VERSION ""

NS_ :

BS_:
BU_: ME SC01 BMS01 BMS PT
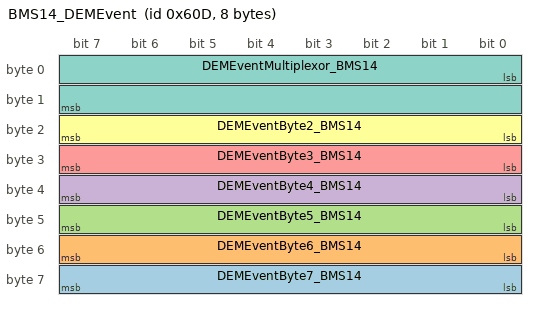
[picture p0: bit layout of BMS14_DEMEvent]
BO_ 1549 BMS14_DEMEvent: 8 BMS14
 SG_ DEMEventByte7_BMS14 : 63|8@0+ (1,0) [0|0] ""  PT
 SG_ DEMEventByte6_BMS14 : 55|8@0+ (1,0) [0|0] ""  PT
 SG_ DEMEventByte5_BMS14 : 47|8@0+ (1,0) [0|0] ""  PT
 SG_ DEMEventByte4_BMS14 : 39|8@0+ (1,0) [0|0] ""  PT
 SG_ DEMEventByte3_BMS14 : 31|8@0+ (1,0) [0|0] ""  PT
 SG_ DEMEventByte2_BMS14 : 23|8@0+ (1,0) [0|0] ""  PT
 SG_ DEMEventMultiplexor_BMS14 M : 0|16@1+ (1,0) [0|0] ""  PT

BO_ 1037 BMS14_DebugEventMap1: 8 BMS14
 SG_ DEM001_POWERUP_BMS14 : 11|2@0+ (1,0) [0|0] ""  PT
 SG_ DEM002_VOLTAGE_BRICK_OV_BMS14 : 13|2@0+ (1,0) [0|0] ""  PT
 SG_ DEM003_VOLTAGE_BRICK_UV_BMS14 : 15|2@0+ (1,0) [0|0] ""  PT
 SG_ DEM004_VOLTAGE_BRICK_SNA_BMS14 : 1|2@0+ (1,0) [0|0] ""  PT
 SG_ DEM005_VOLTAGE_BRICK_IMBAL_BMS14 : 3|2@0+ (1,0) [0|0] ""  PT
 SG_ DEM006_VOLTAGE_CAPCY_IMBAL_BMS14 : 5|2@0+ (1,0) [0|0] ""  PT
 SG_ DEM007_MODULET_HIGH_DELTA_BMS14 : 7|2@0+ (1,0) [0|0] ""  PT
 SG_ DEM008_VOLTAGE_PACK_UV_BMS14 : 25|2@0+ (1,0) [0|0] ""  PT
 SG_ DEM009_VOLTAGE_PACK_OV_BMS14 : 27|2@0+ (1,0) [0|0] ""  PT
 SG_ DEM010_VOLTAGE_PACK_PLAUSI_BMS14 : 29|2@0+ (1,0) [0|0] ""  PT
 SG_ DEM011_VOLTAGE_PCKLINK_MIS_BMS14 : 31|2@0+ (1,0) [0|0] ""  PT
 SG_ DEM012_VOLTAGE_BMS_SUPPLY_BMS14 : 17|2@0+ (1,0) [0|0] ""  PT
 SG_ DEM013_ADC_ERROR_BMS14 : 19|2@0+ (1,0) [0|0] ""  PT
 SG_ DEM014_MODULET_OT_BMS14 : 21|2@0+ (1,0) [0|0] ""  PT
 SG_ DEM015_MODULET_SNA_BMS14 : 23|2@0+ (1,0) [0|0] ""  PT
 SG_ DEM016_MODULET_LIMPHOME_BMS14 : 41|2@0+ (1,0) [0|0] ""  PT
 SG_ DEM017_COOLING_SYS_LHOME_BMS14 : 43|2@0+ (1,0) [0|0] ""  PT
 SG_ DEM018_HVIL_LIMPHOME_BMS14 : 45|2@0+ (1,0) [0|0] ""  PT
 SG_ DEM019_HVIL_ESS_INHIBIT_BMS14 : 47|2@0+ (1,0) [0|0] ""  PT
 SG_ DEM020_MODULET_CHANGE_BMS14 : 33|2@0+ (1,0) [0|0] ""  PT
 SG_ DEM021_LG_MAVD_FAULT_BMS14 : 35|2@0+ (1,0) [0|0] ""  PT
 SG_ DEM022_LG_RDV_FAULT_BMS14 : 37|2@0+ (1,0) [0|0] ""  PT
 SG_ DEM023_BMS_ONBOARDT_SNA_BMS14 : 39|2@0+ (1,0) [0|0] ""  PT
 SG_ DEM024_BMS_ONBOARDRH_OH_BMS14 : 57|2@0+ (1,0) [0|0] ""  PT
 SG_ DEM025_BMS_ONBOARDRH_SNA_BMS14 : 59|2@0+ (1,0) [0|0] ""  PT
 SG_ DEM026_CURRENT_OVERCHARGE_BMS14 : 61|2@0+ (1,0) [0|0] ""  PT
 SG_ DEM027_CURRENT_OVERDISCHGE_BMS14 : 63|2@0+ (1,0) [0|0] ""  PT
 SG_ DEM028_CURRENT_INVALID_BMS14 : 49|2@0+ (1,0) [0|0] ""  PT
 SG_ DEM029_CURRENT_SHORTCIRCT_BMS14 : 51|2@0+ (1,0) [0|0] ""  PT
 SG_ DEM030_CRASH_CAN_LATCH_BMS14 : 53|2@0+ (1,0) [0|0] ""  PT
 SG_ DEM031_EEPROM_FAIL_BMS14 : 55|2@0+ (1,0) [0|0] ""  PT

BO_ 1101 BMS14_DebugEventMap2: 8 BMS14
 SG_ DEM032_PCHG_PACKS_CONNECT_BMS14 : 9|2@0+ (1,0) [0|0] ""  PT
 SG_ DEM033_PCHG_ILLEGAL_PRCHG_BMS14 : 11|2@0+ (1,0) [0|0] ""  PT
 SG_ DEM034_PCHG_RELAY_FAIL_BMS14 : 13|2@0+ (1,0) [0|0] ""  PT
 SG_ DEM035_PCHG_NEG_WELD_BMS14 : 15|2@0+ (1,0) [0|0] ""  PT
 SG_ DEM036_PCHG_NEG_PULLIN_BMS14 : 1|2@0+ (1,0) [0|0] ""  PT
 SG_ DEM037_PCHG_SHORTCIRCUIT_BMS14 : 3|2@0+ (1,0) [0|0] ""  PT
 SG_ DEM038_PCHG_OPENCIRCUIT_BMS14 : 5|2@0+ (1,0) [0|0] ""  PT
 SG_ DEM039_PCHG_TIMEOUT_BMS14 : 7|2@0+ (1,0) [0|0] ""  PT
 SG_ DEM040_PCHG_FAILED_BMS14 : 25|2@0+ (1,0) [0|0] ""  PT
 SG_ DEM041_HVIL_SHUTDOWN_BMS14 : 27|2@0+ (1,0) [0|0] ""  PT
 SG_ DEM042_PCHG_POS_WELD_BMS14 : 29|2@0+ (1,0) [0|0] ""  PT
 SG_ DEM043_HV_LOCK_TRANSPORT_BMS14 : 31|2@0+ (1,0) [0|0] ""  PT
 SG_ DEM044_CTRS_END_OF_LIFE_BMS14 : 17|2@0+ (1,0) [0|0] ""  PT
 SG_ DEM045_CTRS_CTRPWRV_HI_BMS14 : 19|2@0+ (1,0) [0|0] ""  PT
 SG_ DEM046_CTRS_COILCURR_LOW_BMS14 : 21|2@0+ (1,0) [0|0] ""  PT
 SG_ DEM047_CTRS_COILCURR_HIGH_BMS14 : 23|2@0+ (1,0) [0|0] ""  PT
 SG_ DEM048_CTRS_CTRPWRV_LOW_BMS14 : 41|2@0+ (1,0) [0|0] ""  PT
 SG_ DEM049_CHGE_ILLEGAL_DISCHG_BMS14 : 43|2@0+ (1,0) [0|0] ""  PT
 SG_ DEM050_STARTUP_CONDITIONS_BMS14 : 45|2@0+ (1,0) [0|0] ""  PT
 SG_ DEM051_VOLTAGE_BMS_SUPPLYH_BMS14 : 47|2@0+ (1,0) [0|0] ""  PT
 SG_ DEM052_SAFETYSPI_FAIL_BMS14 : 33|2@0+ (1,0) [0|0] ""  PT
 SG_ DEM053_WATCHDOG_ERRORPIN_BMS14 : 35|2@0+ (1,0) [0|0] ""  PT
 SG_ DEM054_SAFESTATE_TRIGGERED_BMS14 : 37|2@0+ (1,0) [0|0] ""  PT
 SG_ DEM055_DEBUG_CMND_ACTIVE_BMS14 : 39|2@0+ (1,0) [0|0] ""  PT
 SG_ DEM056_CRASH_CAN_BMS14 : 57|2@0+ (1,0) [0|0] ""  PT
 SG_ DEM057_ISO_EXT_STRAT_4_BMS14 : 59|2@0+ (1,0) [0|0] ""  PT
 SG_ DEM058_ISO_EXT_RES_ERR_BMS14 : 61|2@0+ (1,0) [0|0] ""  PT
 SG_ DEM059_ISO_EXT_RES_WARN_BMS14 : 63|2@0+ (1,0) [0|0] ""  PT
 SG_ DEM060_ISO_INT_RES_ERR_BMS14 : 49|2@0+ (1,0) [0|0] ""  PT
 SG_ DEM061_ISO_INT_RES_WARN_BMS14 : 51|2@0+ (1,0) [0|0] ""  PT
 SG_ DEM062_EMERGENCY_OPERATION_BMS14 : 53|2@0+ (1,0) [0|0] ""  PT
 SG_ DEM063_ENDOFDRIVE_BMS14 : 55|2@0+ (1,0) [0|0] ""  PT

BO_ 1165 BMS14_DebugEventMap3: 8 BMS14
 SG_ DEM064_STRINGV_IMBALANCE_BMS14 : 9|2@0+ (1,0) [0|0] ""  PT
 SG_ DEM065_STRING_FAULT_BMS14 : 11|2@0+ (1,0) [0|0] ""  PT
 SG_ DEM066_ESS_FAULT_BMS14 : 13|2@0+ (1,0) [0|0] ""  PT
 SG_ DEM067_ISO_EXT_STRAT_3_BMS14 : 15|2@0+ (1,0) [0|0] ""  PT
 SG_ DEM068_MODULE_COUNT_INVALI_BMS14 : 1|2@0+ (1,0) [0|0] ""  PT
 SG_ DEM069_PT_MIA_BMS14 : 3|2@0+ (1,0) [0|0] ""  PT
 SG_ DEM070_BMSMIA_STRNGMSTR_01_BMS14 : 5|2@0+ (1,0) [0|0] ""  PT
 SG_ DEM071_BMSMIA_STRNGMSTR_05_BMS14 : 7|2@0+ (1,0) [0|0] ""  PT
 SG_ DEM072_BMSMIA_STRNGMSTR_09_BMS14 : 25|2@0+ (1,0) [0|0] ""  PT
 SG_ DEM073_BMSMIA_STRNGMSTR_13_BMS14 : 27|2@0+ (1,0) [0|0] ""  PT
 SG_ DEM074_BMSMIA_STRNGMSTR_17_BMS14 : 29|2@0+ (1,0) [0|0] ""  PT
 SG_ DEM075_BMSMIA_STRNGMSTR_21_BMS14 : 31|2@0+ (1,0) [0|0] ""  PT
 SG_ DEM076_BMSMIA_STRNGMSTR_25_BMS14 : 17|2@0+ (1,0) [0|0] ""  PT
 SG_ DEM077_BMSMIA_STRNGMSTR_29_BMS14 : 19|2@0+ (1,0) [0|0] ""  PT
 SG_ DEM078_BMSMIA_STRNGMSTR_33_BMS14 : 21|2@0+ (1,0) [0|0] ""  PT
 SG_ DEM079_BMSMIA_STRNGMSTR_37_BMS14 : 23|2@0+ (1,0) [0|0] ""  PT
 SG_ DEM080_BMSMIA_STRNGMSTR_41_BMS14 : 41|2@0+ (1,0) [0|0] ""  PT
 SG_ DEM081_BMSMIA_STRNGMSTR_45_BMS14 : 43|2@0+ (1,0) [0|0] ""  PT
 SG_ DEM082_BMSMIA_STRNGMSTR_49_BMS14 : 45|2@0+ (1,0) [0|0] ""  PT
 SG_ DEM083_BMSMIA_STRNGMSTR_53_BMS14 : 47|2@0+ (1,0) [0|0] ""  PT
 SG_ DEM084_BMSMIA_STRNGMSTR_57_BMS14 : 33|2@0+ (1,0) [0|0] ""  PT
 SG_ DEM085_BMSMIA_STRNGMSTR_61_BMS14 : 35|2@0+ (1,0) [0|0] ""  PT
 SG_ DEM086_ESSCURRENT_SHORT_BMS14 : 37|2@0+ (1,0) [0|0] ""  PT
 SG_ DEM087_PT_MIA_SHUTDOWN_BMS14 : 39|2@0+ (1,0) [0|0] ""  PT
 SG_ DEM088_OUTLET_NTC_HI_BMS14 : 57|2@0+ (1,0) [0|0] ""  PT
 SG_ DEM089_OUTLET_NTC_LO_BMS14 : 59|2@0+ (1,0) [0|0] ""  PT
 SG_ DEM090_BMSMIA_ESSMASTER_BMS14 : 61|2@0+ (1,0) [0|0] ""  PT
 SG_ DEM091_PCHG_RES_OVERHEAT_BMS14 : 63|2@0+ (1,0) [0|0] ""  PT
 SG_ DEM092_BMSMIA_STRNGSLAVE_0_BMS14 : 49|2@0+ (1,0) [0|0] ""  PT
 SG_ DEM093_BMSMIA_STRNGSLAVE_1_BMS14 : 51|2@0+ (1,0) [0|0] ""  PT
 SG_ DEM094_BMSMIA_STRNGSLAVE_2_BMS14 : 53|2@0+ (1,0) [0|0] ""  PT
 SG_ DEM095_BMSMIA_STRNGSLAVE_3_BMS14 : 55|2@0+ (1,0) [0|0] ""  PT

BO_ 1229 BMS14_DebugEventMap4: 8 BMS14
 SG_ DEM096_SC_STATE_SELFTEST_BMS14 : 9|2@0+ (1,0) [0|0] ""  PT
 SG_ DEM097_SC_STATE_TEMP_BMS14 : 11|2@0+ (1,0) [0|0] ""  PT
 SG_ DEM098_SC_STATE_VOLTAGE_BMS14 : 13|2@0+ (1,0) [0|0] ""  PT
 SG_ DEM099_SC_STATE_HVIL_BMS14 : 15|2@0+ (1,0) [0|0] ""  PT
 SG_ DEM100_SC_STATE_CONTACTORS_BMS14 : 1|2@0+ (1,0) [0|0] ""  PT
 SG_ DEM101_SC_STATE_CURRENT_BMS14 : 3|2@0+ (1,0) [0|0] ""  PT
 SG_ DEM102_SC_STATE_CANRX_BMS14 : 5|2@0+ (1,0) [0|0] ""  PT
 SG_ DEM103_SC_STATE_CRASH_BMS14 : 7|2@0+ (1,0) [0|0] ""  PT
 SG_ DEM104_SC_STATE_CCTRL_BMS14 : 25|2@0+ (1,0) [0|0] ""  PT
 SG_ DEM105_SC_STATE_CANTX_BMS14 : 27|2@0+ (1,0) [0|0] ""  PT
 SG_ DEM106_SC_STATE_THERMALEVT_BMS14 : 29|2@0+ (1,0) [0|0] ""  PT
 SG_ DEM107_SC_STATE_COOLANT_BMS14 : 31|2@0+ (1,0) [0|0] ""  PT
 SG_ DEM108_SC_SELFTEST_SFTY_UC_BMS14 : 17|2@0+ (1,0) [0|0] ""  PT
 SG_ DEM109_SC_TEMP_HIGH_BMS14 : 19|2@0+ (1,0) [0|0] ""  PT
 SG_ DEM110_SC_TEMP_NTC_OPEN_BMS14 : 21|2@0+ (1,0) [0|0] ""  PT
 SG_ DEM111_SC_TEMP_NTC_SHORT_BMS14 : 23|2@0+ (1,0) [0|0] ""  PT
 SG_ DEM112_CMB_DISCONNECTED_BMS14 : 41|2@0+ (1,0) [0|0] ""  PT
 SG_ DEM113_CMB_DEFECT_BMS14 : 43|2@0+ (1,0) [0|0] ""  PT
 SG_ DEM114_CMB_COMMERROR_BMS14 : 45|2@0+ (1,0) [0|0] ""  PT
 SG_ DEM115_SC_CURR_HALL_PWR_LO_BMS14 : 47|2@0+ (1,0) [0|0] ""  PT
 SG_ DEM116_SC_CURR_HALL_VHIGH_BMS14 : 33|2@0+ (1,0) [0|0] ""  PT
 SG_ DEM117_SC_CURR_HALL_ADC_BMS14 : 35|2@0+ (1,0) [0|0] ""  PT
 SG_ DEM118_SC_CURR_HALL_VLOW_BMS14 : 37|2@0+ (1,0) [0|0] ""  PT
 SG_ DEM119_SC_CURR_ISENSE_PWR_BMS14 : 39|2@0+ (1,0) [0|0] ""  PT
 SG_ DEM120_SC_CURR_ISENSE1_MIA_BMS14 : 57|2@0+ (1,0) [0|0] ""  PT
 SG_ DEM121_SC_CURR_ISENSE2_MIA_BMS14 : 59|2@0+ (1,0) [0|0] ""  PT
 SG_ DEM122_SC_CURR_ISENSE3_MIA_BMS14 : 61|2@0+ (1,0) [0|0] ""  PT
 SG_ DEM123_SC_CURR_ISENSE4_MIA_BMS14 : 63|2@0+ (1,0) [0|0] ""  PT
 SG_ DEM124_SC_CURR_ISENSE5_MIA_BMS14 : 49|2@0+ (1,0) [0|0] ""  PT
 SG_ DEM125_SC_CURR_ISENSE1_FLT_BMS14 : 51|2@0+ (1,0) [0|0] ""  PT
 SG_ DEM126_SC_CURR_ISENSE2_FLT_BMS14 : 53|2@0+ (1,0) [0|0] ""  PT
 SG_ DEM127_SC_CURR_ISENSE3_FLT_BMS14 : 55|2@0+ (1,0) [0|0] ""  PT

BO_ 1293 BMS14_DebugEventMap5: 8 BMS14
 SG_ DEM128_SC_CURR_ISENSE4_FLT_BMS14 : 9|2@0+ (1,0) [0|0] ""  PT
 SG_ DEM129_SC_CURR_ISENSE5_FLT_BMS14 : 11|2@0+ (1,0) [0|0] ""  PT
 SG_ DEM130_SC_CURR_OFFSET_BMS14 : 13|2@0+ (1,0) [0|0] ""  PT
 SG_ DEM131_SC_CURR_PLAUSI_BMS14 : 15|2@0+ (1,0) [0|0] ""  PT
 SG_ DEM132_SC_CURR_CHARGE_HIGH_BMS14 : 1|2@0+ (1,0) [0|0] ""  PT
 SG_ DEM133_SC_CURR_DSCHAR_HIGH_BMS14 : 3|2@0+ (1,0) [0|0] ""  PT
 SG_ DEM134_SC_V_CMB_SUMOFCELL_BMS14 : 5|2@0+ (1,0) [0|0] ""  PT
 SG_ DEM135_SC_V_SENSE_OPENWIRE_BMS14 : 7|2@0+ (1,0) [0|0] ""  PT
 SG_ DEM136_SC_V_CMB_DRV_FROZEN_BMS14 : 25|2@0+ (1,0) [0|0] ""  PT
 SG_ DEM137_SC_V_PACK_PLAUSI_BMS14 : 27|2@0+ (1,0) [0|0] ""  PT
 SG_ DEM138_SC_HVIL_HW_FLT_BMS14 : 29|2@0+ (1,0) [0|0] ""  PT
 SG_ DEM139_SC_HVIL_OPEN_BMS14 : 31|2@0+ (1,0) [0|0] ""  PT
 SG_ DEM140_SC_HVIL_TO_SUP_BMS14 : 17|2@0+ (1,0) [0|0] ""  PT
 SG_ DEM141_SC_HVIL_TO_CHAS_BMS14 : 19|2@0+ (1,0) [0|0] ""  PT
 SG_ DEM142_SC_HVIL_R_HIGH_BMS14 : 21|2@0+ (1,0) [0|0] ""  PT
 SG_ DEM143_SC_HVIL_SHORT_BMS14 : 23|2@0+ (1,0) [0|0] ""  PT
 SG_ DEM144_SC_CN_ISO_FAIL_BMS14 : 41|2@0+ (1,0) [0|0] ""  PT
 SG_ DEM145_HVIL_SYS_BMS14 : 43|2@0+ (1,0) [0|0] ""  PT
 SG_ DEM146_SC_CN_POS1_WELDED_BMS14 : 45|2@0+ (1,0) [0|0] ""  PT
 SG_ DEM147_SC_CN_NEG1_WELDED_BMS14 : 47|2@0+ (1,0) [0|0] ""  PT
 SG_ DEM148_SC_CN_POS2_WELDED_BMS14 : 33|2@0+ (1,0) [0|0] ""  PT
 SG_ DEM149_SC_CN_NEG2_WELDED_BMS14 : 35|2@0+ (1,0) [0|0] ""  PT
 SG_ DEM150_SC_CN_POS3_WELDED_BMS14 : 37|2@0+ (1,0) [0|0] ""  PT
 SG_ DEM151_SC_CN_NEG3_WELDED_BMS14 : 39|2@0+ (1,0) [0|0] ""  PT
 SG_ DEM152_SC_CN_HIGH_CY_BMS14 : 57|2@0+ (1,0) [0|0] ""  PT
 SG_ DEM153_SC_CN_ISOANDPOTWELD_BMS14 : 59|2@0+ (1,0) [0|0] ""  PT
 SG_ DEM154_SC_TEMP_PLAUSI_BMS14 : 61|2@0+ (1,0) [0|0] ""  PT
 SG_ DEM155_SC_CURR_HALL_PWR_HI_BMS14 : 63|2@0+ (1,0) [0|0] ""  PT
 SG_ DEM156_SC_PYRO_TRIGGERED_BMS14 : 49|2@0+ (1,0) [0|0] ""  PT
 SG_ DEM157_SC_PYRO_OPEN_BMS14 : 51|2@0+ (1,0) [0|0] ""  PT
 SG_ DEM158_AUX_CTRS_END_OF_LIF_BMS14 : 53|2@0+ (1,0) [0|0] ""  PT
 SG_ DEM159_SC_CANRX_PT_MIA_BMS14 : 55|2@0+ (1,0) [0|0] ""  PT

BO_ 1357 BMS14_DebugEventMap6: 8 BMS14
 SG_ DEM160_SC_CANRX_PT_CRCALIV_BMS14 : 9|2@0+ (1,0) [0|0] ""  PT
 SG_ DEM161_SC_CANRX_LIN_SHUTDN_BMS14 : 11|2@0+ (1,0) [0|0] ""  PT
 SG_ DEM162_SC_CANRX_LIN_MIA_BMS14 : 13|2@0+ (1,0) [0|0] ""  PT
 SG_ DEM163_SC_CRASH1_BMS14 : 15|2@0+ (1,0) [0|0] ""  PT
 SG_ DEM164_SC_CRASH2_BMS14 : 1|2@0+ (1,0) [0|0] ""  PT
 SG_ DEM165_SC_CRASHCAN_BMS14 : 3|2@0+ (1,0) [0|0] ""  PT
 SG_ DEM166_SC_CCTRL_SELFTEST_BMS14 : 5|2@0+ (1,0) [0|0] ""  PT
 SG_ DEM167_SC_CCTRL_DRIVER_FAU_BMS14 : 7|2@0+ (1,0) [0|0] ""  PT
 SG_ DEM168_SC_CCTRL_HISIDESTCL_BMS14 : 25|2@0+ (1,0) [0|0] ""  PT
 SG_ DEM169_SC_CCTRL_HISIDESTOP_BMS14 : 27|2@0+ (1,0) [0|0] ""  PT
 SG_ DEM170_SC_CCTRL_LOSIDESTCL_BMS14 : 29|2@0+ (1,0) [0|0] ""  PT
 SG_ DEM171_SC_CCTRL_HVCNDITION_BMS14 : 31|2@0+ (1,0) [0|0] ""  PT
 SG_ DEM172_SC_CCTRL_POS1_OPN_BMS14 : 17|2@0+ (1,0) [0|0] ""  PT
 SG_ DEM173_SC_CCTRL_POS2_OPN_BMS14 : 19|2@0+ (1,0) [0|0] ""  PT
 SG_ DEM174_SC_CCTRL_POS3_OPN_BMS14 : 21|2@0+ (1,0) [0|0] ""  PT
 SG_ DEM175_SC_CCTRL_NEG1_OPN_BMS14 : 23|2@0+ (1,0) [0|0] ""  PT
 SG_ DEM176_SC_CCTRL_NEG2_OPN_BMS14 : 41|2@0+ (1,0) [0|0] ""  PT
 SG_ DEM177_SC_CCTRL_PRE2_OPN_BMS14 : 43|2@0+ (1,0) [0|0] ""  PT
 SG_ DEM178_SC_CCTRL_PRE1_OPN_BMS14 : 45|2@0+ (1,0) [0|0] ""  PT
 SG_ DEM179_SC_CCTRL_LOSIDESTOP_BMS14 : 47|2@0+ (1,0) [0|0] ""  PT
 SG_ DEM180_SC_CCTRL_UNEXPECTED_BMS14 : 33|2@0+ (1,0) [0|0] ""  PT
 SG_ DEM181_SC_V_OUT_OF_RANGE_BMS14 : 35|2@0+ (1,0) [0|0] ""  PT
 SG_ DEM182_SC_V_LATCHED_UVOV_BMS14 : 37|2@0+ (1,0) [0|0] ""  PT
 SG_ DEM183_ISO_EXT_STRAT_2_BMS14 : 39|2@0+ (1,0) [0|0] ""  PT
 SG_ DEM184_SC_CANTX_CTRS_BMS14 : 57|2@0+ (1,0) [0|0] ""  PT
 SG_ DEM185_SC_CANTX_HVIL_BMS14 : 59|2@0+ (1,0) [0|0] ""  PT
 SG_ DEM186_SC_CANTX_ISOL_BMS14 : 61|2@0+ (1,0) [0|0] ""  PT
 SG_ DEM187_SC_SBC_WATCHDOG_BMS14 : 63|2@0+ (1,0) [0|0] ""  PT
 SG_ DEM188_SC_SBC_FAULT_BMS14 : 49|2@0+ (1,0) [0|0] ""  PT
 SG_ DEM189_SC_WATCHDOG_BMS14 : 51|2@0+ (1,0) [0|0] ""  PT
 SG_ DEM190_SC_SELFTEST_RAM_BMS14 : 53|2@0+ (1,0) [0|0] ""  PT
 SG_ DEM191_SC_SELFTEST_FLASH_BMS14 : 55|2@0+ (1,0) [0|0] ""  PT

BO_ 1421 BMS14_DebugEventMap7: 8 BMS14
 SG_ DEM192_CMB_ONBOARDRH_OH_BMS14 : 9|2@0+ (1,0) [0|0] ""  PT
 SG_ DEM193_CMB_ONBOARDRH_SNA_BMS14 : 11|2@0+ (1,0) [0|0] ""  PT
 SG_ DEM194_CMB_ONBOARDT_OT_BMS14 : 13|2@0+ (1,0) [0|0] ""  PT
 SG_ DEM195_CMB_ONBOARDT_CHANGE_BMS14 : 15|2@0+ (1,0) [0|0] ""  PT
 SG_ DEM196_PRESSURE_CHANGE_BMS14 : 1|2@0+ (1,0) [0|0] ""  PT
 SG_ DEM197_PRESSURE_OVER_BMS14 : 3|2@0+ (1,0) [0|0] ""  PT
 SG_ DEM198_PRESSURE_UNDER_BMS14 : 5|2@0+ (1,0) [0|0] ""  PT
 SG_ DEM199_PRESSURE_INVALID_BMS14 : 7|2@0+ (1,0) [0|0] ""  PT
 SG_ DEM200_THERMAL_EVENT_BMS14 : 25|2@0+ (1,0) [0|0] ""  PT
 SG_ DEM201_CMB_ONBOARDT_SNA_BMS14 : 27|2@0+ (1,0) [0|0] ""  PT
 SG_ DEM202_REPLACE_DESICCANT_BMS14 : 29|2@0+ (1,0) [0|0] ""  PT
 SG_ DEM203_COOLANT_FLOOD_FAULT_BMS14 : 31|2@0+ (1,0) [0|0] ""  PT
 SG_ DEM204_LOW_BRICKCAPACITY_BMS14 : 17|2@0+ (1,0) [0|0] ""  PT
 SG_ DEM205_BMS_ONBOARDT_OT_BMS14 : 19|2@0+ (1,0) [0|0] ""  PT
 SG_ DEM206_HUMIDITY_CHANGE_BMS14 : 21|2@0+ (1,0) [0|0] ""  PT
 SG_ DEM207_ISENSE_SUPPLY_CURR_BMS14 : 23|2@0+ (1,0) [0|0] ""  PT
 SG_ DEM208_SOC_LOW_BMS14 : 41|2@0+ (1,0) [0|0] ""  PT
 SG_ DEM209_SOC_TOOLOW_BMS14 : 43|2@0+ (1,0) [0|0] ""  PT
 SG_ DEM210_SOC_TOOHIGH_BMS14 : 45|2@0+ (1,0) [0|0] ""  PT
 SG_ DEM211_BALANCING_REQUIRED_BMS14 : 47|2@0+ (1,0) [0|0] ""  PT
 SG_ DEM212_DEEP_DISCHARGE_BMS14 : 33|2@0+ (1,0) [0|0] ""  PT
 SG_ DEM213_CAN1_BUS_OFF_BMS14 : 35|2@0+ (1,0) [0|0] ""  PT
 SG_ DEM214_CAN2_BUS_OFF_BMS14 : 37|2@0+ (1,0) [0|0] ""  PT
 SG_ DEM215_CAN3_BUS_OFF_BMS14 : 39|2@0+ (1,0) [0|0] ""  PT
 SG_ DEM216_OUTLET_NTC_RATNAL_BMS14 : 57|2@0+ (1,0) [0|0] ""  PT
 SG_ DEM217_FUSE_PACK_BMS14 : 59|2@0+ (1,0) [0|0] ""  PT
 SG_ DEM218_FUSE_B_OPEN_BMS14 : 61|2@0+ (1,0) [0|0] ""  PT
 SG_ DEM219_FUSE_C_OPEN_BMS14 : 63|2@0+ (1,0) [0|0] ""  PT
 SG_ DEM220_FUSE_D_OPEN_BMS14 : 49|2@0+ (1,0) [0|0] ""  PT
 SG_ DEM221_FUSE_E_OPEN_BMS14 : 51|2@0+ (1,0) [0|0] ""  PT
 SG_ DEM222_PUMP_DRY_RUN_BMS14 : 53|2@0+ (1,0) [0|0] ""  PT
 SG_ DEM223_PUMP_PERFORMANCE_BMS14 : 55|2@0+ (1,0) [0|0] ""  PT

BO_ 1485 BMS14_DebugEventMap8: 8 BMS14
 SG_ DEM224_PUMP_LIN_FAILURE_BMS14 : 9|2@0+ (1,0) [0|0] ""  PT
 SG_ DEM225_PUMP_SUPPLY_VOLTAGE_BMS14 : 11|2@0+ (1,0) [0|0] ""  PT
 SG_ DEM226_PUMP_RECOVERY_FAIL_BMS14 : 13|2@0+ (1,0) [0|0] ""  PT
 SG_ DEM227_CTR_POS_OPENED_BMS14 : 15|2@0+ (1,0) [0|0] ""  PT
 SG_ DEM228_CTR_NEG_OPENED_BMS14 : 1|2@0+ (1,0) [0|0] ""  PT
 SG_ DEM229_STRSET_SLAVE1_FAULT_BMS14 : 3|2@0+ (1,0) [0|0] ""  PT
 SG_ DEM230_STRSET_SLAVE2_FAULT_BMS14 : 5|2@0+ (1,0) [0|0] ""  PT
 SG_ DEM231_CTRSAUX_CLFAIL_HVON_BMS14 : 7|2@0+ (1,0) [0|0] ""  PT
 SG_ DEM232_CTRSAUX_CLFAIL_VDIF_BMS14 : 25|2@0+ (1,0) [0|0] ""  PT
 SG_ DEM233_CTRSAUX_POS1_OPENED_BMS14 : 27|2@0+ (1,0) [0|0] ""  PT
 SG_ DEM234_CTRSAUX_NEG1_OPENED_BMS14 : 29|2@0+ (1,0) [0|0] ""  PT
 SG_ DEM235_CTRSAUX_POS1_WELDED_BMS14 : 31|2@0+ (1,0) [0|0] ""  PT
 SG_ DEM236_CTRSAUX_NEG1_WELDED_BMS14 : 17|2@0+ (1,0) [0|0] ""  PT
 SG_ DEM237_CTRSAUX_POS1_PULLIN_BMS14 : 19|2@0+ (1,0) [0|0] ""  PT
 SG_ DEM238_CTRSAUX_NEG1_PULLIN_BMS14 : 21|2@0+ (1,0) [0|0] ""  PT
 SG_ DEM239_INLET_NTC_RATNAL_BMS14 : 23|2@0+ (1,0) [0|0] ""  PT
 SG_ DEM240_INLET_NTC_HI_BMS14 : 41|2@0+ (1,0) [0|0] ""  PT
 SG_ DEM241_INLET_NTC_LO_BMS14 : 43|2@0+ (1,0) [0|0] ""  PT
 SG_ DEM242_VOLTAGE_LINK2_RATNA_BMS14 : 45|2@0+ (1,0) [0|0] ""  PT
 SG_ DEM243_VOLTAGE_LINK2_HI_BMS14 : 47|2@0+ (1,0) [0|0] ""  PT
 SG_ DEM244_VOLTAGE_LINK2_LO_BMS14 : 33|2@0+ (1,0) [0|0] ""  PT
 SG_ DEM245_CMB_ONBOARD_IMPOSSI_BMS14 : 35|2@0+ (1,0) [0|0] ""  PT
 SG_ DEM246_VOLTAGE_LINK1_HI_BMS14 : 37|2@0+ (1,0) [0|0] ""  PT
 SG_ DEM247_VOLTAGE_LINK1_LO_BMS14 : 39|2@0+ (1,0) [0|0] ""  PT
 SG_ DEM248_NTC_SUPPLY_LO_BMS14 : 57|2@0+ (1,0) [0|0] ""  PT
 SG_ DEM249_NTC_SUPPLY_HI_BMS14 : 59|2@0+ (1,0) [0|0] ""  PT
 SG_ DEM250_VOLTAGE_LINK3_RATNA_BMS14 : 61|2@0+ (1,0) [0|0] ""  PT
 SG_ DEM251_VOLTAGE_LINK3_HI_BMS14 : 63|2@0+ (1,0) [0|0] ""  PT
 SG_ DEM252_VOLTAGE_LINK3_LO_BMS14 : 49|2@0+ (1,0) [0|0] ""  PT
 SG_ DEM253_BALANCING_STUCK_BMS14 : 51|2@0+ (1,0) [0|0] ""  PT
 SG_ DEM254_ARM_EXCEPTION_BMS14 : 53|2@0+ (1,0) [0|0] ""  PT
 SG_ DEM255_ERROR_HOOKS_BMS14 : 55|2@0+ (1,0) [0|0] ""  PT

BO_ 845 BMS14_DebugEventMap9: 8 BMS14
 SG_ DEM256_XCP_CAL_CHANGE_BMS14 : 9|2@0+ (1,0) [0|0] ""  PT
 SG_ DEM257_XCP_CAL_PERM_CHANGE_BMS14 : 11|2@0+ (1,0) [0|0] ""  PT
 SG_ DEM258_TASK_TIME_OVERFLOW_BMS14 : 13|2@0+ (1,0) [0|0] ""  PT
 SG_ DEM259_ISO_CIRCUIT_BMS14 : 15|2@0+ (1,0) [0|0] ""  PT
 SG_ DEM260_COOLANT_MOIST_FAULT_BMS14 : 1|2@0+ (1,0) [0|0] ""  PT
 SG_ DEM261_COOLANT_FLOOD_WARN_BMS14 : 3|2@0+ (1,0) [0|0] ""  PT
 SG_ DEM262_COOLANT_MOIST_WARN_BMS14 : 5|2@0+ (1,0) [0|0] ""  PT
 SG_ DEM263_MODULET_IMPLAUSIBLE_BMS14 : 7|2@0+ (1,0) [0|0] ""  PT
 SG_ DEM264_REQUEST_ON_WITH_HV__BMS14 : 25|2@0+ (1,0) [0|0] ""  PT
 SG_ DEM265_CSERS_PCODE_BMS14 : 27|2@0+ (1,0) [0|0] ""  PT
 SG_ DEM266_PRELIM_CNTR_CL_FAIL_BMS14 : 29|2@0+ (1,0) [0|0] ""  PT
 SG_ DEM267_FLUIDLVL_LOW_BMS14 : 31|2@0+ (1,0) [0|0] ""  PT
 SG_ DEM268_FLUIDLVL_FAILURE_BMS14 : 17|2@0+ (1,0) [0|0] ""  PT
 SG_ DEM269_SC_COOLANT_CONTAM_BMS14 : 19|2@0+ (1,0) [0|0] ""  PT
 SG_ DEM270_SC_COOLANT_MIA_BMS14 : 21|2@0+ (1,0) [0|0] ""  PT
 SG_ DEM271_PRESSURE_VHI_BMS14 : 23|2@0+ (1,0) [0|0] ""  PT
 SG_ DEM272_PRESSURE_VLO_BMS14 : 41|2@0+ (1,0) [0|0] ""  PT
 SG_ DEM273_SC_COOLANT_FAIL_BMS14 : 43|2@0+ (1,0) [0|0] ""  PT
 SG_ DEM274_CTRSAUX_POS2_OPENED_BMS14 : 45|2@0+ (1,0) [0|0] ""  PT
 SG_ DEM275_CTRSAUX_POS3_OPENED_BMS14 : 47|2@0+ (1,0) [0|0] ""  PT
 SG_ DEM276_CTRSAUX_POS2_WELDED_BMS14 : 33|2@0+ (1,0) [0|0] ""  PT
 SG_ DEM277_CTRSAUX_POS3_WELDED_BMS14 : 35|2@0+ (1,0) [0|0] ""  PT
 SG_ DEM278_CTRSAUX_POS2_PULLIN_BMS14 : 37|2@0+ (1,0) [0|0] ""  PT
 SG_ DEM279_CTRSAUX_POS3_PULLIN_BMS14 : 39|2@0+ (1,0) [0|0] ""  PT
 SG_ DEM280_CMB_HUMIDITY_TEMP_C_BMS14 : 57|2@0+ (1,0) [0|0] ""  PT
 SG_ DEM281_THERMAL_EVENT_CMB_R_BMS14 : 59|2@0+ (1,0) [0|0] ""  PT
 SG_ DEM282_CUS_BRICKOV_BMS14 : 61|2@0+ (1,0) [0|0] ""  PT
 SG_ DEM283_CUS_BRICKUV_BMS14 : 63|2@0+ (1,0) [0|0] ""  PT
 SG_ DEM284_CUS_OVERCHRG_BMS14 : 49|2@0+ (1,0) [0|0] ""  PT
 SG_ DEM285_CUS_OVERDCHRG_BMS14 : 51|2@0+ (1,0) [0|0] ""  PT
 SG_ DEM286_CUS_CURRENT_CHG_BMS14 : 53|2@0+ (1,0) [0|0] ""  PT
 SG_ DEM287_CUS_CURRENT_DCHG_BMS14 : 55|2@0+ (1,0) [0|0] ""  PT

BO_ 1613 SC14_DebugSlowMpex: 8 SC14
 SG_ FeeInitStatus_SC14 m43 : 23|16@0+ (1,0) [0|65535] ""  PT
 SG_ pressureFiltered_SC14 m22 : 47|8@0+ (0.4,0) [0|102] "psi"  PT
 SG_ shunt2IntegralAs_SC14 m46 : 23|32@0- (1,0) [-2147483648|2147483647] "As"  PT
 SG_ shunt1IntegralAs_SC14 m45 : 31|32@0- (1,0) [-2147483648|2147483647] "As"  PT
 SG_ selfTestStartupFault_SC14 m22 : 39|8@0+ (1,0) [0|255] ""  PT
 SG_ sbcARTimerStatus_SC14 m45 : 11|4@0+ (1,0) [0|15] ""  PT
 SG_ sbcARTimerValue_SC14 m45 : 23|8@0+ (1,0) [0|255] "s"  PT
 SG_ ESM_EFUSE_SAFETY_CHECK_FAIL_SC14 m21 : 41|1@0+ (1,0) [0|0] ""  PT
 SG_ ESM_EFUSE_SINGLEBIT_ERROR_SC14 m21 : 42|1@0+ (1,0) [0|0] ""  PT
 SG_ cmbVAIndex_SC14 m44 : 31|8@0+ (1,0) [0|0] ""  PT
 SG_ minVACMB_SC14 m44 : 39|16@0+ (0.0001,0) [0|6.5] "V"  PT
 SG_ maxVACMB_SC14 m44 : 55|16@0+ (0.0001,0) [0|6.5] "V"  PT
 SG_ pumpInternalFaultError_SC14 m23 : 16|1@0+ (1,0) [0|0] ""  PT
 SG_ pumpShortCircuitError_SC14 m23 : 17|1@0+ (1,0) [0|0] ""  PT
 SG_ pumpElectricError_SC14 m23 : 19|2@0+ (1,0) [0|0] ""  PT
 SG_ pumpPostRunMode_SC14 m23 : 22|3@0+ (1,0) [0|0] ""  PT
 SG_ pumpRsError_SC14 m23 : 23|1@0+ (1,0) [0|0] ""  PT
 SG_ pumpWakeUpStatus_SC14 m23 : 25|2@0+ (1,0) [0|0] ""  PT
 SG_ pumpRpmMonStat_SC14 m23 : 27|2@0+ (1,0) [0|0] ""  PT
 SG_ pumpPwmInStat_SC14 m23 : 29|2@0+ (1,0) [0|0] ""  PT
 SG_ pumpDiagTriggered_SC14 m23 : 30|1@0+ (1,0) [0|0] ""  PT
 SG_ pumpHwFault_SC14 m23 : 31|1@0+ (1,0) [0|0] ""  PT
 SG_ pumpPumpState_SC14 m23 : 34|3@0+ (1,0) [0|0] ""  PT
 SG_ pumpBlockError_SC14 m23 : 36|2@0+ (1,0) [0|0] ""  PT
 SG_ pumpLinError_SC14 m23 : 37|1@0+ (1,0) [0|0] ""  PT
 SG_ pumpDryRun_SC14 m23 : 39|2@0+ (1,0) [0|0] ""  PT
 SG_ pumpOverCurrent_SC14 m23 : 41|2@0+ (1,0) [0|0] ""  PT
 SG_ pumpVoltageDeratingError_SC14 m23 : 42|1@0+ (1,0) [0|0] ""  PT
 SG_ pumpSupVoltageError_SC14 m23 : 44|2@0+ (1,0) [0|0] ""  PT
 SG_ pumpUnderVoltage_SC14 m23 : 45|1@0+ (1,0) [0|0] ""  PT
 SG_ pumpOverVoltage_SC14 m23 : 46|1@0+ (1,0) [0|0] ""  PT
 SG_ pumpTempProtect_SC14 m23 : 47|1@0+ (1,0) [0|0] ""  PT
 SG_ pumpOverTempDeratingErr_SC14 m23 : 48|1@0+ (1,0) [0|0] ""  PT
 SG_ pumpOverTemperature_SC14 m23 : 50|2@0+ (1,0) [0|0] ""  PT
 SG_ cmbSM30MinSettleTime_SC14 m44 : 15|16@0+ (1,0) [0|65535] "ms"  PT
 SG_ cmbSM30SettleTimeFault_SC14 m32 : 42|1@0+ (1,0) [0|1] ""  PT
 SG_ pressure2_SC14 m22 : 15|8@0+ (0.4,0) [0|102] "psi"  PT
 SG_ cmbSM29ScoutTempIndex_SC14 m42 : 15|8@0+ (1,0) [0|255] ""  PT
 SG_ cmbSM19ScoutPDO_SC14 m42 : 55|16@0+ (0.0001,0) [0|6.5] "V"  PT
 SG_ cmbMaxSM15ratio_SC14 m41 : 39|16@0+ (0.00390625,0) [0|255.99609375] ""  PT
 SG_ cmbMinSM15ratio_SC14 m41 : 55|16@0+ (0.00390625,0) [0|255.99609375] ""  PT
 SG_ cmbMinSM17Ratio m42 : 39|16@0+ (0.00390625,0) [0|255.99609375] ""  PT
 SG_ cmbMaxSM17Ratio m42 : 23|16@0+ (0.00390625,0) [0|255.99609375] ""  PT
 SG_ cmbMaxSM16DiffC2S_SC14 m41 : 23|16@0+ (0.2,0) [0|13107] "mV"  PT
 SG_ isolationResInternRelaxed_SC14 m32 : 23|16@0+ (2,0) [0|130000] "kOhm"  PT
 SG_ pressureSensH2Concentr_SC14 m40 : 55|16@0+ (0.0025,0) [0|163.8375] "% H2"  PT
 SG_ pressureSensIntakePres_SC14 m40 : 39|16@0+ (0.0078125,-250) [-250|251.99] "kPa"  PT
 SG_ pressureSensIntakeTemp_SC14 m40 : 23|16@0+ (0.03125,-273) [-273|1734.96875] "C"  PT
 SG_ pressureSensRelHumidity_SC14 m40 : 15|8@0+ (0.4,0) [0|100] "%"  PT
 SG_ isolationSelftestMaxDiff_SC14 m32 : 39|8@0+ (0.1,0) [0|25.5] "V"  PT
 SG_ FEESector2Flags_SC14 m22 : 23|16@0+ (1,0) [0|0] ""  PT
 SG_ appTask500HzMaxAvg_SC14 m41 : 15|8@0+ (0.02,0) [0|5.1] "ms"  PT
 SG_ safetyHangLastLinkReg_SC14 m39 : 23|32@0+ (1,0) [0|4294967295] ""  PT
 SG_ safetyHangPresentLinkReg_SC14 m38 : 23|32@0+ (1,0) [0|4294967295] ""  PT
 SG_ safetyHangDataFaultStatus_SC14 m37 : 23|32@0+ (1,0) [0|4294967295] ""  PT
 SG_ safetyHangDataFaultAddr_SC14 m36 : 23|32@0+ (1,0) [0|4294967295] ""  PT
 SG_ safetyHangLastARMMode_SC14 m35 : 63|8@0+ (1,0) [0|255] ""  PT
 SG_ safetyHangPresARMMode_SC14 m35 : 55|8@0+ (1,0) [0|255] ""  PT
 SG_ safetyHangESMGrp3Reg_SC14 m35 : 23|32@0+ (1,0) [0|4294967295] ""  PT
 SG_ safetyHangInstrFaultStatus_SC14 m34 : 23|32@0+ (1,0) [0|4294967295] ""  PT
 SG_ safetyHangInstrFaultAddr_SC14 m33 : 23|32@0+ (1,0) [0|4294967295] ""  PT
 SG_ pressure_SC14 m4 : 63|8@0+ (0.4,0) [0|102] "psi"  PT
 SG_ cmbMaxSM33Diff_SC14 m31 : 15|8@0+ (0.001,0) [0|0.255] "V"  PT
 SG_ cmbMinSM29Diff_SC14 m17 : 15|8@0+ (0.001,0) [0|0.255] "V"  PT
 SG_ cmbSM4MinIndex_SC14 m24 : 15|8@0+ (1,0) [0|0] ""  PT
 SG_ cmbSM4DiffC2_SC14 m31 : 23|16@0+ (0.0001,0) [0|6.5] "V"  PT
 SG_ cmbMinSM4Diff_SC14 m31 : 39|16@0+ (0.0001,0) [0|6.5] "V"  PT
 SG_ cmbMaxSM4Diff_SC14 m21 : 55|16@0+ (0.0001,0) [0|6.5] "V"  PT
 SG_ cmbSM27MinIndex_SC14 m15 : 63|8@0+ (1,0) [0|0] ""  PT
 SG_ cmbSM27DiffC2_SC14 m24 : 55|16@0+ (0.0001,0) [0|6.5] "V"  PT
 SG_ cmbMinSM27Diff_SC14 m31 : 55|16@0+ (0.0001,0) [0|6.5] "V"  PT
 SG_ cmbMaxSM27Diff_SC14 m25 : 55|16@0+ (0.0001,0) [0|6.5] "V"  PT
 SG_ adcDriverFail_SC14 m4 : 51|4@0+ (1,0) [0|0] ""  PT
 SG_ mainUcHvilState_SC14 m32 : 41|2@0+ (1,0) [0|0] ""  PT
 SG_ mainUcIntIsoErr_SC14 m32 : 13|2@0+ (1,0) [0|0] ""  PT
 SG_ mainUcExtIsoErr_SC14 m32 : 15|2@0+ (1,0) [0|0] ""  PT
 SG_ safetyUcThermalStatus_SC14 m32 : 9|2@0+ (1,0) [0|0] ""  PT
 SG_ mainUcThermalStatus_SC14 m32 : 11|2@0+ (1,0) [0|0] ""  PT
 SG_ selfTestErrorAddress_SC14 m30 : 23|32@0+ (1,0) [0|4294967295] ""  PT
 SG_ selfTestDataFaultStatus_SC14 m29 : 23|32@0+ (1,0) [0|4294967295] ""  PT
 SG_ selfTestInstrFaultAddr_SC14 m28 : 23|32@0+ (1,0) [0|4294967295] ""  PT
 SG_ selfTestDataFaultAddr_SC14 m27 : 23|32@0+ (1,0) [0|4294967295] ""  PT
 SG_ selfTestInstrFaultStatus_SC14 m26 : 23|32@0+ (1,0) [0|4294967295] ""  PT
 SG_ internalIsolationError_SC14 m25 : 11|2@0+ (1,0) [0|0] ""  PT
 SG_ externalIsolationError_SC14 m25 : 13|2@0+ (1,0) [0|0] ""  PT
 SG_ isolationTestState_SC14 m25 : 9|2@0+ (1,0) [0|0] ""  PT
 SG_ isolationResistanceIntern_SC14 m25 : 23|16@0+ (2,0) [0|130000] "kOhm"  PT
 SG_ isolationResistanceExtern_SC14 m25 : 39|16@0+ (2,0) [0|130000] "kOhm"  PT
 SG_ maxAdolV13Diff_SC14 m24 : 23|16@0+ (0.0001,0) [0|6.5] "V"  PT
 SG_ maxAdolV7Diff_SC14 m24 : 39|16@0+ (0.0001,0) [0|6.5] "V"  PT
 SG_ pumpType_SC14 m23 : 15|8@0+ (1,0) [0|0] ""  PT
 SG_ pumpPhaseCurrent_SC14 m18 : 47|8@0+ (0.1,0) [0|0] "A"  PT
 SG_ hvWithstandTestQual_SC14 m21 : 15|8@0+ (1,0) [0|255] ""  PT
 SG_ ESM_RAM_ODD_ADDR_UNCORR_SC14 m21 : 18|1@0+ (1,0) [0|0] ""  PT
 SG_ ESM_RAM_EVEN_ADDR_UNCORR_SC14 m21 : 17|1@0+ (1,0) [0|0] ""  PT
 SG_ ESM_FMC_UNCORR_ERR_SC14 m21 : 40|1@0+ (1,0) [0|0] ""  PT
 SG_ ESM_RAM_ODDECC_UNCORR_SC14 m21 : 23|1@0+ (1,0) [0|0] ""  PT
 SG_ ESM_RAM_EVENECC_UNCORR_SC14 m21 : 22|1@0+ (1,0) [0|0] ""  PT
 SG_ ESM_EFUSE_FARM_ERR_SC14 m21 : 21|1@0+ (1,0) [0|0] ""  PT
 SG_ ESM_RTI_WWD_NMI_SC14 m21 : 20|1@0+ (1,0) [0|0] ""  PT
 SG_ ESM_TCM_ECC_LIVE_LOCK_SC14 m21 : 19|1@0+ (1,0) [0|0] ""  PT
 SG_ ESM_RAM_ODD_UNCORR_ERR_SC14 m21 : 16|1@0+ (1,0) [0|0] ""  PT
 SG_ ESM_RAM_EVEN_UNCORR_ERR_SC14 m21 : 31|1@0+ (1,0) [0|0] ""  PT
 SG_ ESM_FMC_ADDR_UNCORR_ERR_SC14 m21 : 30|1@0+ (1,0) [0|0] ""  PT
 SG_ ESM_CCM4_COMPARE_FAULT_SC14 m21 : 29|1@0+ (1,0) [0|0] ""  PT
 SG_ ESM_RAM_ODD_CORR_ERR_SC14 m21 : 28|1@0+ (1,0) [0|0] ""  PT
 SG_ ESM_RAM_EVEN_CORR_ERR_SC14 m21 : 27|1@0+ (1,0) [0|0] ""  PT
 SG_ ESM_CLK_MONITOR_SC14 m21 : 26|1@0+ (1,0) [0|0] ""  PT
 SG_ ESM_PLL_SLIP_SC14 m21 : 25|1@0+ (1,0) [0|0] ""  PT
 SG_ ESM_FMC_CORR_ERR_SC14 m21 : 24|1@0+ (1,0) [0|0] ""  PT
 SG_ analogMMCUSleepTrigger_SC14 m20 : 55|8@0+ (0.015,0) [0|0] "V"  PT
 SG_ analogPyroLSDStatus_SC14 m20 : 63|8@0+ (0.015,0) [0|0] "V"  PT
 SG_ analogGPIO2Volt_SC14 m19 : 47|8@0+ (0.1,0) [0|25] "V"  PT
 SG_ analogGPIO2Current_SC14 m19 : 55|8@0+ (0.015,0) [0|3.825] "A"  PT
 SG_ analogGPIO1Volt_SC14 m19 : 63|8@0+ (0.1,0) [0|25] "V"  PT
 SG_ analogGPIO1Current_SC14 m20 : 15|8@0+ (0.015,0) [0|3.825] "A"  PT
 SG_ currentModuleMax_SC14 m1 : 55|16@0+ (0.1,-3200) [-3200|3200] "A"  PT
 SG_ currentModuleMin_SC14 m1 : 39|16@0+ (0.1,-3200) [-3200|3200] "A"  PT
 SG_ cmbSumOfCellSTATRef_SC14 m20 : 39|16@0+ (0.0015,0) [0|131.07] "V"  PT
 SG_ cmbSumOfCells_SC14 m20 : 23|16@0+ (0.0015,0) [0|131.07] "V"  PT
 SG_ maxCMBDieTemp_SC14 m1 : 31|8@0+ (1,-40) [-40|200] "C"  PT
 SG_ minCMBDieTemp_SC14 m1 : 23|8@0+ (1,-40) [-40|200] "C"  PT
 SG_ appTaskSpiRxTx_SC14 m16 : 15|8@0+ (0.02,0) [0|5.1] "ms"  PT
 SG_ variantCodingCounts_SC14 m4 : 39|8@0+ (1,0) [0|0] ""  PT
 SG_ cmbMaxUpdateTime_SC14 m17 : 23|8@0+ (2,0) [0|500] "ms"  PT
 SG_ pumpSetSpeed_SC14 m18 : 55|8@0+ (1,0) [0|255] "PCT"  PT
 SG_ hvilResistance_SC14 m17 : 31|8@0+ (2,0) [0|0] "Ohm"  PT
 SG_ cmbAvgUpdateTime_SC14 m18 : 63|8@0+ (2,0) [0|500] "ms"  PT
 SG_ pumpTemperature_SC14 m18 : 39|8@0+ (1,-50) [0|0] "C"  PT
 SG_ pumpSpeed_SC14 m18 : 15|8@0+ (1,0) [0|255] "PCT"  PT
 SG_ pumpVoltage_SC14 m18 : 23|8@0+ (0.1,0) [0|0] "V"  PT
 SG_ pumpCurrent_SC14 m18 : 31|8@0+ (0.1,0) [0|0] "A"  PT
 SG_ posLink3_SC14 m17 : 39|16@0+ (0.04,-1250) [-1250|1371.4] "V"  PT
 SG_ negLink3_SC14 m17 : 55|16@0+ (0.04,-1250) [-1250|1371.4] "V"  PT
 SG_ posLink2_SC14 m16 : 39|16@0+ (0.04,-1250) [-1250|1371.4] "V"  PT
 SG_ negLink2_SC14 m16 : 55|16@0+ (0.04,-1250) [-1250|1371.4] "V"  PT
 SG_ cmbNrOfSamples_SC14 m16 : 23|8@0+ (1,0) [0|0] ""  PT
 SG_ cmbTaskTime_SC14 m16 : 31|8@0+ (1,0) [0|0] "ms"  PT
 SG_ appTask500HzMax_SC14 m15 : 15|8@0+ (0.02,0) [0|5.1] "ms"  PT
 SG_ moduleCount_SC14 m6 : 15|8@0+ (1,0) [0|0] ""  PT
 SG_ analogHallSense_SC14 m15 : 23|16@0+ (0.0001,0) [0|6.5535] "V"  PT
 SG_ cmbMaxDiagStepPeriodicity_SC14 m15 : 55|8@0+ (4,0) [0|1019] "ms"  PT
 SG_ minBrickVoltageLimit_SC14 m15 : 39|16@0+ (0.0001,0) [0|6.5535] "V"  PT
 SG_ appTask100Hz_SC14 m14 : 63|8@0+ (0.02,0) [0|5.1] "ms"  PT
 SG_ appTask10Hz_SC14 m14 : 55|8@0+ (0.02,0) [0|5.1] "ms"  PT
 SG_ appTaskAnalog_SC14 m14 : 47|8@0+ (0.02,0) [0|5.1] "ms"  PT
 SG_ appTaskADC_SC14 m14 : 39|8@0+ (0.02,0) [0|5.1] "ms"  PT
 SG_ appTask500HzAvg_SC14 m14 : 31|8@0+ (0.02,0) [0|5.1] "ms"  PT
 SG_ appTaskSBC_SC14 m14 : 23|8@0+ (0.02,0) [0|5.1] "ms"  PT
 SG_ appTaskCMBDriver_SC14 m14 : 15|8@0+ (0.02,0) [0|5.1] "ms"  PT
 SG_ safetyInitTime_SC14 m12 : 15|8@0+ (2,0) [0|500] "ms"  PT
 SG_ debugSlowMpex_SC14 M : 7|8@0+ (1,0) [0|0] ""  PT
 SG_ sbcWUAuto_SC14 m11 : 9|1@0+ (1,0) [0|0] ""  PT
 SG_ sbcWUUnknown_SC14 m11 : 8|1@0+ (1,0) [0|0] ""  PT
 SG_ sbcWUDebug_SC14 m11 : 10|1@0+ (1,0) [0|0] ""  PT
 SG_ sbcWUPOR_SC14 m11 : 11|1@0+ (1,0) [0|0] ""  PT
 SG_ sbcWUPressure_SC14 m11 : 12|1@0+ (1,0) [0|0] ""  PT
 SG_ sbcWUClock_SC14 m11 : 13|1@0+ (1,0) [0|0] ""  PT
 SG_ sbcWUCAN_SC14 m11 : 14|1@0+ (1,0) [0|0] ""  PT
 SG_ sbcWUKey_SC14 m11 : 15|1@0+ (1,0) [0|0] ""  PT
 SG_ mux960N3VRef_SC14 m13 : 39|16@0+ (-0.000805664,0) [0|0] "V"  PT
 SG_ mux960P2P5VRef_SC14 m13 : 55|16@0+ (0.000805664,0) [0|0] "V"  PT
 SG_ mux440Gnd_SC14 m10 : 15|8@0+ (0.000805664,0) [0|0] "V"  PT
 SG_ analogHallGain_SC14 m13 : 23|16@0+ (1E-005,0.8) [0.8|1.455] "k"  PT
 SG_ analogHallOffset_SC14 m13 : 15|8@0+ (0.0001,-0.005) [-0.005|0.0205] "V"  PT
 SG_ negPackPrime_SC14 m12 : 55|16@0+ (0.04,-1250) [-1250|1250] "V"  PT
 SG_ posPackPrime_SC14 m12 : 39|16@0+ (0.04,-1250) [-1250|1250] "V"  PT
 SG_ packVoltage_SC14 m12 : 23|16@0+ (0.04,-1250) [-1250|1250] "V"  PT
 SG_ sleepTime_SC14 m11 : 23|16@0+ (1,0) [0|0] "s"  PT
 SG_ analogNegHVOffset_SC14 m10 : 63|8@0+ (1,-120) [-120|120] "Bits"  PT
 SG_ analogPosHVOffset_SC14 m10 : 55|8@0+ (1,-120) [-120|120] "Bits"  PT
 SG_ analogNegHVGain_SC14 m10 : 39|16@0+ (1E-005,0.8) [0|0] "k"  PT
 SG_ analogPosHVGain_SC14 m10 : 23|16@0+ (1E-005,0.8) [0.8|1.45535] "k"  PT
 SG_ mux910Gnd_SC14 m8 : 15|8@0+ (0.000805664,0) [0|0] "V"  PT
 SG_ mux960Gnd_SC14 m9 : 15|8@0+ (0.000805664,0) [0|0] "V"  PT
 SG_ analogAddr5_SC14 m9 : 55|16@0+ (0.000805861,0) [0|0] "V"  PT
 SG_ analogAddr4_SC14 m9 : 39|16@0+ (0.000805861,0) [0|0] "V"  PT
 SG_ analogAddr3_SC14 m9 : 23|16@0+ (0.000805861,0) [0|0] "V"  PT
 SG_ analogAddr2_SC14 m8 : 55|16@0+ (0.000805861,0) [0|0] "V"  PT
 SG_ analogAddr1_SC14 m8 : 39|16@0+ (0.000805861,0) [0|0] "V"  PT
 SG_ analogAddr0_SC14 m8 : 23|16@0+ (0.000805861,0) [0|0] "V"  PT
 SG_ sbcVREF2P5_SC14 m7 : 15|8@0+ (0.003222656,2.25) [2.25|3.0715] "V"  PT
 SG_ mux910N3VRef_SC14 m7 : 39|16@0+ (-0.000805664,0) [0|0] "V"  PT
 SG_ mux910P2P5VRef_SC14 m7 : 55|16@0+ (0.000805664,0) [0|0] "V"  PT
 SG_ analogHvilCurrentPWM_SC14 m3 : 31|8@0+ (1,0) [0|255] "mA"  PT
 SG_ analogSBCSupply_SC14 m4 : 47|8@0+ (0.1,0) [0|25] "V"  PT
 SG_ analogHvilCurrent_SC14 m3 : 23|8@0+ (1,0) [0|255] "mA"  PT
 SG_ analogPressureSense_SC14 m4 : 23|8@0+ (0.025,0) [0|6.375] "V"  PT
 SG_ analog5VSensorSupply_SC14 m4 : 15|8@0+ (0.025,0) [0|6.375] "V"  PT
 SG_ analogPrechgRel2CoilMinus_SC14 m2 : 23|8@0+ (0.2,0) [0|51] "V"  PT
 SG_ analogPrechgRel1CoilMinus_SC14 m3 : 55|8@0+ (0.2,0) [0|51] "V"  PT
 SG_ analogNegCntr3CoilMinus_SC14 m2 : 31|8@0+ (0.2,0) [0|51] "V"  PT
 SG_ analogNegCntr2CoilMinus_SC14 m2 : 39|8@0+ (0.2,0) [0|51] "V"  PT
 SG_ analogNegCntr1CoilMinus_SC14 m2 : 47|8@0+ (0.2,0) [0|51] "V"  PT
 SG_ analogPosCntr3CoilMinus_SC14 m2 : 55|8@0+ (0.2,0) [0|51] "V"  PT
 SG_ analogPosCntr2CoilMinus_SC14 m2 : 63|8@0+ (0.2,0) [0|51] "V"  PT
 SG_ analogPosCntr1CoilMinus_SC14 m3 : 15|8@0+ (0.2,0) [0|51] "V"  PT
 SG_ minModuleTemperature_SC14 m1 : 15|8@0+ (1,-40) [-40|200] "C"  PT
 SG_ maxModuleTemperature_SC14 m2 : 15|8@0+ (1,-40) [-40|200] "C"  PT
 SG_ analogHvilReturn_SC14 m3 : 39|8@0+ (0.1,0) [0|25] "V"  PT
 SG_ analog5VDSupply_SC14 m3 : 47|8@0+ (0.025,0) [0|6.375] "V"  PT
 SG_ analogHvilOut_SC14 m3 : 63|8@0+ (0.1,0) [0|25] "V"  PT
 SG_ analogCurrentSensor12V_SC14 m4 : 31|8@0+ (0.075,0) [0|19] "V"  PT
 SG_ cmbErrorCounter_SC14 m6 : 47|8@0+ (1,0) [0|255] ""  PT
 SG_ PECErrorCounter_SC14 m6 : 39|8@0+ (1,0) [0|255] ""  PT
 SG_ maxVREF2_SC14 m7 : 23|16@0+ (0.0001,0) [0|6.5] "V"  PT
 SG_ minVREF2_SC14 m6 : 55|16@0+ (0.0001,0) [0|6.5] "V"  PT
 SG_ currentPlausiCounter_SC14 m5 : 15|8@0+ (1,0) [0|0] ""  PT
 SG_ hallCurrentOffset_SC14 m5 : 39|16@0+ (0.001,-30) [-30|30] "A"  PT
 SG_ sumOfCurrentsFiltered_SC14 m5 : 23|16@0+ (0.1,-3200) [-3200|3353.5] "A"  PT
 SG_ hallCurrentAveraged_SC14 m5 : 55|16@0+ (0.1,-3200) [-3200|3200] "A"  PT
 SG_ analogHallSupply_SC14 m6 : 23|16@0+ (0.0005,0) [0|32.7675] "V"  PT
 SG_ SWVersion_SC14 m11 : 39|32@0+ (1,0) [0|4294967295] ""  PT
 SG_ contactorControlPos1_SC14 m19 : 23|4@0+ (1,0) [0|7] ""  PT
 SG_ contactorControlNeg1_SC14 m19 : 19|4@0+ (1,0) [0|7] ""  PT
 SG_ contactorControlPre1_SC14 m19 : 11|4@0+ (1,0) [0|7] ""  PT
 SG_ contactorControlPos2_SC14 m19 : 31|4@0+ (1,0) [0|7] ""  PT
 SG_ contactorControlNeg2_SC14 m19 : 27|4@0+ (1,0) [0|7] ""  PT
 SG_ contactorControlPre2_SC14 m19 : 15|4@0+ (1,0) [0|7] ""  PT
 SG_ contactorControlPos3_SC14 m19 : 39|4@0+ (1,0) [0|7] ""  PT
 SG_ contactorControlNeg3_SC14 m19 : 35|4@0+ (1,0) [0|7] ""  PT

BO_ 1677 SC14_DebugFastMpex: 8 SC14
 SG_ selfTestFaultCntrCtrl_SC14 m11 : 23|8@0+ (1,0) [0|0] ""  PT
 SG_ cmbASICFault_SC14 m11 : 15|8@0+ (1,0) [0|0] ""  PT
 SG_ DIGIO_PYRO_LSD_EN_SC14 m2 : 12|1@0+ (1,0) [0|0] ""  PT
 SG_ mainUcExtIsoResistance_SC14 m10 : 55|16@0+ (1,0) [0|0] "KOhm"  PT
 SG_ BMS_C38_AR2MsgFault_SC14 m10 : 47|2@0+ (1,0) [0|0] ""  PT
 SG_ stateCoolant_SC14 m10 : 45|1@0+ (1,0) [0|0] ""  PT
 SG_ stateThermalEvent_SC14 m10 : 44|1@0+ (1,0) [0|0] ""  PT
 SG_ stateCANTx_SC14 m10 : 43|1@0+ (1,0) [0|0] ""  PT
 SG_ CANTxFaultTriggerFailed_SC14 m10 : 42|1@0+ (1,0) [0|0] ""  PT
 SG_ CANTxBMS1ST3MsgFault_SC14 m10 : 10|1@0+ (1,0) [0|0] ""  PT
 SG_ CANTxBMSDispReqMsgFault_SC14 m10 : 9|1@0+ (1,0) [0|0] ""  PT
 SG_ CANTxHVBatMsgFault_SC14 m10 : 8|1@0+ (1,0) [0|0] ""  PT
 SG_ mainUcCntrCtrlReq_SC14 m10 : 41|2@0+ (1,0) [0|0] ""  PT
 SG_ mainUcCntrWeldState_SC14 m10 : 39|4@0+ (1,0) [0|0] ""  PT
 SG_ safetyUcCntrState_SC14 m10 : 33|2@0+ (1,0) [0|0] ""  PT
 SG_ mainUcCntrState_SC14 m10 : 35|2@0+ (1,0) [0|0] ""  PT
 SG_ safetyCANMsg4Fault_SC14 m10 : 31|4@0+ (1,0) [0|0] ""  PT
 SG_ safetyCANMsg3Fault_SC14 m10 : 27|4@0+ (1,0) [0|0] ""  PT
 SG_ safetyCANMsg2Fault_SC14 m10 : 23|4@0+ (1,0) [0|0] ""  PT
 SG_ safetyCANMsg1Fault_SC14 m10 : 19|4@0+ (1,0) [0|0] ""  PT
 SG_ cmbBalancingDesired_SC14 m10 : 15|1@0+ (1,0) [0|0] ""  PT
 SG_ DIGIO_GPIO1_ON_SC14 m2 : 10|1@0+ (1,0) [0|0] ""  PT
 SG_ DIGIO_ZDW_LSD_EN_SC14 m2 : 11|1@0+ (1,0) [0|0] ""  PT
 SG_ currentShortCircuit_SC14 m2 : 9|1@0+ (1,0) [0|0] ""  PT
 SG_ contactorCntrSelfTest_SC14 m10 : 14|4@0+ (1,0) [0|15] ""  PT
 SG_ maxBrickVoltage_SC14 m11 : 39|16@0+ (0.0001,0) [0|6.5] "V"  PT
 SG_ minBrickVoltage_SC14 m11 : 55|16@0+ (0.0001,0) [0|6.5] "V"  PT
 SG_ cmbLastUpdateTime_SC14 m0 : 55|8@0+ (2,0) [0|500] "ms"  PT
 SG_ weldCheckState_SC14 m2 : 15|3@0+ (1,0) [0|0] ""  PT
 SG_ debugFastMpex_SC14 M : 7|8@0+ (1,0) [0|0] ""  PT
 SG_ SPIRxTxTimeAllPckts_SC14 m0 : 63|8@0+ (2,0) [0|500] "ms"  PT
 SG_ sleepRqASW_SC14 m2 : 8|1@0+ (1,0) [0|0] ""  PT
 SG_ prechgCtr1OnReqASW_SC14 m1 : 27|1@0+ (1,0) [0|0] ""  PT
 SG_ negCtr1OnReqASW_SC14 m1 : 25|1@0+ (1,0) [0|0] ""  PT
 SG_ posCtr1OnReqASW_SC14 m1 : 26|1@0+ (1,0) [0|0] ""  PT
 SG_ key_SC14 m1 : 24|1@0+ (1,0) [0|0] ""  PT
 SG_ stateContactorControl_SC14 m0 : 41|1@0+ (1,0) [0|0] ""  PT
 SG_ DIGIO_MULTIPLEX_m101_S3_SC14 m0 : 40|1@0+ (1,0) [0|0] ""  PT
 SG_ analogCntrPwrPlus_SC14 m1 : 15|8@0+ (0.2,0) [0|50] "V"  PT
 SG_ weldedState_SC14 m11 : 25|2@0+ (1,0) [0|3] ""  PT
 SG_ stateVoltage_SC14 m0 : 43|1@0+ (1,0) [0|0] ""  PT
 SG_ stateTemperature_SC14 m0 : 44|1@0+ (1,0) [0|0] ""  PT
 SG_ stateSelfTest_SC14 m0 : 45|1@0+ (1,0) [0|0] ""  PT
 SG_ stateHVIL_SC14 m0 : 46|1@0+ (1,0) [0|0] ""  PT
 SG_ stateCurrent_SC14 m0 : 47|1@0+ (1,0) [0|0] ""  PT
 SG_ stateCrash2_SC14 m0 : 36|1@0+ (1,0) [0|0] ""  PT
 SG_ stateCrash1_SC14 m0 : 37|1@0+ (1,0) [0|0] ""  PT
 SG_ stateContactors_SC14 m0 : 38|1@0+ (1,0) [0|0] ""  PT
 SG_ stateCANRx_SC14 m0 : 39|1@0+ (1,0) [0|0] ""  PT
 SG_ itemState_SC14 m0 : 35|4@0+ (1,0) [0|0] ""  PT
 SG_ DIGIO_SAFETY_GPIO0_SC14 m0 : 8|1@0+ (1,0) [0|0] ""  PT
 SG_ DIGIO_SC_LED501_CONTROL_SC14 m0 : 9|1@0+ (1,0) [0|0] ""  PT
 SG_ DIGIO_LNK_ISO_TST_SW_SC14 m0 : 10|1@0+ (1,0) [0|0] ""  PT
 SG_ DIGIO_SC_LED500_CONTROL_SC14 m0 : 11|1@0+ (1,0) [0|0] ""  PT
 SG_ DIGIO_POS_CNTR1_ON_SC14 m0 : 12|1@0+ (1,0) [0|0] ""  PT
 SG_ DIGIO_NEG_CNTR3_ON_SC14 m0 : 13|1@0+ (1,0) [0|0] ""  PT
 SG_ DIGIO_PRECHG_REL2_ON_SC14 m0 : 14|1@0+ (1,0) [0|0] ""  PT
 SG_ DIGIO_NEG_ISO_TEST_SW_SC14 m0 : 15|1@0+ (1,0) [0|0] ""  PT
 SG_ DIGIO_PRECHG_REL1_ON_SC14 m0 : 16|1@0+ (1,0) [0|0] ""  PT
 SG_ DIGIO_POS_ISO_TEST_SC14 m0 : 17|1@0+ (1,0) [0|0] ""  PT
 SG_ DIGIO_HVIL_PWM_SC14 m0 : 18|1@0+ (1,0) [0|0] ""  PT
 SG_ DIGIO_CNTR_HISIDE_ON_SC_SC14 m0 : 19|1@0+ (1,0) [0|0] ""  PT
 SG_ DIGIO_CRASH_DETECT_SC14 m0 : 20|1@0+ (1,0) [0|0] ""  PT
 SG_ DIGIO_NEG_CNTR2_ON_SC14 m0 : 21|1@0+ (1,0) [0|0] ""  PT
 SG_ DIGIO_NEG_CNTR1_ON_SC14 m0 : 22|1@0+ (1,0) [0|0] ""  PT
 SG_ DIGIO_POS_CNTR3_ON_SC14 m0 : 23|1@0+ (1,0) [0|0] ""  PT
 SG_ DIGIO_POS_CNTR2_ON_SC14 m0 : 24|1@0+ (1,0) [0|0] ""  PT
 SG_ DIGIO_MULTIPLEX_m101_S2_SC14 m0 : 25|1@0+ (1,0) [0|0] ""  PT
 SG_ DIGIO_MULTIPLEX_8TO1_S1_SC14 m0 : 26|1@0+ (1,0) [0|0] ""  PT
 SG_ DIGIO_CNTR_CLOSE_OK_CHCKD_SC14 m0 : 27|1@0+ (1,0) [0|0] ""  PT
 SG_ DIGIO_MULTIPLEX_8TO1_S2_SC14 m0 : 28|1@0+ (1,0) [0|0] ""  PT
 SG_ DIGIO_CNTR_CLOSE_OK_SC14 m0 : 29|1@0+ (1,0) [0|0] ""  PT
 SG_ DIGIO_MULTIPLEX_m101_S1_SC14 m0 : 30|1@0+ (1,0) [0|0] ""  PT
 SG_ DIGIO_CNTR_HISIDE_ON_CHCKD_SC14 m0 : 31|1@0+ (1,0) [0|0] ""  PT
 SG_ posPack_SC14 m2 : 23|16@0+ (0.04,-1250) [-1250|1250] "V"  PT
 SG_ posLink_SC14 m2 : 55|16@0+ (0.04,-1250) [-1250|1371.4] "V"  PT
 SG_ negPack_SC14 m2 : 39|16@0+ (0.04,-1250) [-1250|1250] "V"  PT
 SG_ negLink_SC14 m1 : 39|16@0+ (0.04,-1250) [-1250|1371.4] "V"  PT
 SG_ hallCurrent_SC14 m1 : 23|12@0+ (0.6,-1200) [-1200|1257] "A"  PT
 SG_ analogCntrPwrPlusISense_SC14 m1 : 63|8@0+ (0.05,0) [0|12.5] "A"  PT
 SG_ analogCntrPwrPlusSwitched_SC14 m1 : 55|8@0+ (0.2,0) [0|50] "V"  PT
 SG_ BIT_ANALOG_REF_FAIL_SC14 m3 : 8|1@0+ (1,0) [0|0] ""  PT
 SG_ BIT_ANALOG_ADCDRIVER_FAIL_SC14 m3 : 9|1@0+ (1,0) [0|0] ""  PT
 SG_ BIT_ANALOG_MUX910_HW_SC14 m3 : 10|1@0+ (1,0) [0|0] ""  PT
 SG_ BIT_ANALOG_MUX960_HW_SC14 m3 : 11|1@0+ (1,0) [0|0] ""  PT
 SG_ BIT_ANALOG_MUX301_HW_SC14 m3 : 12|1@0+ (1,0) [0|0] ""  PT
 SG_ BIT_ANALOG_MUX440_HW_SC14 m3 : 13|1@0+ (1,0) [0|0] ""  PT
 SG_ BIT_ANALOG_5VA_FAIL_SC14 m3 : 14|1@0+ (1,0) [0|0] ""  PT
 SG_ BIT_ANALOG_HV_SIGN_SC14 m3 : 15|1@0+ (1,0) [0|0] ""  PT
 SG_ BIT_CAN_ISENSE01_MIA_SC14 m3 : 24|1@0+ (1,0) [0|0] ""  PT
 SG_ BIT_CAN_ISENSE02_MIA_SC14 m3 : 25|1@0+ (1,0) [0|0] ""  PT
 SG_ BIT_CAN_ISENSE03_MIA_SC14 m3 : 26|1@0+ (1,0) [0|0] ""  PT
 SG_ BIT_CAN_ISENSE04_MIA_SC14 m3 : 27|1@0+ (1,0) [0|0] ""  PT
 SG_ BIT_CAN_ISENSE05_MIA_SC14 m3 : 28|1@0+ (1,0) [0|0] ""  PT
 SG_ BIT_CAN_PT_MIA_SC14 m3 : 29|1@0+ (1,0) [0|0] ""  PT
 SG_ BIT_CAN_PT_CRC_SC14 m3 : 30|1@0+ (1,0) [0|0] ""  PT
 SG_ BIT_CAN_PT_ALIVE_SC14 m3 : 31|1@0+ (1,0) [0|0] ""  PT
 SG_ BIT_CAN_SAFETYLIN_MIA_SC14 m3 : 32|1@0+ (1,0) [0|0] ""  PT
 SG_ BIT_CAN_SAFETYLIN_SHUTDOWN_SC14 m3 : 33|1@0+ (1,0) [0|0] ""  PT
 SG_ BIT_CMB_GPIO_SHORT_SC14 m3 : 40|1@0+ (1,0) [0|0] ""  PT
 SG_ BIT_CMB_C2S_LEAK_SC14 m3 : 41|1@0+ (1,0) [0|0] ""  PT
 SG_ BIT_CMB_SENSE_LINE_SC14 m3 : 42|1@0+ (1,0) [0|0] ""  PT
 SG_ BIT_CMB_SUMOFCELL_CHECK_SC14 m3 : 43|1@0+ (1,0) [0|0] ""  PT
 SG_ BIT_CMB_DRIVER_TIMING_SC14 m3 : 44|1@0+ (1,0) [0|0] ""  PT
 SG_ BIT_CMB_CLEAR_SC14 m3 : 45|1@0+ (1,0) [0|0] ""  PT
 SG_ BIT_CMB_SELFTEST_SC14 m3 : 46|1@0+ (1,0) [0|0] ""  PT
 SG_ BIT_CMB_GPIO_OPEN_SC14 m3 : 47|1@0+ (1,0) [0|0] ""  PT
 SG_ BIT_CMB_CELLV_RANGE_ERR_SC14 m3 : 48|1@0+ (1,0) [0|0] ""  PT
 SG_ BIT_CMB_ADOL_CHECK_SC14 m3 : 49|1@0+ (1,0) [0|0] ""  PT
 SG_ BIT_CMB_BALANCING_STUCK_SC14 m3 : 50|1@0+ (1,0) [0|0] ""  PT
 SG_ BIT_CMB_SUPPLY_SC14 m3 : 51|1@0+ (1,0) [0|0] ""  PT
 SG_ BIT_CMB_DEFECT_SC14 m3 : 52|1@0+ (1,0) [0|0] ""  PT
 SG_ BIT_CMB_PEC_ERROR_SC14 m3 : 53|1@0+ (1,0) [0|0] ""  PT
 SG_ BIT_CMB_GPIO_ERROR_SC14 m3 : 54|1@0+ (1,0) [0|0] ""  PT
 SG_ BIT_CMB_DIGTLREDNCY_LF_SC14 m3 : 55|1@0+ (1,0) [0|0] ""  PT
 SG_ BIT_CCTRL_SELFTEST_SC14 m4 : 8|1@0+ (1,0) [0|0] ""  PT
 SG_ BIT_CCTRL_DRIVER_FAULT_SC14 m4 : 9|1@0+ (1,0) [0|0] ""  PT
 SG_ BIT_CCTRL_HISIDE_STCLSD_SC14 m4 : 10|1@0+ (1,0) [0|0] ""  PT
 SG_ BIT_CCTRL_LOSIDE_STCLSD_SC14 m4 : 11|1@0+ (1,0) [0|0] ""  PT
 SG_ BIT_CCTRL_HISIDE_STUCK_OPEN_SC14 m4 : 12|1@0+ (1,0) [0|0] ""  PT
 SG_ BIT_CCTRL_HVOLTAGE_COND_SC14 m4 : 13|1@0+ (1,0) [0|0] ""  PT
 SG_ BIT_CCTRL_POS1_OPENCIRC_SC14 m4 : 14|1@0+ (1,0) [0|0] ""  PT
 SG_ BIT_CCTRL_NEG1_OPENCIRC_SC14 m4 : 15|1@0+ (1,0) [0|0] ""  PT
 SG_ BIT_CCTRL_PRECHG1_OPENCIRC_SC14 m4 : 16|1@0+ (1,0) [0|0] ""  PT
 SG_ BIT_CCTRL_POS2_OPENCIRC_SC14 m4 : 17|1@0+ (1,0) [0|0] ""  PT
 SG_ BIT_CCTRL_NEG2_OPENCIRC_SC14 m4 : 18|1@0+ (1,0) [0|0] ""  PT
 SG_ BIT_CCTRL_LOSDE_STOPEN_SC14 m4 : 19|1@0+ (1,0) [0|0] ""  PT
 SG_ BIT_CCTRL_POS3_OPENCIRC_SC14 m4 : 20|1@0+ (1,0) [0|0] ""  PT
 SG_ BIT_CCTRL_PRECHG2_OPENCIRC_SC14 m4 : 21|1@0+ (1,0) [0|0] ""  PT
 SG_ BIT_CCTRL_ITEM_OFF_OPEN_SC14 m4 : 22|1@0+ (1,0) [0|0] ""  PT
 SG_ BIT_CCTRL_UNEXPECTED_OPEN_SC14 m4 : 23|1@0+ (1,0) [0|0] ""  PT
 SG_ BIT_CNTR_ISOLATION_SC14 m4 : 24|1@0+ (1,0) [0|0] ""  PT
 SG_ BIT_CNTR_ISO_AND_POT_WELD_SC14 m4 : 25|1@0+ (1,0) [0|0] ""  PT
 SG_ BIT_CNTR_POS1_WELDED_SC14 m4 : 26|1@0+ (1,0) [0|0] ""  PT
 SG_ BIT_CNTR_NEG1_WELDED_SC14 m4 : 27|1@0+ (1,0) [0|0] ""  PT
 SG_ BIT_CNTR_POS2_WELDED_SC14 m4 : 28|1@0+ (1,0) [0|0] ""  PT
 SG_ BIT_CNTR_NEG2_WELDED_SC14 m4 : 29|1@0+ (1,0) [0|0] ""  PT
 SG_ BIT_CNTR_POS3_WELDED_SC14 m4 : 30|1@0+ (1,0) [0|0] ""  PT
 SG_ BIT_CNTR_NEG3_WELDED_SC14 m4 : 31|1@0+ (1,0) [0|0] ""  PT
 SG_ BIT_CNTR_P_ANDOR_N_WELD_SC14 m4 : 32|1@0+ (1,0) [0|0] ""  PT
 SG_ BIT_CNTR_HIGH_CY_SC14 m4 : 33|1@0+ (1,0) [0|0] ""  PT
 SG_ BIT_CNTR_WELDCHECK_TIMEOUT_SC14 m4 : 34|1@0+ (1,0) [0|0] ""  PT
 SG_ BIT_CURRENT_PLAUSIBILITY_SC14 m4 : 40|1@0+ (1,0) [0|0] ""  PT
 SG_ BIT_CURRENT_OVERCHARGE_SC14 m4 : 41|1@0+ (1,0) [0|0] ""  PT
 SG_ BIT_CURRENT_OVERDISCHARGE_SC14 m4 : 42|1@0+ (1,0) [0|0] ""  PT
 SG_ BIT_CURRENT_ISENSE1_INVALID_SC14 m4 : 43|1@0+ (1,0) [0|0] ""  PT
 SG_ BIT_CURRENT_ISENSE2_INVALID_SC14 m4 : 44|1@0+ (1,0) [0|0] ""  PT
 SG_ BIT_CURRENT_ISENSE3_INVALID_SC14 m4 : 45|1@0+ (1,0) [0|0] ""  PT
 SG_ BIT_CURRENT_ISENSE4_INVALID_SC14 m4 : 46|1@0+ (1,0) [0|0] ""  PT
 SG_ BIT_CURRENT_ISENSE5_INVALID_SC14 m4 : 47|1@0+ (1,0) [0|0] ""  PT
 SG_ BIT_CURRENT_HALL_INVALID_SC14 m4 : 48|1@0+ (1,0) [0|0] ""  PT
 SG_ BIT_CURRENT_OFFSET_FAULT_SC14 m4 : 49|1@0+ (1,0) [0|0] ""  PT
 SG_ BIT_FLUXGATE1_CURRENT_FAULT_SC14 m5 : 8|1@0+ (1,0) [0|0] ""  PT
 SG_ BIT_FLUXGATE_12V_LOW_SC14 m5 : 18|1@0+ (1,0) [0|0] ""  PT
 SG_ BIT_HALL_INVALID_SC14 m5 : 24|1@0+ (1,0) [0|0] ""  PT
 SG_ BIT_HALL_PWR_FAIL_LO_SC14 m5 : 25|1@0+ (1,0) [0|0] ""  PT
 SG_ BIT_HALL_SENSELO_SC14 m5 : 26|1@0+ (1,0) [0|0] ""  PT
 SG_ BIT_HALL_SENSEHI_SC14 m5 : 27|1@0+ (1,0) [0|0] ""  PT
 SG_ BIT_HVIL_HW_FAULT_SC14 m5 : 40|1@0+ (1,0) [0|0] ""  PT
 SG_ BIT_HVIL_OPEN_CIRCUIT_SC14 m5 : 41|1@0+ (1,0) [0|0] ""  PT
 SG_ BIT_HVIL_SHORT_SUPPLY_SC14 m5 : 42|1@0+ (1,0) [0|0] ""  PT
 SG_ BIT_HVIL_SHORT_CHASSIS_SC14 m5 : 43|1@0+ (1,0) [0|0] ""  PT
 SG_ BIT_HVIL_RESISTANCE_HIGH_SC14 m5 : 44|1@0+ (1,0) [0|0] ""  PT
 SG_ BIT_HVIL_SHORT_CIRCUIT_SC14 m5 : 45|1@0+ (1,0) [0|0] ""  PT
 SG_ BIT_ISASHUNT1_CURRENT_FAULT_SC14 m7 : 24|1@0+ (1,0) [0|0] ""  PT
 SG_ BIT_ISASHUNT2_CURRENT_FAULT_SC14 m7 : 25|1@0+ (1,0) [0|0] ""  PT
 SG_ BIT_ISASHUNT3_CURRENT_FAULT_SC14 m7 : 26|1@0+ (1,0) [0|0] ""  PT
 SG_ BIT_ISASHUNT4_CURRENT_FAULT_SC14 m7 : 27|1@0+ (1,0) [0|0] ""  PT
 SG_ BIT_ISASHUNT5_CURRENT_FAULT_SC14 m7 : 28|1@0+ (1,0) [0|0] ""  PT
 SG_ BIT_ISASHUNT1_CHARGE_FAULT_SC14 m7 : 29|1@0+ (1,0) [0|0] ""  PT
 SG_ BIT_ISASHUNT2_CHARGE_FAULT_SC14 m7 : 30|1@0+ (1,0) [0|0] ""  PT
 SG_ BIT_ISASHUNT3_CHARGE_FAULT_SC14 m7 : 31|1@0+ (1,0) [0|0] ""  PT
 SG_ BIT_ISASHUNT4_CHARGE_FAULT_SC14 m7 : 32|1@0+ (1,0) [0|0] ""  PT
 SG_ BIT_ISASHUNT5_CHARGE_FAULT_SC14 m7 : 33|1@0+ (1,0) [0|0] ""  PT
 SG_ BIT_ISASHUNT_SUPPLY_LOW_SC14 m7 : 34|1@0+ (1,0) [0|0] ""  PT
 SG_ BIT_LINK_POS_HW_FAIL_SC14 m7 : 40|1@0+ (1,0) [0|0] ""  PT
 SG_ BIT_LINK_NEG_HW_FAIL_SC14 m7 : 41|1@0+ (1,0) [0|0] ""  PT
 SG_ BIT_PUMP_LIN_FAILURE_SC14 m8 : 8|1@0+ (1,0) [0|0] ""  PT
 SG_ BIT_PUMP_OVERTEMPERATURE_SC14 m8 : 9|1@0+ (1,0) [0|0] ""  PT
 SG_ BIT_PUMP_SPEED_HIGH_SC14 m8 : 10|1@0+ (1,0) [0|0] ""  PT
 SG_ BIT_PUMP_SPEED_LOW_SC14 m8 : 11|1@0+ (1,0) [0|0] ""  PT
 SG_ BIT_PUMP_DRY_RUN_SC14 m8 : 12|1@0+ (1,0) [0|0] ""  PT
 SG_ BIT_SBC_VCORE_OOR_SC14 m6 : 8|1@0+ (1,0) [0|0] ""  PT
 SG_ BIT_SBC_SELFTEST_SC14 m6 : 9|1@0+ (1,0) [0|0] ""  PT
 SG_ BIT_SBC_INIT_SC14 m6 : 10|1@0+ (1,0) [0|0] ""  PT
 SG_ BIT_SBC_WATCHDOG_SC14 m6 : 11|1@0+ (1,0) [0|0] ""  PT
 SG_ BIT_SBC_FECBITFLIP_SC14 m6 : 12|1@0+ (1,0) [0|0] ""  PT
 SG_ BIT_SBC_VREUV_SC14 m6 : 13|1@0+ (1,0) [0|0] ""  PT
 SG_ BIT_SBC_FAILSAFE_SC14 m6 : 14|1@0+ (1,0) [0|0] ""  PT
 SG_ BIT_SBC_VAUX_OOR_SC14 m6 : 15|1@0+ (1,0) [0|0] ""  PT
 SG_ BIT_SBC_VCCA_OOR_SC14 m6 : 16|1@0+ (1,0) [0|0] ""  PT
 SG_ BIT_SBC_FCRBM_OOR_SC14 m6 : 17|1@0+ (1,0) [0|0] ""  PT
 SG_ BIT_SBC_FLT_ERR_CNTR_SC14 m6 : 18|1@0+ (1,0) [0|0] ""  PT
 SG_ BIT_SBC_FS0B_FAIL_SC14 m6 : 19|1@0+ (1,0) [0|0] ""  PT
 SG_ BIT_SBC_SPI_ERRORS_SC14 m6 : 20|1@0+ (1,0) [0|0] ""  PT
 SG_ BIT_SBC_SPI_TX_FAIL_SC14 m6 : 21|1@0+ (1,0) [0|0] ""  PT
 SG_ BIT_SBC_NERROR_ACTIVE_SC14 m6 : 22|1@0+ (1,0) [0|0] ""  PT
 SG_ BIT_SELFTEST_RAM_SC14 m6 : 24|1@0+ (1,0) [0|0] ""  PT
 SG_ BIT_SELFTEST_FLASH_SC14 m6 : 25|1@0+ (1,0) [0|0] ""  PT
 SG_ BIT_SELFTEST_CLOCK_SC14 m6 : 26|1@0+ (1,0) [0|0] ""  PT
 SG_ BIT_SELFTEST_WATCHDOG_SC14 m6 : 27|1@0+ (1,0) [0|0] ""  PT
 SG_ BIT_SELFTEST_STACK_SC14 m6 : 28|1@0+ (1,0) [0|0] ""  PT
 SG_ BIT_SELFTEST_L2L3_SC14 m6 : 29|1@0+ (1,0) [0|0] ""  PT
 SG_ BIT_SELFTEST_EFUSE_SC14 m6 : 30|1@0+ (1,0) [0|0] ""  PT
 SG_ BIT_SELFTEST_EXCEPTION_SC14 m6 : 31|1@0+ (1,0) [0|0] ""  PT
 SG_ BIT_SELFTEST_5VD_FAIL_SC14 m6 : 32|1@0+ (1,0) [0|0] ""  PT
 SG_ BIT_SELFTEST_VIM_SC14 m6 : 33|1@0+ (1,0) [0|0] ""  PT
 SG_ BIT_SELFTEST_TASKTIME_SC14 m6 : 34|1@0+ (1,0) [0|0] ""  PT
 SG_ BIT_SELFTEST_RTI_SC14 m6 : 35|1@0+ (1,0) [0|0] ""  PT
 SG_ BIT_SELFTEST_ESM_SC14 m6 : 36|1@0+ (1,0) [0|0] ""  PT
 SG_ BIT_SELFTEST_IOM_SC14 m6 : 37|1@0+ (1,0) [0|0] ""  PT
 SG_ BIT_SELFTEST_SBC_SC14 m6 : 38|1@0+ (1,0) [0|0] ""  PT
 SG_ BIT_SELFTEST_STARTUP_SC14 m6 : 39|1@0+ (1,0) [0|0] ""  PT
 SG_ BIT_TEMP_MODULEOVERTEMP_SC14 m6 : 40|1@0+ (1,0) [0|0] ""  PT
 SG_ BIT_TEMP_MODULETEMP_INVALID_SC14 m6 : 41|1@0+ (1,0) [0|0] ""  PT
 SG_ BIT_TEMP_NTC_OPENWIRE_SC14 m6 : 42|1@0+ (1,0) [0|0] ""  PT
 SG_ BIT_TEMP_NTC_SHORT_SC14 m6 : 43|1@0+ (1,0) [0|0] ""  PT
 SG_ BIT_TEMP_PLAUSIBILITY_SC14 m6 : 44|1@0+ (1,0) [0|0] ""  PT
 SG_ BIT_VOLTAGE_BRICKV_INVALID_SC14 m7 : 8|1@0+ (1,0) [0|0] ""  PT
 SG_ BIT_VOLTAGE_BRICKUV_SC14 m7 : 9|1@0+ (1,0) [0|0] ""  PT
 SG_ BIT_VOLTAGE_BRICKOV_SC14 m7 : 10|1@0+ (1,0) [0|0] ""  PT
 SG_ BIT_VOLTAGE_BRICKDEEPDSCHG_SC14 m7 : 11|1@0+ (1,0) [0|0] ""  PT
 SG_ BIT_VOLTAGE_PACKV_INVALID_SC14 m7 : 12|1@0+ (1,0) [0|0] ""  PT
 SG_ BIT_VOLTAGE_PLAUSIBILITY_SC14 m7 : 13|1@0+ (1,0) [0|0] ""  PT
 SG_ BIT_VOLTAGE_CMB_PLAUSI_SC14 m7 : 14|1@0+ (1,0) [0|0] ""  PT
 SG_ BIT_VOLTAGE_SENSE_OPENWIRE_SC14 m7 : 15|1@0+ (1,0) [0|0] ""  PT
 SG_ BIT_VOLTAGE_BRICKV_FROZEN_SC14 m7 : 16|1@0+ (1,0) [0|0] ""  PT
 SG_ BIT_PUMP_BLOCK_SC14 m8 : 13|1@0+ (1,0) [0|0] ""  PT
 SG_ BIT_PUMP_SUPPLY_SC14 m8 : 14|1@0+ (1,0) [0|0] ""  PT
 SG_ BIT_PUMP_OVERCURRENT_SC14 m8 : 15|1@0+ (1,0) [0|0] ""  PT
 SG_ BIT_PUMP_ELECTRIC_SC14 m8 : 16|1@0+ (1,0) [0|0] ""  PT
 SG_ BIT_PUMP_RS_SC14 m8 : 17|1@0+ (1,0) [0|0] ""  PT
 SG_ BIT_HALL_PWR_FAIL_HI_SC14 m5 : 28|1@0+ (1,0) [0|0] ""  PT
 SG_ BIT_VOLTAGE_OUT_OF_RANGE_SC14 m7 : 17|1@0+ (1,0) [0|0] ""  PT
 SG_ BIT_ISO_OFF_TIME_SHORT_SC14 m8 : 24|1@0+ (1,0) [0|0] ""  PT
 SG_ BIT_ISO_ON_TIME_SHORT_SC14 m8 : 25|1@0+ (1,0) [0|0] ""  PT
 SG_ BIT_ISO_INTERNAL_INACTIVE_SC14 m8 : 26|1@0+ (1,0) [0|0] ""  PT
 SG_ BIT_ISO_SW_STATE_INVALID_SC14 m8 : 27|1@0+ (1,0) [0|0] ""  PT
 SG_ BIT_ISO_PACKV_SNA_SWOFF_SC14 m8 : 28|1@0+ (1,0) [0|0] ""  PT
 SG_ BIT_ISO_PACKV_SNA_SWON_SC14 m8 : 29|1@0+ (1,0) [0|0] ""  PT
 SG_ BIT_ISO_EXTERNAL_INACTIVE_SC14 m8 : 30|1@0+ (1,0) [0|0] ""  PT
 SG_ BIT_CANTX_CNTR_STAT_FAULT_SC14 m8 : 40|1@0+ (1,0) [0|0] ""  PT
 SG_ BIT_CANTX_CNTR_WELD_FAULT_SC14 m8 : 41|1@0+ (1,0) [0|0] ""  PT
 SG_ BIT_CANTX_THERMAL_FAULT_SC14 m8 : 42|1@0+ (1,0) [0|0] ""  PT
 SG_ BIT_CANTX_ISOLATION_FAULT_SC14 m8 : 43|1@0+ (1,0) [0|0] ""  PT
 SG_ BIT_CANTX_HVIL_FAULT_SC14 m8 : 44|1@0+ (1,0) [0|0] ""  PT
 SG_ BIT_VOLTAGE_STATELATCHED_SC14 m7 : 18|1@0+ (1,0) [0|0] ""  PT
 SG_ BIT_CANTX_ISOLATION_PREFLT_SC14 m8 : 45|1@0+ (1,0) [0|0] ""  PT
 SG_ BIT_CANTX_FLTRIGGER_FAILED_SC14 m8 : 46|1@0+ (1,0) [0|0] ""  PT
 SG_ BIT_ISO_TEST_SWITCH_FAULT_SC14 m8 : 31|1@0+ (1,0) [0|0] ""  PT
 SG_ BIT_THERMAL_ADC_FAULT_SC14 m9 : 8|1@0+ (1,0) [0|0] ""  PT
 SG_ BIT_THERMAL_PRESSURE_VHI_SC14 m9 : 9|1@0+ (1,0) [0|0] ""  PT
 SG_ BIT_THERMAL_PRESSURE_VLO_SC14 m9 : 10|1@0+ (1,0) [0|0] ""  PT
 SG_ BIT_THERMAL_PRIMARY_EVT_SC14 m9 : 11|1@0+ (1,0) [0|0] ""  PT
 SG_ BIT_THERMAL_SECONRY_EVT_SC14 m9 : 12|1@0+ (1,0) [0|0] ""  PT
 SG_ BIT_THERMAL_PRESSURE_INV_SC14 m9 : 13|1@0+ (1,0) [0|0] ""  PT
 SG_ BIT_THERMAL_EVTLATCHED_SC14 m9 : 14|1@0+ (1,0) [0|0] ""  PT
 SG_ BIT_COOLANT_CANMIA_SC14 m9 : 24|1@0+ (1,0) [0|0] ""  PT
 SG_ BIT_COOLANT_SENSRFAIL_SC14 m9 : 25|1@0+ (1,0) [0|0] ""  PT
 SG_ BIT_COOLANT_WATERDETCD_SC14 m9 : 26|1@0+ (1,0) [0|0] ""  PT
 SG_ BIT_COOLANT_LATCHED_SC14 m9 : 27|1@0+ (1,0) [0|0] ""  PT
 SG_ BIT_ANALOG_PULLUP_DSBLD_SC14 m3 : 17|1@0+ (1,0) [0|0] ""  PT
 SG_ BIT_ANALOG_PULLUP_DSBLRQ_SC14 m3 : 16|1@0+ (1,0) [0|0] ""  PT
 SG_ BIT_SBC_REG_ERROR_SC14 m6 : 23|1@0+ (1,0) [0|0] ""  PT
 SG_ BIT_CURRENT_LATCHED_SC14 m4 : 50|1@0+ (1,0) [0|0] ""  PT
 SG_ BIT_TEMP_LATCHED_SC14 m6 : 45|1@0+ (1,0) [0|0] ""  PT
 SG_ BIT_ISO_PLAUSI_SWOFF_SC14 m8 : 32|1@0+ (1,0) [0|0] ""  PT
 SG_ BIT_ISO_PLAUSI_SWON_SC14 m8 : 33|1@0+ (1,0) [0|0] ""  PT
 SG_ BIT_ISO_RELAXED_INACTIVE_SC14 m8 : 34|1@0+ (1,0) [0|0] ""  PT
 SG_ BIT_THERMAL_PRESSURE_MIA_SC14 m9 : 15|1@0+ (1,0) [0|0] ""  PT
 SG_ BIT_LINK_PACK_MISMATCH_SC14 m7 : 42|1@0+ (1,0) [0|0] ""  PT
 SG_ BIT_CAN_PT_EMERGENCY_SC14 m3 : 34|1@0+ (1,0) [0|0] ""  PT
 SG_ BIT_THERMAL_PRES_SUPPLY_OOR_SC14 m9 : 16|1@0+ (1,0) [0|0] ""  PT
 SG_ BIT_CAN_SM_DISABLE_SC14 m3 : 35|1@0+ (1,0) [0|0] ""  PT
 SG_ BIT_THERMAL_PRESSURE_FLT_SC14 m9 : 17|1@0+ (1,0) [0|0] ""  PT
 SG_ BIT_CURRENT_SENSOR_FAULT_SC14 m9 : 40|1@0+ (1,0) [0|0] ""  PT
 SG_ BIT_CURRENT_SENSOR_CHARGE_FAULT_SC14 m9 : 45|1@0+ (1,0) [0|0] ""  PT
 SG_ BIT_CURRENT_SENSOR_SUP_LOW_SC14 m9 : 50|1@0+ (1,0) [0|0] ""  PT
 SG_ BIT_THERMAL_H2SENSE_FAULT_SC14 m9 : 18|1@0+ (1,0) [0|0] ""  PT
 SG_ BIT_VOLTAGE_BRICKCOUNT_INVALID_SC14 m7 : 19|1@0+ (1,0) [0|0] ""  PT

BO_ 1933 BMS14_DebugOnboard: 7 BMS14
 SG_ cmbCoolantTemp08_BMS14 m8 : 55|8@0+ (1,-40) [-40|200] "C"  PT
 SG_ cmbCoolantTemp07_BMS14 m7 : 55|8@0+ (1,-40) [-40|200] "C"  PT
 SG_ cmbCoolantTemp06_BMS14 m6 : 55|8@0+ (1,-40) [-40|200] "C"  PT
 SG_ cmbCoolantTemp05_BMS14 m5 : 55|8@0+ (1,-40) [-40|200] "C"  PT
 SG_ cmbCoolantTemp04_BMS14 m4 : 55|8@0+ (1,-40) [-40|200] "C"  PT
 SG_ cmbCoolantTemp03_BMS14 m3 : 55|8@0+ (1,-40) [-40|200] "C"  PT
 SG_ cmbCoolantTemp02_BMS14 m2 : 55|8@0+ (1,-40) [-40|200] "C"  PT
 SG_ cmbCoolantTemp01_BMS14 m1 : 55|8@0+ (1,-40) [-40|200] "C"  PT
 SG_ cmbOnboardPressure32_BMS14 m32 : 39|16@0+ (1,0) [0|600] "kPa"  PT
 SG_ cmbOnboardPressure31_BMS14 m31 : 39|16@0+ (1,0) [0|600] "kPa"  PT
 SG_ cmbOnboardPressure30_BMS14 m30 : 39|16@0+ (1,0) [0|600] "kPa"  PT
 SG_ cmbOnboardPressure29_BMS14 m29 : 39|16@0+ (1,0) [0|600] "kPa"  PT
 SG_ cmbOnboardPressure28_BMS14 m28 : 39|16@0+ (1,0) [0|600] "kPa"  PT
 SG_ cmbOnboardPressure27_BMS14 m27 : 39|16@0+ (1,0) [0|600] "kPa"  PT
 SG_ cmbOnboardPressure26_BMS14 m26 : 39|16@0+ (1,0) [0|600] "kPa"  PT
 SG_ cmbOnboardPressure25_BMS14 m25 : 39|16@0+ (1,0) [0|600] "kPa"  PT
 SG_ cmbOnboardPressure24_BMS14 m24 : 39|16@0+ (1,0) [0|600] "kPa"  PT
 SG_ cmbOnboardPressure23_BMS14 m23 : 39|16@0+ (1,0) [0|600] "kPa"  PT
 SG_ cmbOnboardPressure22_BMS14 m22 : 39|16@0+ (1,0) [0|600] "kPa"  PT
 SG_ cmbOnboardPressure21_BMS14 m21 : 39|16@0+ (1,0) [0|600] "kPa"  PT
 SG_ cmbOnboardPressure20_BMS14 m20 : 39|16@0+ (1,0) [0|600] "kPa"  PT
 SG_ cmbOnboardPressure19_BMS14 m19 : 39|16@0+ (1,0) [0|600] "kPa"  PT
 SG_ cmbOnboardPressure18_BMS14 m18 : 39|16@0+ (1,0) [0|600] "kPa"  PT
 SG_ cmbOnboardPressure17_BMS14 m17 : 39|16@0+ (1,0) [0|600] "kPa"  PT
 SG_ cmbOnboardPressure16_BMS14 m16 : 39|16@0+ (1,0) [0|600] "kPa"  PT
 SG_ cmbOnboardPressure15_BMS14 m15 : 39|16@0+ (1,0) [0|600] "kPa"  PT
 SG_ cmbOnboardPressure14_BMS14 m14 : 39|16@0+ (1,0) [0|600] "kPa"  PT
 SG_ cmbOnboardPressure13_BMS14 m13 : 39|16@0+ (1,0) [0|600] "kPa"  PT
 SG_ cmbOnboardPressure12_BMS14 m12 : 39|16@0+ (1,0) [0|600] "kPa"  PT
 SG_ cmbOnboardPressure11_BMS14 m11 : 39|16@0+ (1,0) [0|600] "kPa"  PT
 SG_ cmbOnboardPressure10_BMS14 m10 : 39|16@0+ (1,0) [0|600] "kPa"  PT
 SG_ cmbOnboardPressure09_BMS14 m9 : 39|16@0+ (1,0) [0|600] "kPa"  PT
 SG_ cmbOnboardPressure08_BMS14 m8 : 39|16@0+ (1,0) [0|600] "kPa"  PT
 SG_ cmbOnboardPressure07_BMS14 m7 : 39|16@0+ (1,0) [0|600] "kPa"  PT
 SG_ cmbOnboardPressure06_BMS14 m6 : 39|16@0+ (1,0) [0|600] "kPa"  PT
 SG_ cmbOnboardPressure05_BMS14 m5 : 39|16@0+ (1,0) [0|600] "kPa"  PT
 SG_ cmbOnboardPressure04_BMS14 m4 : 39|16@0+ (1,0) [0|600] "kPa"  PT
 SG_ cmbOnboardPressure03_BMS14 m3 : 39|16@0+ (1,0) [0|600] "kPa"  PT
 SG_ cmbOnboardPressure02_BMS14 m2 : 39|16@0+ (1,0) [0|600] "kPa"  PT
 SG_ cmbOnboardPressure01_BMS14 m1 : 39|16@0+ (1,0) [0|600] "kPa"  PT
 SG_ onboardMultiplexor_BMS14 M : 7|8@0+ (1,0) [0|0] ""  PT
 SG_ minCmbOnboardTemperature_BMS14 m0 : 31|8@0+ (1,-40) [-40|200] "C"  PT
 SG_ minCmbOnboardHumidity_BMS14 m0 : 47|8@0+ (0.5,0) [0|120] "PCT"  PT
 SG_ maxCmbOnboardTemperature_BMS14 m0 : 39|8@0+ (1,-40) [-40|200] "C"  PT
 SG_ maxCmbOnboardHumidity_BMS14 m0 : 55|8@0+ (0.5,0) [0|120] "PCT"  PT
 SG_ bmsOnboardTemperature_BMS14 m0 : 15|8@0+ (1,-40) [-40|200] "C"  PT
 SG_ bmsOnboardHumidity_BMS14 m0 : 23|8@0+ (0.5,0) [0|120] "PCT"  PT
 SG_ cmbOnboardTemperature01_BMS14 m1 : 15|8@0+ (1,-40) [-40|200] "C"  PT
 SG_ cmbOnboardHumidity01_BMS14 m1 : 23|8@0+ (0.5,0) [0|120] "PCT"  PT
 SG_ moduleHeaterCurrent01_BMS14 m1 : 31|8@0+ (0.05,0) [0|10] "A"  PT
 SG_ cmbOnboardTemperature02_BMS14 m2 : 15|8@0+ (1,-40) [-40|200] "C"  PT
 SG_ cmbOnboardHumidity02_BMS14 m2 : 23|8@0+ (0.5,0) [0|120] "PCT"  PT
 SG_ moduleHeaterCurrent02_BMS14 m2 : 31|8@0+ (0.05,0) [0|10] "A"  PT
 SG_ cmbOnboardTemperature03_BMS14 m3 : 15|8@0+ (1,-40) [-40|200] "C"  PT
 SG_ cmbOnboardHumidity03_BMS14 m3 : 23|8@0+ (0.5,0) [0|120] "PCT"  PT
 SG_ moduleHeaterCurrent03_BMS14 m3 : 31|8@0+ (0.05,0) [0|10] "A"  PT
 SG_ cmbOnboardTemperature04_BMS14 m4 : 15|8@0+ (1,-40) [-40|200] "C"  PT
 SG_ cmbOnboardHumidity04_BMS14 m4 : 23|8@0+ (0.5,0) [0|120] "PCT"  PT
 SG_ moduleHeaterCurrent04_BMS14 m4 : 31|8@0+ (0.05,0) [0|10] "A"  PT
 SG_ cmbOnboardTemperature05_BMS14 m5 : 15|8@0+ (1,-40) [-40|200] "C"  PT
 SG_ cmbOnboardHumidity05_BMS14 m5 : 23|8@0+ (0.5,0) [0|120] "PCT"  PT
 SG_ moduleHeaterCurrent05_BMS14 m5 : 31|8@0+ (0.05,0) [0|10] "A"  PT
 SG_ cmbOnboardTemperature06_BMS14 m6 : 15|8@0+ (1,-40) [-40|200] "C"  PT
 SG_ cmbOnboardHumidity06_BMS14 m6 : 23|8@0+ (0.5,0) [0|120] "PCT"  PT
 SG_ moduleHeaterCurrent06_BMS14 m6 : 31|8@0+ (0.05,0) [0|10] "A"  PT
 SG_ cmbOnboardTemperature07_BMS14 m7 : 15|8@0+ (1,-40) [-40|200] "C"  PT
 SG_ cmbOnboardHumidity07_BMS14 m7 : 23|8@0+ (0.5,0) [0|120] "PCT"  PT
 SG_ moduleHeaterCurrent07_BMS14 m7 : 31|8@0+ (0.05,0) [0|10] "A"  PT
 SG_ cmbOnboardTemperature08_BMS14 m8 : 15|8@0+ (1,-40) [-40|200] "C"  PT
 SG_ cmbOnboardHumidity08_BMS14 m8 : 23|8@0+ (0.5,0) [0|120] "PCT"  PT
 SG_ moduleHeaterCurrent08_BMS14 m8 : 31|8@0+ (0.05,0) [0|10] "A"  PT
 SG_ cmbOnboardTemperature09_BMS14 m9 : 15|8@0+ (1,-40) [-40|200] "C"  PT
 SG_ cmbOnboardHumidity09_BMS14 m9 : 23|8@0+ (0.5,0) [0|120] "PCT"  PT
 SG_ moduleHeaterCurrent09_BMS14 m9 : 31|8@0+ (0.05,0) [0|10] "A"  PT
 SG_ cmbOnboardTemperature10_BMS14 m10 : 15|8@0+ (1,-40) [-40|200] "C"  PT
 SG_ cmbOnboardHumidity10_BMS14 m10 : 23|8@0+ (0.5,0) [0|120] "PCT"  PT
 SG_ moduleHeaterCurrent10_BMS14 m10 : 31|8@0+ (0.05,0) [0|10] "A"  PT
 SG_ cmbOnboardTemperature11_BMS14 m11 : 15|8@0+ (1,-40) [-40|200] "C"  PT
 SG_ cmbOnboardHumidity11_BMS14 m11 : 23|8@0+ (0.5,0) [0|120] "PCT"  PT
 SG_ moduleHeaterCurrent11_BMS14 m11 : 31|8@0+ (0.05,0) [0|10] "A"  PT
 SG_ cmbOnboardTemperature12_BMS14 m12 : 15|8@0+ (1,-40) [-40|200] "C"  PT
 SG_ cmbOnboardHumidity12_BMS14 m12 : 23|8@0+ (0.5,0) [0|120] "PCT"  PT
 SG_ moduleHeaterCurrent12_BMS14 m12 : 31|8@0+ (0.05,0) [0|10] "A"  PT
 SG_ cmbOnboardTemperature13_BMS14 m13 : 15|8@0+ (1,-40) [-40|200] "C"  PT
 SG_ cmbOnboardHumidity13_BMS14 m13 : 23|8@0+ (0.5,0) [0|120] "PCT"  PT
 SG_ moduleHeaterCurrent13_BMS14 m13 : 31|8@0+ (0.05,0) [0|10] "A"  PT
 SG_ cmbOnboardTemperature14_BMS14 m14 : 15|8@0+ (1,-40) [-40|200] "C"  PT
 SG_ cmbOnboardHumidity14_BMS14 m14 : 23|8@0+ (0.5,0) [0|120] "PCT"  PT
 SG_ moduleHeaterCurrent14_BMS14 m14 : 31|8@0+ (0.05,0) [0|10] "A"  PT
 SG_ cmbOnboardTemperature15_BMS14 m15 : 15|8@0+ (1,-40) [-40|200] "C"  PT
 SG_ cmbOnboardHumidity15_BMS14 m15 : 23|8@0+ (0.5,0) [0|120] "PCT"  PT
 SG_ moduleHeaterCurrent15_BMS14 m15 : 31|8@0+ (0.05,0) [0|10] "A"  PT
 SG_ cmbOnboardTemperature16_BMS14 m16 : 15|8@0+ (1,-40) [-40|200] "C"  PT
 SG_ cmbOnboardHumidity16_BMS14 m16 : 23|8@0+ (0.5,0) [0|120] "PCT"  PT
 SG_ moduleHeaterCurrent16_BMS14 m16 : 31|8@0+ (0.05,0) [0|10] "A"  PT
 SG_ cmbOnboardTemperature17_BMS14 m17 : 15|8@0+ (1,-40) [-40|200] "C"  PT
 SG_ cmbOnboardHumidity17_BMS14 m17 : 23|8@0+ (0.5,0) [0|120] "PCT"  PT
 SG_ moduleHeaterCurrent17_BMS14 m17 : 31|8@0+ (0.05,0) [0|10] "A"  PT
 SG_ cmbOnboardTemperature18_BMS14 m18 : 15|8@0+ (1,-40) [-40|200] "C"  PT
 SG_ cmbOnboardHumidity18_BMS14 m18 : 23|8@0+ (0.5,0) [0|120] "PCT"  PT
 SG_ moduleHeaterCurrent18_BMS14 m18 : 31|8@0+ (0.05,0) [0|10] "A"  PT
 SG_ cmbOnboardTemperature19_BMS14 m19 : 15|8@0+ (1,-40) [-40|200] "C"  PT
 SG_ cmbOnboardHumidity19_BMS14 m19 : 23|8@0+ (0.5,0) [0|120] "PCT"  PT
 SG_ moduleHeaterCurrent19_BMS14 m19 : 31|8@0+ (0.05,0) [0|10] "A"  PT
 SG_ cmbOnboardTemperature20_BMS14 m20 : 15|8@0+ (1,-40) [-40|200] "C"  PT
 SG_ cmbOnboardHumidity20_BMS14 m20 : 23|8@0+ (0.5,0) [0|120] "PCT"  PT
 SG_ moduleHeaterCurrent20_BMS14 m20 : 31|8@0+ (0.05,0) [0|10] "A"  PT
 SG_ cmbOnboardTemperature21_BMS14 m21 : 15|8@0+ (1,-40) [-40|200] "C"  PT
 SG_ cmbOnboardHumidity21_BMS14 m21 : 23|8@0+ (0.5,0) [0|120] "PCT"  PT
 SG_ moduleHeaterCurrent21_BMS14 m21 : 31|8@0+ (0.05,0) [0|10] "A"  PT
 SG_ cmbOnboardTemperature22_BMS14 m22 : 15|8@0+ (1,-40) [-40|200] "C"  PT
 SG_ cmbOnboardHumidity22_BMS14 m22 : 23|8@0+ (0.5,0) [0|120] "PCT"  PT
 SG_ moduleHeaterCurrent22_BMS14 m22 : 31|8@0+ (0.05,0) [0|10] "A"  PT
 SG_ cmbOnboardTemperature23_BMS14 m23 : 15|8@0+ (1,-40) [-40|200] "C"  PT
 SG_ cmbOnboardHumidity23_BMS14 m23 : 23|8@0+ (0.5,0) [0|120] "PCT"  PT
 SG_ moduleHeaterCurrent23_BMS14 m23 : 31|8@0+ (0.05,0) [0|10] "A"  PT
 SG_ cmbOnboardTemperature24_BMS14 m24 : 15|8@0+ (1,-40) [-40|200] "C"  PT
 SG_ cmbOnboardHumidity24_BMS14 m24 : 23|8@0+ (0.5,0) [0|120] "PCT"  PT
 SG_ moduleHeaterCurrent24_BMS14 m24 : 31|8@0+ (0.05,0) [0|10] "A"  PT
 SG_ cmbOnboardTemperature25_BMS14 m25 : 15|8@0+ (1,-40) [-40|200] "C"  PT
 SG_ cmbOnboardHumidity25_BMS14 m25 : 23|8@0+ (0.5,0) [0|120] "PCT"  PT
 SG_ moduleHeaterCurrent25_BMS14 m25 : 31|8@0+ (0.05,0) [0|10] "A"  PT
 SG_ cmbOnboardTemperature26_BMS14 m26 : 15|8@0+ (1,-40) [-40|200] "C"  PT
 SG_ cmbOnboardHumidity26_BMS14 m26 : 23|8@0+ (0.5,0) [0|120] "PCT"  PT
 SG_ moduleHeaterCurrent26_BMS14 m26 : 31|8@0+ (0.05,0) [0|10] "A"  PT
 SG_ cmbOnboardTemperature27_BMS14 m27 : 15|8@0+ (1,-40) [-40|200] "C"  PT
 SG_ cmbOnboardHumidity27_BMS14 m27 : 23|8@0+ (0.5,0) [0|120] "PCT"  PT
 SG_ moduleHeaterCurrent27_BMS14 m27 : 31|8@0+ (0.05,0) [0|10] "A"  PT
 SG_ cmbOnboardTemperature28_BMS14 m28 : 15|8@0+ (1,-40) [-40|200] "C"  PT
 SG_ cmbOnboardHumidity28_BMS14 m28 : 23|8@0+ (0.5,0) [0|120] "PCT"  PT
 SG_ moduleHeaterCurrent28_BMS14 m28 : 31|8@0+ (0.05,0) [0|10] "A"  PT
 SG_ cmbOnboardTemperature29_BMS14 m29 : 15|8@0+ (1,-40) [-40|200] "C"  PT
 SG_ cmbOnboardHumidity29_BMS14 m29 : 23|8@0+ (0.5,0) [0|120] "PCT"  PT
 SG_ moduleHeaterCurrent29_BMS14 m29 : 31|8@0+ (0.05,0) [0|10] "A"  PT
 SG_ cmbOnboardTemperature30_BMS14 m30 : 15|8@0+ (1,-40) [-40|200] "C"  PT
 SG_ cmbOnboardHumidity30_BMS14 m30 : 23|8@0+ (0.5,0) [0|120] "PCT"  PT
 SG_ moduleHeaterCurrent30_BMS14 m30 : 31|8@0+ (0.05,0) [0|10] "A"  PT
 SG_ cmbOnboardTemperature31_BMS14 m31 : 15|8@0+ (1,-40) [-40|200] "C"  PT
 SG_ cmbOnboardHumidity31_BMS14 m31 : 23|8@0+ (0.5,0) [0|120] "PCT"  PT
 SG_ moduleHeaterCurrent31_BMS14 m31 : 31|8@0+ (0.05,0) [0|10] "A"  PT
 SG_ cmbOnboardTemperature32_BMS14 m32 : 15|8@0+ (1,-40) [-40|200] "C"  PT
 SG_ cmbOnboardHumidity32_BMS14 m32 : 23|8@0+ (0.5,0) [0|120] "PCT"  PT
 SG_ moduleHeaterCurrent32_BMS14 m32 : 31|8@0+ (0.05,0) [0|10] "A"  PT

BO_ 1997 BMS14_DebugCMB: 8 BMS14
 SG_ cmbMultiplexor_BMS14 M : 7|8@0+ (1,0) [0|0] ""  PT
 SG_ moduleTemperature01_BMS14 m1 : 15|8@0+ (1,-40) [-40|200] "C"  PT
 SG_ brickVoltage001_BMS14 m1 : 23|16@0+ (0.0001,0) [0|6.5] "V"  PT
 SG_ brickVoltage002_BMS14 m1 : 39|16@0+ (0.0001,0) [0|6.5] "V"  PT
 SG_ brickVoltage003_BMS14 m1 : 55|16@0+ (0.0001,0) [0|6.5] "V"  PT
 SG_ moduleTemperature02_BMS14 m2 : 15|8@0+ (1,-40) [-40|200] "C"  PT
 SG_ brickVoltage004_BMS14 m2 : 23|16@0+ (0.0001,0) [0|6.5] "V"  PT
 SG_ brickVoltage005_BMS14 m2 : 39|16@0+ (0.0001,0) [0|6.5] "V"  PT
 SG_ brickVoltage006_BMS14 m2 : 55|16@0+ (0.0001,0) [0|6.5] "V"  PT
 SG_ moduleTemperature03_BMS14 m3 : 15|8@0+ (1,-40) [-40|200] "C"  PT
 SG_ brickVoltage007_BMS14 m3 : 23|16@0+ (0.0001,0) [0|6.5] "V"  PT
 SG_ brickVoltage008_BMS14 m3 : 39|16@0+ (0.0001,0) [0|6.5] "V"  PT
 SG_ brickVoltage009_BMS14 m3 : 55|16@0+ (0.0001,0) [0|6.5] "V"  PT
 SG_ moduleTemperature04_BMS14 m4 : 15|8@0+ (1,-40) [-40|200] "C"  PT
 SG_ brickVoltage010_BMS14 m4 : 23|16@0+ (0.0001,0) [0|6.5] "V"  PT
 SG_ brickVoltage011_BMS14 m4 : 39|16@0+ (0.0001,0) [0|6.5] "V"  PT
 SG_ brickVoltage012_BMS14 m4 : 55|16@0+ (0.0001,0) [0|6.5] "V"  PT
 SG_ moduleTemperature05_BMS14 m5 : 15|8@0+ (1,-40) [-40|200] "C"  PT
 SG_ brickVoltage013_BMS14 m5 : 23|16@0+ (0.0001,0) [0|6.5] "V"  PT
 SG_ brickVoltage014_BMS14 m5 : 39|16@0+ (0.0001,0) [0|6.5] "V"  PT
 SG_ brickVoltage015_BMS14 m5 : 55|16@0+ (0.0001,0) [0|6.5] "V"  PT
 SG_ moduleTemperature06_BMS14 m6 : 15|8@0+ (1,-40) [-40|200] "C"  PT
 SG_ brickVoltage016_BMS14 m6 : 23|16@0+ (0.0001,0) [0|6.5] "V"  PT
 SG_ brickVoltage017_BMS14 m6 : 39|16@0+ (0.0001,0) [0|6.5] "V"  PT
 SG_ brickVoltage018_BMS14 m6 : 55|16@0+ (0.0001,0) [0|6.5] "V"  PT
 SG_ moduleTemperature07_BMS14 m7 : 15|8@0+ (1,-40) [-40|200] "C"  PT
 SG_ brickVoltage019_BMS14 m7 : 23|16@0+ (0.0001,0) [0|6.5] "V"  PT
 SG_ brickVoltage020_BMS14 m7 : 39|16@0+ (0.0001,0) [0|6.5] "V"  PT
 SG_ brickVoltage021_BMS14 m7 : 55|16@0+ (0.0001,0) [0|6.5] "V"  PT
 SG_ moduleTemperature08_BMS14 m8 : 15|8@0+ (1,-40) [-40|200] "C"  PT
 SG_ brickVoltage022_BMS14 m8 : 23|16@0+ (0.0001,0) [0|6.5] "V"  PT
 SG_ brickVoltage023_BMS14 m8 : 39|16@0+ (0.0001,0) [0|6.5] "V"  PT
 SG_ brickVoltage024_BMS14 m8 : 55|16@0+ (0.0001,0) [0|6.5] "V"  PT
 SG_ moduleTemperature09_BMS14 m9 : 15|8@0+ (1,-40) [-40|200] "C"  PT
 SG_ brickVoltage025_BMS14 m9 : 23|16@0+ (0.0001,0) [0|6.5] "V"  PT
 SG_ brickVoltage026_BMS14 m9 : 39|16@0+ (0.0001,0) [0|6.5] "V"  PT
 SG_ brickVoltage027_BMS14 m9 : 55|16@0+ (0.0001,0) [0|6.5] "V"  PT
 SG_ moduleTemperature10_BMS14 m10 : 15|8@0+ (1,-40) [-40|200] "C"  PT
 SG_ brickVoltage028_BMS14 m10 : 23|16@0+ (0.0001,0) [0|6.5] "V"  PT
 SG_ brickVoltage029_BMS14 m10 : 39|16@0+ (0.0001,0) [0|6.5] "V"  PT
 SG_ brickVoltage030_BMS14 m10 : 55|16@0+ (0.0001,0) [0|6.5] "V"  PT
 SG_ moduleTemperature11_BMS14 m11 : 15|8@0+ (1,-40) [-40|200] "C"  PT
 SG_ brickVoltage031_BMS14 m11 : 23|16@0+ (0.0001,0) [0|6.5] "V"  PT
 SG_ brickVoltage032_BMS14 m11 : 39|16@0+ (0.0001,0) [0|6.5] "V"  PT
 SG_ brickVoltage033_BMS14 m11 : 55|16@0+ (0.0001,0) [0|6.5] "V"  PT
 SG_ moduleTemperature12_BMS14 m12 : 15|8@0+ (1,-40) [-40|200] "C"  PT
 SG_ brickVoltage034_BMS14 m12 : 23|16@0+ (0.0001,0) [0|6.5] "V"  PT
 SG_ brickVoltage035_BMS14 m12 : 39|16@0+ (0.0001,0) [0|6.5] "V"  PT
 SG_ brickVoltage036_BMS14 m12 : 55|16@0+ (0.0001,0) [0|6.5] "V"  PT
 SG_ moduleTemperature13_BMS14 m13 : 15|8@0+ (1,-40) [-40|200] "C"  PT
 SG_ brickVoltage037_BMS14 m13 : 23|16@0+ (0.0001,0) [0|6.5] "V"  PT
 SG_ brickVoltage038_BMS14 m13 : 39|16@0+ (0.0001,0) [0|6.5] "V"  PT
 SG_ brickVoltage039_BMS14 m13 : 55|16@0+ (0.0001,0) [0|6.5] "V"  PT
 SG_ moduleTemperature14_BMS14 m14 : 15|8@0+ (1,-40) [-40|200] "C"  PT
 SG_ brickVoltage040_BMS14 m14 : 23|16@0+ (0.0001,0) [0|6.5] "V"  PT
 SG_ brickVoltage041_BMS14 m14 : 39|16@0+ (0.0001,0) [0|6.5] "V"  PT
 SG_ brickVoltage042_BMS14 m14 : 55|16@0+ (0.0001,0) [0|6.5] "V"  PT
 SG_ moduleTemperature15_BMS14 m15 : 15|8@0+ (1,-40) [-40|200] "C"  PT
 SG_ brickVoltage043_BMS14 m15 : 23|16@0+ (0.0001,0) [0|6.5] "V"  PT
 SG_ brickVoltage044_BMS14 m15 : 39|16@0+ (0.0001,0) [0|6.5] "V"  PT
 SG_ brickVoltage045_BMS14 m15 : 55|16@0+ (0.0001,0) [0|6.5] "V"  PT
 SG_ moduleTemperature16_BMS14 m16 : 15|8@0+ (1,-40) [-40|200] "C"  PT
 SG_ brickVoltage046_BMS14 m16 : 23|16@0+ (0.0001,0) [0|6.5] "V"  PT
 SG_ brickVoltage047_BMS14 m16 : 39|16@0+ (0.0001,0) [0|6.5] "V"  PT
 SG_ brickVoltage048_BMS14 m16 : 55|16@0+ (0.0001,0) [0|6.5] "V"  PT
 SG_ moduleTemperature17_BMS14 m17 : 15|8@0+ (1,-40) [-40|200] "C"  PT
 SG_ brickVoltage049_BMS14 m17 : 23|16@0+ (0.0001,0) [0|6.5] "V"  PT
 SG_ brickVoltage050_BMS14 m17 : 39|16@0+ (0.0001,0) [0|6.5] "V"  PT
 SG_ brickVoltage051_BMS14 m17 : 55|16@0+ (0.0001,0) [0|6.5] "V"  PT
 SG_ moduleTemperature18_BMS14 m18 : 15|8@0+ (1,-40) [-40|200] "C"  PT
 SG_ brickVoltage052_BMS14 m18 : 23|16@0+ (0.0001,0) [0|6.5] "V"  PT
 SG_ brickVoltage053_BMS14 m18 : 39|16@0+ (0.0001,0) [0|6.5] "V"  PT
 SG_ brickVoltage054_BMS14 m18 : 55|16@0+ (0.0001,0) [0|6.5] "V"  PT
 SG_ moduleTemperature19_BMS14 m19 : 15|8@0+ (1,-40) [-40|200] "C"  PT
 SG_ brickVoltage055_BMS14 m19 : 23|16@0+ (0.0001,0) [0|6.5] "V"  PT
 SG_ brickVoltage056_BMS14 m19 : 39|16@0+ (0.0001,0) [0|6.5] "V"  PT
 SG_ brickVoltage057_BMS14 m19 : 55|16@0+ (0.0001,0) [0|6.5] "V"  PT
 SG_ moduleTemperature20_BMS14 m20 : 15|8@0+ (1,-40) [-40|200] "C"  PT
 SG_ brickVoltage058_BMS14 m20 : 23|16@0+ (0.0001,0) [0|6.5] "V"  PT
 SG_ brickVoltage059_BMS14 m20 : 39|16@0+ (0.0001,0) [0|6.5] "V"  PT
 SG_ brickVoltage060_BMS14 m20 : 55|16@0+ (0.0001,0) [0|6.5] "V"  PT
 SG_ moduleTemperature21_BMS14 m21 : 15|8@0+ (1,-40) [-40|200] "C"  PT
 SG_ brickVoltage061_BMS14 m21 : 23|16@0+ (0.0001,0) [0|6.5] "V"  PT
 SG_ brickVoltage062_BMS14 m21 : 39|16@0+ (0.0001,0) [0|6.5] "V"  PT
 SG_ brickVoltage063_BMS14 m21 : 55|16@0+ (0.0001,0) [0|6.5] "V"  PT
 SG_ moduleTemperature22_BMS14 m22 : 15|8@0+ (1,-40) [-40|200] "C"  PT
 SG_ brickVoltage064_BMS14 m22 : 23|16@0+ (0.0001,0) [0|6.5] "V"  PT
 SG_ brickVoltage065_BMS14 m22 : 39|16@0+ (0.0001,0) [0|6.5] "V"  PT
 SG_ brickVoltage066_BMS14 m22 : 55|16@0+ (0.0001,0) [0|6.5] "V"  PT
 SG_ moduleTemperature23_BMS14 m23 : 15|8@0+ (1,-40) [-40|200] "C"  PT
 SG_ brickVoltage067_BMS14 m23 : 23|16@0+ (0.0001,0) [0|6.5] "V"  PT
 SG_ brickVoltage068_BMS14 m23 : 39|16@0+ (0.0001,0) [0|6.5] "V"  PT
 SG_ brickVoltage069_BMS14 m23 : 55|16@0+ (0.0001,0) [0|6.5] "V"  PT
 SG_ moduleTemperature24_BMS14 m24 : 15|8@0+ (1,-40) [-40|200] "C"  PT
 SG_ brickVoltage070_BMS14 m24 : 23|16@0+ (0.0001,0) [0|6.5] "V"  PT
 SG_ brickVoltage071_BMS14 m24 : 39|16@0+ (0.0001,0) [0|6.5] "V"  PT
 SG_ brickVoltage072_BMS14 m24 : 55|16@0+ (0.0001,0) [0|6.5] "V"  PT
 SG_ moduleTemperature25_BMS14 m25 : 15|8@0+ (1,-40) [-40|200] "C"  PT
 SG_ brickVoltage073_BMS14 m25 : 23|16@0+ (0.0001,0) [0|6.5] "V"  PT
 SG_ brickVoltage074_BMS14 m25 : 39|16@0+ (0.0001,0) [0|6.5] "V"  PT
 SG_ brickVoltage075_BMS14 m25 : 55|16@0+ (0.0001,0) [0|6.5] "V"  PT
 SG_ moduleTemperature26_BMS14 m26 : 15|8@0+ (1,-40) [-40|200] "C"  PT
 SG_ brickVoltage076_BMS14 m26 : 23|16@0+ (0.0001,0) [0|6.5] "V"  PT
 SG_ brickVoltage077_BMS14 m26 : 39|16@0+ (0.0001,0) [0|6.5] "V"  PT
 SG_ brickVoltage078_BMS14 m26 : 55|16@0+ (0.0001,0) [0|6.5] "V"  PT
 SG_ moduleTemperature27_BMS14 m27 : 15|8@0+ (1,-40) [-40|200] "C"  PT
 SG_ brickVoltage079_BMS14 m27 : 23|16@0+ (0.0001,0) [0|6.5] "V"  PT
 SG_ brickVoltage080_BMS14 m27 : 39|16@0+ (0.0001,0) [0|6.5] "V"  PT
 SG_ brickVoltage081_BMS14 m27 : 55|16@0+ (0.0001,0) [0|6.5] "V"  PT
 SG_ moduleTemperature28_BMS14 m28 : 15|8@0+ (1,-40) [-40|200] "C"  PT
 SG_ brickVoltage082_BMS14 m28 : 23|16@0+ (0.0001,0) [0|6.5] "V"  PT
 SG_ brickVoltage083_BMS14 m28 : 39|16@0+ (0.0001,0) [0|6.5] "V"  PT
 SG_ brickVoltage084_BMS14 m28 : 55|16@0+ (0.0001,0) [0|6.5] "V"  PT
 SG_ moduleTemperature29_BMS14 m29 : 15|8@0+ (1,-40) [-40|200] "C"  PT
 SG_ brickVoltage085_BMS14 m29 : 23|16@0+ (0.0001,0) [0|6.5] "V"  PT
 SG_ brickVoltage086_BMS14 m29 : 39|16@0+ (0.0001,0) [0|6.5] "V"  PT
 SG_ brickVoltage087_BMS14 m29 : 55|16@0+ (0.0001,0) [0|6.5] "V"  PT
 SG_ moduleTemperature30_BMS14 m30 : 15|8@0+ (1,-40) [-40|200] "C"  PT
 SG_ brickVoltage088_BMS14 m30 : 23|16@0+ (0.0001,0) [0|6.5] "V"  PT
 SG_ brickVoltage089_BMS14 m30 : 39|16@0+ (0.0001,0) [0|6.5] "V"  PT
 SG_ brickVoltage090_BMS14 m30 : 55|16@0+ (0.0001,0) [0|6.5] "V"  PT
 SG_ moduleTemperature31_BMS14 m31 : 15|8@0+ (1,-40) [-40|200] "C"  PT
 SG_ brickVoltage091_BMS14 m31 : 23|16@0+ (0.0001,0) [0|6.5] "V"  PT
 SG_ brickVoltage092_BMS14 m31 : 39|16@0+ (0.0001,0) [0|6.5] "V"  PT
 SG_ brickVoltage093_BMS14 m31 : 55|16@0+ (0.0001,0) [0|6.5] "V"  PT
 SG_ moduleTemperature32_BMS14 m32 : 15|8@0+ (1,-40) [-40|200] "C"  PT
 SG_ brickVoltage094_BMS14 m32 : 23|16@0+ (0.0001,0) [0|6.5] "V"  PT
 SG_ brickVoltage095_BMS14 m32 : 39|16@0+ (0.0001,0) [0|6.5] "V"  PT
 SG_ brickVoltage096_BMS14 m32 : 55|16@0+ (0.0001,0) [0|6.5] "V"  PT
 SG_ brickVoltage097_BMS14 m33 : 23|16@0+ (0.0001,0) [0|6.5] "V"  PT
 SG_ brickVoltage098_BMS14 m33 : 39|16@0+ (0.0001,0) [0|6.5] "V"  PT
 SG_ brickVoltage099_BMS14 m33 : 55|16@0+ (0.0001,0) [0|6.5] "V"  PT
 SG_ brickVoltage100_BMS14 m34 : 23|16@0+ (0.0001,0) [0|6.5] "V"  PT
 SG_ brickVoltage101_BMS14 m34 : 39|16@0+ (0.0001,0) [0|6.5] "V"  PT
 SG_ brickVoltage102_BMS14 m34 : 55|16@0+ (0.0001,0) [0|6.5] "V"  PT
 SG_ brickVoltage103_BMS14 m35 : 23|16@0+ (0.0001,0) [0|6.5] "V"  PT
 SG_ brickVoltage104_BMS14 m35 : 39|16@0+ (0.0001,0) [0|6.5] "V"  PT
 SG_ brickVoltage105_BMS14 m35 : 55|16@0+ (0.0001,0) [0|6.5] "V"  PT
 SG_ brickVoltage106_BMS14 m36 : 23|16@0+ (0.0001,0) [0|6.5] "V"  PT
 SG_ brickVoltage107_BMS14 m36 : 39|16@0+ (0.0001,0) [0|6.5] "V"  PT
 SG_ brickVoltage108_BMS14 m36 : 55|16@0+ (0.0001,0) [0|6.5] "V"  PT
 SG_ brickVoltage109_BMS14 m37 : 23|16@0+ (0.0001,0) [0|6.5] "V"  PT
 SG_ brickVoltage110_BMS14 m37 : 39|16@0+ (0.0001,0) [0|6.5] "V"  PT
 SG_ brickVoltage111_BMS14 m37 : 55|16@0+ (0.0001,0) [0|6.5] "V"  PT
 SG_ brickVoltage112_BMS14 m38 : 23|16@0+ (0.0001,0) [0|6.5] "V"  PT
 SG_ brickVoltage113_BMS14 m38 : 39|16@0+ (0.0001,0) [0|6.5] "V"  PT
 SG_ brickVoltage114_BMS14 m38 : 55|16@0+ (0.0001,0) [0|6.5] "V"  PT
 SG_ brickVoltage115_BMS14 m39 : 23|16@0+ (0.0001,0) [0|6.5] "V"  PT
 SG_ brickVoltage116_BMS14 m39 : 39|16@0+ (0.0001,0) [0|6.5] "V"  PT
 SG_ brickVoltage117_BMS14 m39 : 55|16@0+ (0.0001,0) [0|6.5] "V"  PT
 SG_ brickVoltage118_BMS14 m40 : 23|16@0+ (0.0001,0) [0|6.5] "V"  PT
 SG_ brickVoltage119_BMS14 m40 : 39|16@0+ (0.0001,0) [0|6.5] "V"  PT
 SG_ brickVoltage120_BMS14 m40 : 55|16@0+ (0.0001,0) [0|6.5] "V"  PT
 SG_ brickVoltage121_BMS14 m41 : 23|16@0+ (0.0001,0) [0|6.5] "V"  PT
 SG_ brickVoltage122_BMS14 m41 : 39|16@0+ (0.0001,0) [0|6.5] "V"  PT
 SG_ brickVoltage123_BMS14 m41 : 55|16@0+ (0.0001,0) [0|6.5] "V"  PT
 SG_ brickVoltage124_BMS14 m42 : 23|16@0+ (0.0001,0) [0|6.5] "V"  PT
 SG_ brickVoltage125_BMS14 m42 : 39|16@0+ (0.0001,0) [0|6.5] "V"  PT
 SG_ brickVoltage126_BMS14 m42 : 55|16@0+ (0.0001,0) [0|6.5] "V"  PT
 SG_ brickVoltage127_BMS14 m43 : 23|16@0+ (0.0001,0) [0|6.5] "V"  PT
 SG_ brickVoltage128_BMS14 m43 : 39|16@0+ (0.0001,0) [0|6.5] "V"  PT
 SG_ brickVoltage129_BMS14 m43 : 55|16@0+ (0.0001,0) [0|6.5] "V"  PT
 SG_ brickVoltage130_BMS14 m44 : 23|16@0+ (0.0001,0) [0|6.5] "V"  PT
 SG_ brickVoltage131_BMS14 m44 : 39|16@0+ (0.0001,0) [0|6.5] "V"  PT
 SG_ brickVoltage132_BMS14 m44 : 55|16@0+ (0.0001,0) [0|6.5] "V"  PT
 SG_ brickVoltage133_BMS14 m45 : 23|16@0+ (0.0001,0) [0|6.5] "V"  PT
 SG_ brickVoltage134_BMS14 m45 : 39|16@0+ (0.0001,0) [0|6.5] "V"  PT
 SG_ brickVoltage135_BMS14 m45 : 55|16@0+ (0.0001,0) [0|6.5] "V"  PT
 SG_ brickVoltage136_BMS14 m46 : 23|16@0+ (0.0001,0) [0|6.5] "V"  PT
 SG_ brickVoltage137_BMS14 m46 : 39|16@0+ (0.0001,0) [0|6.5] "V"  PT
 SG_ brickVoltage138_BMS14 m46 : 55|16@0+ (0.0001,0) [0|6.5] "V"  PT
 SG_ brickVoltage139_BMS14 m47 : 23|16@0+ (0.0001,0) [0|6.5] "V"  PT
 SG_ brickVoltage140_BMS14 m47 : 39|16@0+ (0.0001,0) [0|6.5] "V"  PT
 SG_ brickVoltage141_BMS14 m47 : 55|16@0+ (0.0001,0) [0|6.5] "V"  PT
 SG_ brickVoltage142_BMS14 m48 : 23|16@0+ (0.0001,0) [0|6.5] "V"  PT
 SG_ brickVoltage143_BMS14 m48 : 39|16@0+ (0.0001,0) [0|6.5] "V"  PT
 SG_ brickVoltage144_BMS14 m48 : 55|16@0+ (0.0001,0) [0|6.5] "V"  PT
 SG_ brickVoltage145_BMS14 m49 : 23|16@0+ (0.0001,0) [0|6.5] "V"  PT
 SG_ brickVoltage146_BMS14 m49 : 39|16@0+ (0.0001,0) [0|6.5] "V"  PT
 SG_ brickVoltage147_BMS14 m49 : 55|16@0+ (0.0001,0) [0|6.5] "V"  PT
 SG_ brickVoltage148_BMS14 m50 : 23|16@0+ (0.0001,0) [0|6.5] "V"  PT
 SG_ brickVoltage149_BMS14 m50 : 39|16@0+ (0.0001,0) [0|6.5] "V"  PT
 SG_ brickVoltage150_BMS14 m50 : 55|16@0+ (0.0001,0) [0|6.5] "V"  PT
 SG_ brickVoltage151_BMS14 m51 : 23|16@0+ (0.0001,0) [0|6.5] "V"  PT
 SG_ brickVoltage152_BMS14 m51 : 39|16@0+ (0.0001,0) [0|6.5] "V"  PT
 SG_ brickVoltage153_BMS14 m51 : 55|16@0+ (0.0001,0) [0|6.5] "V"  PT
 SG_ brickVoltage154_BMS14 m52 : 23|16@0+ (0.0001,0) [0|6.5] "V"  PT
 SG_ brickVoltage155_BMS14 m52 : 39|16@0+ (0.0001,0) [0|6.5] "V"  PT
 SG_ brickVoltage156_BMS14 m52 : 55|16@0+ (0.0001,0) [0|6.5] "V"  PT
 SG_ brickVoltage157_BMS14 m53 : 23|16@0+ (0.0001,0) [0|6.5] "V"  PT
 SG_ brickVoltage158_BMS14 m53 : 39|16@0+ (0.0001,0) [0|6.5] "V"  PT
 SG_ brickVoltage159_BMS14 m53 : 55|16@0+ (0.0001,0) [0|6.5] "V"  PT
 SG_ brickVoltage160_BMS14 m54 : 23|16@0+ (0.0001,0) [0|6.5] "V"  PT
 SG_ brickVoltage161_BMS14 m54 : 39|16@0+ (0.0001,0) [0|6.5] "V"  PT
 SG_ brickVoltage162_BMS14 m54 : 55|16@0+ (0.0001,0) [0|6.5] "V"  PT
 SG_ brickVoltage163_BMS14 m55 : 23|16@0+ (0.0001,0) [0|6.5] "V"  PT
 SG_ brickVoltage164_BMS14 m55 : 39|16@0+ (0.0001,0) [0|6.5] "V"  PT
 SG_ brickVoltage165_BMS14 m55 : 55|16@0+ (0.0001,0) [0|6.5] "V"  PT
 SG_ brickVoltage166_BMS14 m56 : 23|16@0+ (0.0001,0) [0|6.5] "V"  PT
 SG_ brickVoltage167_BMS14 m56 : 39|16@0+ (0.0001,0) [0|6.5] "V"  PT
 SG_ brickVoltage168_BMS14 m56 : 55|16@0+ (0.0001,0) [0|6.5] "V"  PT
 SG_ brickVoltage169_BMS14 m57 : 23|16@0+ (0.0001,0) [0|6.5] "V"  PT
 SG_ brickVoltage170_BMS14 m57 : 39|16@0+ (0.0001,0) [0|6.5] "V"  PT
 SG_ brickVoltage171_BMS14 m57 : 55|16@0+ (0.0001,0) [0|6.5] "V"  PT
 SG_ brickVoltage172_BMS14 m58 : 23|16@0+ (0.0001,0) [0|6.5] "V"  PT
 SG_ brickVoltage173_BMS14 m58 : 39|16@0+ (0.0001,0) [0|6.5] "V"  PT
 SG_ brickVoltage174_BMS14 m58 : 55|16@0+ (0.0001,0) [0|6.5] "V"  PT
 SG_ brickVoltage175_BMS14 m59 : 23|16@0+ (0.0001,0) [0|6.5] "V"  PT
 SG_ brickVoltage176_BMS14 m59 : 39|16@0+ (0.0001,0) [0|6.5] "V"  PT
 SG_ brickVoltage177_BMS14 m59 : 55|16@0+ (0.0001,0) [0|6.5] "V"  PT
 SG_ brickVoltage178_BMS14 m60 : 23|16@0+ (0.0001,0) [0|6.5] "V"  PT
 SG_ brickVoltage179_BMS14 m60 : 39|16@0+ (0.0001,0) [0|6.5] "V"  PT
 SG_ brickVoltage180_BMS14 m60 : 55|16@0+ (0.0001,0) [0|6.5] "V"  PT
 SG_ brickVoltage181_BMS14 m61 : 23|16@0+ (0.0001,0) [0|6.5] "V"  PT
 SG_ brickVoltage182_BMS14 m61 : 39|16@0+ (0.0001,0) [0|6.5] "V"  PT
 SG_ brickVoltage183_BMS14 m61 : 55|16@0+ (0.0001,0) [0|6.5] "V"  PT
 SG_ brickVoltage184_BMS14 m62 : 23|16@0+ (0.0001,0) [0|6.5] "V"  PT
 SG_ brickVoltage185_BMS14 m62 : 39|16@0+ (0.0001,0) [0|6.5] "V"  PT
 SG_ brickVoltage186_BMS14 m62 : 55|16@0+ (0.0001,0) [0|6.5] "V"  PT
 SG_ brickVoltage187_BMS14 m63 : 23|16@0+ (0.0001,0) [0|6.5] "V"  PT
 SG_ brickVoltage188_BMS14 m63 : 39|16@0+ (0.0001,0) [0|6.5] "V"  PT
 SG_ brickVoltage189_BMS14 m63 : 55|16@0+ (0.0001,0) [0|6.5] "V"  PT
 SG_ brickVoltage190_BMS14 m64 : 23|16@0+ (0.0001,0) [0|6.5] "V"  PT
 SG_ brickVoltage191_BMS14 m64 : 39|16@0+ (0.0001,0) [0|6.5] "V"  PT
 SG_ brickVoltage192_BMS14 m64 : 55|16@0+ (0.0001,0) [0|6.5] "V"  PT
 SG_ brickVoltage193_BMS14 m65 : 23|16@0+ (0.0001,0) [0|6.5] "V"  PT
 SG_ brickVoltage194_BMS14 m65 : 39|16@0+ (0.0001,0) [0|6.5] "V"  PT
 SG_ brickVoltage195_BMS14 m65 : 55|16@0+ (0.0001,0) [0|6.5] "V"  PT
 SG_ brickVoltage196_BMS14 m66 : 23|16@0+ (0.0001,0) [0|6.5] "V"  PT
 SG_ brickVoltage197_BMS14 m66 : 39|16@0+ (0.0001,0) [0|6.5] "V"  PT
 SG_ brickVoltage198_BMS14 m66 : 55|16@0+ (0.0001,0) [0|6.5] "V"  PT
 SG_ brickVoltage199_BMS14 m67 : 23|16@0+ (0.0001,0) [0|6.5] "V"  PT
 SG_ brickVoltage200_BMS14 m67 : 39|16@0+ (0.0001,0) [0|6.5] "V"  PT
 SG_ brickVoltage201_BMS14 m67 : 55|16@0+ (0.0001,0) [0|6.5] "V"  PT
 SG_ brickVoltage202_BMS14 m68 : 23|16@0+ (0.0001,0) [0|6.5] "V"  PT
 SG_ brickVoltage203_BMS14 m68 : 39|16@0+ (0.0001,0) [0|6.5] "V"  PT
 SG_ brickVoltage204_BMS14 m68 : 55|16@0+ (0.0001,0) [0|6.5] "V"  PT
 SG_ brickVoltage205_BMS14 m69 : 23|16@0+ (0.0001,0) [0|6.5] "V"  PT
 SG_ brickVoltage206_BMS14 m69 : 39|16@0+ (0.0001,0) [0|6.5] "V"  PT
 SG_ brickVoltage207_BMS14 m69 : 55|16@0+ (0.0001,0) [0|6.5] "V"  PT
 SG_ brickVoltage208_BMS14 m70 : 23|16@0+ (0.0001,0) [0|6.5] "V"  PT
 SG_ brickVoltage209_BMS14 m70 : 39|16@0+ (0.0001,0) [0|6.5] "V"  PT
 SG_ brickVoltage210_BMS14 m70 : 55|16@0+ (0.0001,0) [0|6.5] "V"  PT
 SG_ brickVoltage211_BMS14 m71 : 23|16@0+ (0.0001,0) [0|6.5] "V"  PT
 SG_ brickVoltage212_BMS14 m71 : 39|16@0+ (0.0001,0) [0|6.5] "V"  PT
 SG_ brickVoltage213_BMS14 m71 : 55|16@0+ (0.0001,0) [0|6.5] "V"  PT
 SG_ brickVoltage214_BMS14 m72 : 23|16@0+ (0.0001,0) [0|6.5] "V"  PT
 SG_ brickVoltage215_BMS14 m72 : 39|16@0+ (0.0001,0) [0|6.5] "V"  PT
 SG_ brickVoltage216_BMS14 m72 : 55|16@0+ (0.0001,0) [0|6.5] "V"  PT
 SG_ brickVoltage217_BMS14 m73 : 23|16@0+ (0.0001,0) [0|6.5] "V"  PT
 SG_ brickVoltage218_BMS14 m73 : 39|16@0+ (0.0001,0) [0|6.5] "V"  PT
 SG_ brickVoltage219_BMS14 m73 : 55|16@0+ (0.0001,0) [0|6.5] "V"  PT
 SG_ brickVoltage220_BMS14 m74 : 23|16@0+ (0.0001,0) [0|6.5] "V"  PT
 SG_ brickVoltage221_BMS14 m74 : 39|16@0+ (0.0001,0) [0|6.5] "V"  PT
 SG_ brickVoltage222_BMS14 m74 : 55|16@0+ (0.0001,0) [0|6.5] "V"  PT
 SG_ brickVoltage223_BMS14 m75 : 23|16@0+ (0.0001,0) [0|6.5] "V"  PT
 SG_ brickVoltage224_BMS14 m75 : 39|16@0+ (0.0001,0) [0|6.5] "V"  PT
 SG_ brickVoltage225_BMS14 m75 : 55|16@0+ (0.0001,0) [0|6.5] "V"  PT
 SG_ brickVoltage226_BMS14 m76 : 23|16@0+ (0.0001,0) [0|6.5] "V"  PT
 SG_ brickVoltage227_BMS14 m76 : 39|16@0+ (0.0001,0) [0|6.5] "V"  PT
 SG_ brickVoltage228_BMS14 m76 : 55|16@0+ (0.0001,0) [0|6.5] "V"  PT
 SG_ brickVoltage229_BMS14 m77 : 23|16@0+ (0.0001,0) [0|6.5] "V"  PT
 SG_ brickVoltage230_BMS14 m77 : 39|16@0+ (0.0001,0) [0|6.5] "V"  PT
 SG_ brickVoltage231_BMS14 m77 : 55|16@0+ (0.0001,0) [0|6.5] "V"  PT
 SG_ brickVoltage232_BMS14 m78 : 23|16@0+ (0.0001,0) [0|6.5] "V"  PT
 SG_ brickVoltage233_BMS14 m78 : 39|16@0+ (0.0001,0) [0|6.5] "V"  PT
 SG_ brickVoltage234_BMS14 m78 : 55|16@0+ (0.0001,0) [0|6.5] "V"  PT
 SG_ brickVoltage235_BMS14 m79 : 23|16@0+ (0.0001,0) [0|6.5] "V"  PT
 SG_ brickVoltage236_BMS14 m79 : 39|16@0+ (0.0001,0) [0|6.5] "V"  PT
 SG_ brickVoltage237_BMS14 m79 : 55|16@0+ (0.0001,0) [0|6.5] "V"  PT
 SG_ brickVoltage238_BMS14 m80 : 23|16@0+ (0.0001,0) [0|6.5] "V"  PT
 SG_ brickVoltage239_BMS14 m80 : 39|16@0+ (0.0001,0) [0|6.5] "V"  PT
 SG_ brickVoltage240_BMS14 m80 : 55|16@0+ (0.0001,0) [0|6.5] "V"  PT
 SG_ brickVoltage241_BMS14 m81 : 23|16@0+ (0.0001,0) [0|6.5] "V"  PT
 SG_ brickVoltage242_BMS14 m81 : 39|16@0+ (0.0001,0) [0|6.5] "V"  PT
 SG_ brickVoltage243_BMS14 m81 : 55|16@0+ (0.0001,0) [0|6.5] "V"  PT
 SG_ brickVoltage244_BMS14 m82 : 23|16@0+ (0.0001,0) [0|6.5] "V"  PT
 SG_ brickVoltage245_BMS14 m82 : 39|16@0+ (0.0001,0) [0|6.5] "V"  PT
 SG_ brickVoltage246_BMS14 m82 : 55|16@0+ (0.0001,0) [0|6.5] "V"  PT
 SG_ brickVoltage247_BMS14 m83 : 23|16@0+ (0.0001,0) [0|6.5] "V"  PT
 SG_ brickVoltage248_BMS14 m83 : 39|16@0+ (0.0001,0) [0|6.5] "V"  PT
 SG_ brickVoltage249_BMS14 m83 : 55|16@0+ (0.0001,0) [0|6.5] "V"  PT
 SG_ brickVoltage250_BMS14 m84 : 23|16@0+ (0.0001,0) [0|6.5] "V"  PT
 SG_ brickVoltage251_BMS14 m84 : 39|16@0+ (0.0001,0) [0|6.5] "V"  PT
 SG_ brickVoltage252_BMS14 m84 : 55|16@0+ (0.0001,0) [0|6.5] "V"  PT
 SG_ brickVoltage253_BMS14 m85 : 23|16@0+ (0.0001,0) [0|6.5] "V"  PT
 SG_ brickVoltage254_BMS14 m85 : 39|16@0+ (0.0001,0) [0|6.5] "V"  PT
 SG_ brickVoltage255_BMS14 m85 : 55|16@0+ (0.0001,0) [0|6.5] "V"  PT
 SG_ brickVoltage256_BMS14 m86 : 23|16@0+ (0.0001,0) [0|6.5] "V"  PT
 SG_ brickVoltage257_BMS14 m86 : 39|16@0+ (0.0001,0) [0|6.5] "V"  PT
 SG_ brickVoltage258_BMS14 m86 : 55|16@0+ (0.0001,0) [0|6.5] "V"  PT
 SG_ brickVoltage259_BMS14 m87 : 23|16@0+ (0.0001,0) [0|6.5] "V"  PT
 SG_ brickVoltage260_BMS14 m87 : 39|16@0+ (0.0001,0) [0|6.5] "V"  PT
 SG_ brickVoltage261_BMS14 m87 : 55|16@0+ (0.0001,0) [0|6.5] "V"  PT
 SG_ brickVoltage262_BMS14 m88 : 23|16@0+ (0.0001,0) [0|6.5] "V"  PT
 SG_ brickVoltage263_BMS14 m88 : 39|16@0+ (0.0001,0) [0|6.5] "V"  PT
 SG_ brickVoltage264_BMS14 m88 : 55|16@0+ (0.0001,0) [0|6.5] "V"  PT
 SG_ brickVoltage265_BMS14 m89 : 23|16@0+ (0.0001,0) [0|6.5] "V"  PT
 SG_ brickVoltage266_BMS14 m89 : 39|16@0+ (0.0001,0) [0|6.5] "V"  PT
 SG_ brickVoltage267_BMS14 m89 : 55|16@0+ (0.0001,0) [0|6.5] "V"  PT
 SG_ brickVoltage268_BMS14 m90 : 23|16@0+ (0.0001,0) [0|6.5] "V"  PT
 SG_ brickVoltage269_BMS14 m90 : 39|16@0+ (0.0001,0) [0|6.5] "V"  PT
 SG_ brickVoltage270_BMS14 m90 : 55|16@0+ (0.0001,0) [0|6.5] "V"  PT
 SG_ brickVoltage271_BMS14 m91 : 23|16@0+ (0.0001,0) [0|6.5] "V"  PT
 SG_ brickVoltage272_BMS14 m91 : 39|16@0+ (0.0001,0) [0|6.5] "V"  PT
 SG_ brickVoltage273_BMS14 m91 : 55|16@0+ (0.0001,0) [0|6.5] "V"  PT
 SG_ brickVoltage274_BMS14 m92 : 23|16@0+ (0.0001,0) [0|6.5] "V"  PT
 SG_ brickVoltage275_BMS14 m92 : 39|16@0+ (0.0001,0) [0|6.5] "V"  PT
 SG_ brickVoltage276_BMS14 m92 : 55|16@0+ (0.0001,0) [0|6.5] "V"  PT
 SG_ brickVoltage277_BMS14 m93 : 23|16@0+ (0.0001,0) [0|6.5] "V"  PT
 SG_ brickVoltage278_BMS14 m93 : 39|16@0+ (0.0001,0) [0|6.5] "V"  PT
 SG_ brickVoltage279_BMS14 m93 : 55|16@0+ (0.0001,0) [0|6.5] "V"  PT
 SG_ brickVoltage280_BMS14 m94 : 23|16@0+ (0.0001,0) [0|6.5] "V"  PT
 SG_ brickVoltage281_BMS14 m94 : 39|16@0+ (0.0001,0) [0|6.5] "V"  PT
 SG_ brickVoltage282_BMS14 m94 : 55|16@0+ (0.0001,0) [0|6.5] "V"  PT
 SG_ brickVoltage283_BMS14 m95 : 23|16@0+ (0.0001,0) [0|6.5] "V"  PT
 SG_ brickVoltage284_BMS14 m95 : 39|16@0+ (0.0001,0) [0|6.5] "V"  PT
 SG_ brickVoltage285_BMS14 m95 : 55|16@0+ (0.0001,0) [0|6.5] "V"  PT
 SG_ brickVoltage286_BMS14 m96 : 23|16@0+ (0.0001,0) [0|6.5] "V"  PT
 SG_ brickVoltage287_BMS14 m96 : 39|16@0+ (0.0001,0) [0|6.5] "V"  PT
 SG_ brickVoltage288_BMS14 m96 : 55|16@0+ (0.0001,0) [0|6.5] "V"  PT
 SG_ brickVoltage289_BMS14 m97 : 23|16@0+ (0.0001,0) [0|6.5] "V"  PT
 SG_ brickVoltage290_BMS14 m97 : 39|16@0+ (0.0001,0) [0|6.5] "V"  PT
 SG_ brickVoltage291_BMS14 m97 : 55|16@0+ (0.0001,0) [0|6.5] "V"  PT
 SG_ brickVoltage292_BMS14 m98 : 23|16@0+ (0.0001,0) [0|6.5] "V"  PT
 SG_ brickVoltage293_BMS14 m98 : 39|16@0+ (0.0001,0) [0|6.5] "V"  PT
 SG_ brickVoltage294_BMS14 m98 : 55|16@0+ (0.0001,0) [0|6.5] "V"  PT
 SG_ brickVoltage295_BMS14 m99 : 23|16@0+ (0.0001,0) [0|6.5] "V"  PT
 SG_ brickVoltage296_BMS14 m99 : 39|16@0+ (0.0001,0) [0|6.5] "V"  PT
 SG_ brickVoltage297_BMS14 m99 : 55|16@0+ (0.0001,0) [0|6.5] "V"  PT
 SG_ brickVoltage298_BMS14 m100 : 23|16@0+ (0.0001,0) [0|6.5] "V"  PT
 SG_ brickVoltage299_BMS14 m100 : 39|16@0+ (0.0001,0) [0|6.5] "V"  PT
 SG_ brickVoltage300_BMS14 m100 : 55|16@0+ (0.0001,0) [0|6.5] "V"  PT
 SG_ moduleTemperature33_BMS14 m33 : 15|8@0+ (1,-40) [-40|200] "C"  PT
 SG_ moduleTemperature34_BMS14 m34 : 15|8@0+ (1,-40) [-40|200] "C"  PT
 SG_ moduleTemperature35_BMS14 m35 : 15|8@0+ (1,-40) [-40|200] "C"  PT
 SG_ moduleTemperature36_BMS14 m36 : 15|8@0+ (1,-40) [-40|200] "C"  PT
 SG_ moduleTemperature37_BMS14 m37 : 15|8@0+ (1,-40) [-40|200] "C"  PT
 SG_ moduleTemperature38_BMS14 m38 : 15|8@0+ (1,-40) [-40|200] "C"  PT
 SG_ moduleTemperature39_BMS14 m39 : 15|8@0+ (1,-40) [-40|200] "C"  PT
 SG_ moduleTemperature40_BMS14 m40 : 15|8@0+ (1,-40) [-40|200] "C"  PT
 SG_ moduleTemperature41_BMS14 m41 : 15|8@0+ (1,-40) [-40|200] "C"  PT
 SG_ moduleTemperature42_BMS14 m42 : 15|8@0+ (1,-40) [-40|200] "C"  PT
 SG_ moduleTemperature43_BMS14 m43 : 15|8@0+ (1,-40) [-40|200] "C"  PT
 SG_ moduleTemperature44_BMS14 m44 : 15|8@0+ (1,-40) [-40|200] "C"  PT
 SG_ moduleTemperature45_BMS14 m45 : 15|8@0+ (1,-40) [-40|200] "C"  PT
 SG_ moduleTemperature46_BMS14 m46 : 15|8@0+ (1,-40) [-40|200] "C"  PT
 SG_ moduleTemperature47_BMS14 m47 : 15|8@0+ (1,-40) [-40|200] "C"  PT
 SG_ moduleTemperature48_BMS14 m48 : 15|8@0+ (1,-40) [-40|200] "C"  PT
 SG_ moduleTemperature49_BMS14 m49 : 15|8@0+ (1,-40) [-40|200] "C"  PT
 SG_ moduleTemperature50_BMS14 m50 : 15|8@0+ (1,-40) [-40|200] "C"  PT
 SG_ moduleTemperature51_BMS14 m51 : 15|8@0+ (1,-40) [-40|200] "C"  PT
 SG_ moduleTemperature52_BMS14 m52 : 15|8@0+ (1,-40) [-40|200] "C"  PT
 SG_ moduleTemperature53_BMS14 m53 : 15|8@0+ (1,-40) [-40|200] "C"  PT
 SG_ moduleTemperature54_BMS14 m54 : 15|8@0+ (1,-40) [-40|200] "C"  PT
 SG_ moduleTemperature55_BMS14 m55 : 15|8@0+ (1,-40) [-40|200] "C"  PT
 SG_ moduleTemperature56_BMS14 m56 : 15|8@0+ (1,-40) [-40|200] "C"  PT
 SG_ moduleTemperature57_BMS14 m57 : 15|8@0+ (1,-40) [-40|200] "C"  PT
 SG_ moduleTemperature58_BMS14 m58 : 15|8@0+ (1,-40) [-40|200] "C"  PT
 SG_ moduleTemperature59_BMS14 m59 : 15|8@0+ (1,-40) [-40|200] "C"  PT
 SG_ moduleTemperature60_BMS14 m60 : 15|8@0+ (1,-40) [-40|200] "C"  PT
 SG_ moduleTemperature61_BMS14 m61 : 15|8@0+ (1,-40) [-40|200] "C"  PT
 SG_ moduleTemperature62_BMS14 m62 : 15|8@0+ (1,-40) [-40|200] "C"  PT
 SG_ moduleTemperature63_BMS14 m63 : 15|8@0+ (1,-40) [-40|200] "C"  PT
 SG_ moduleTemperature64_BMS14 m64 : 15|8@0+ (1,-40) [-40|200] "C"  PT
 SG_ moduleTemperature65_BMS14 m65 : 15|8@0+ (1,-40) [-40|200] "C"  PT
 SG_ moduleTemperature66_BMS14 m66 : 15|8@0+ (1,-40) [-40|200] "C"  PT
 SG_ moduleTemperature67_BMS14 m67 : 15|8@0+ (1,-40) [-40|200] "C"  PT
 SG_ moduleTemperature68_BMS14 m68 : 15|8@0+ (1,-40) [-40|200] "C"  PT
 SG_ moduleTemperature69_BMS14 m69 : 15|8@0+ (1,-40) [-40|200] "C"  PT
 SG_ moduleTemperature70_BMS14 m70 : 15|8@0+ (1,-40) [-40|200] "C"  PT
 SG_ moduleTemperature71_BMS14 m71 : 15|8@0+ (1,-40) [-40|200] "C"  PT
 SG_ moduleTemperature72_BMS14 m72 : 15|8@0+ (1,-40) [-40|200] "C"  PT
 SG_ moduleTemperature73_BMS14 m73 : 15|8@0+ (1,-40) [-40|200] "C"  PT
 SG_ moduleTemperature74_BMS14 m74 : 15|8@0+ (1,-40) [-40|200] "C"  PT
 SG_ moduleTemperature75_BMS14 m75 : 15|8@0+ (1,-40) [-40|200] "C"  PT
 SG_ moduleTemperature76_BMS14 m76 : 15|8@0+ (1,-40) [-40|200] "C"  PT
 SG_ moduleTemperature77_BMS14 m77 : 15|8@0+ (1,-40) [-40|200] "C"  PT
 SG_ moduleTemperature78_BMS14 m78 : 15|8@0+ (1,-40) [-40|200] "C"  PT
 SG_ moduleTemperature79_BMS14 m79 : 15|8@0+ (1,-40) [-40|200] "C"  PT
 SG_ moduleTemperature80_BMS14 m80 : 15|8@0+ (1,-40) [-40|200] "C"  PT
 SG_ moduleTemperature81_BMS14 m81 : 15|8@0+ (1,-40) [-40|200] "C"  PT
 SG_ moduleTemperature82_BMS14 m82 : 15|8@0+ (1,-40) [-40|200] "C"  PT
 SG_ moduleTemperature83_BMS14 m83 : 15|8@0+ (1,-40) [-40|200] "C"  PT
 SG_ moduleTemperature84_BMS14 m84 : 15|8@0+ (1,-40) [-40|200] "C"  PT
 SG_ moduleTemperature85_BMS14 m85 : 15|8@0+ (1,-40) [-40|200] "C"  PT
 SG_ moduleTemperature86_BMS14 m86 : 15|8@0+ (1,-40) [-40|200] "C"  PT
 SG_ moduleTemperature87_BMS14 m87 : 15|8@0+ (1,-40) [-40|200] "C"  PT
 SG_ moduleTemperature88_BMS14 m88 : 15|8@0+ (1,-40) [-40|200] "C"  PT
 SG_ moduleTemperature89_BMS14 m89 : 15|8@0+ (1,-40) [-40|200] "C"  PT
 SG_ moduleTemperature90_BMS14 m90 : 15|8@0+ (1,-40) [-40|200] "C"  PT
 SG_ moduleTemperature91_BMS14 m91 : 15|8@0+ (1,-40) [-40|200] "C"  PT
 SG_ moduleTemperature92_BMS14 m92 : 15|8@0+ (1,-40) [-40|200] "C"  PT
 SG_ moduleTemperature93_BMS14 m93 : 15|8@0+ (1,-40) [-40|200] "C"  PT
 SG_ moduleTemperature94_BMS14 m94 : 15|8@0+ (1,-40) [-40|200] "C"  PT
 SG_ moduleTemperature95_BMS14 m95 : 15|8@0+ (1,-40) [-40|200] "C"  PT
 SG_ moduleTemperature96_BMS14 m96 : 15|8@0+ (1,-40) [-40|200] "C"  PT
 SG_ moduleTemperature97_BMS14 m97 : 15|8@0+ (1,-40) [-40|200] "C"  PT
 SG_ moduleTemperature98_BMS14 m98 : 15|8@0+ (1,-40) [-40|200] "C"  PT
 SG_ moduleTemperature99_BMS14 m99 : 15|8@0+ (1,-40) [-40|200] "C"  PT
 SG_ moduleTemperature100_BMS14 m100 : 15|8@0+ (1,-40) [-40|200] "C"  PT
 SG_ moduleTemperature101_BMS14 m101 : 15|8@0+ (1,-40) [-40|200] "C"  PT
 SG_ moduleTemperature102_BMS14 m102 : 15|8@0+ (1,-40) [-40|200] "C"  PT
 SG_ moduleTemperature103_BMS14 m103 : 15|8@0+ (1,-40) [-40|200] "C"  PT
 SG_ moduleTemperature104_BMS14 m104 : 15|8@0+ (1,-40) [-40|200] "C"  PT
 SG_ moduleTemperature105_BMS14 m105 : 15|8@0+ (1,-40) [-40|200] "C"  PT
 SG_ moduleTemperature106_BMS14 m106 : 15|8@0+ (1,-40) [-40|200] "C"  PT
 SG_ moduleTemperature107_BMS14 m107 : 15|8@0+ (1,-40) [-40|200] "C"  PT
 SG_ moduleTemperature108_BMS14 m108 : 15|8@0+ (1,-40) [-40|200] "C"  PT
 SG_ moduleTemperature109_BMS14 m109 : 15|8@0+ (1,-40) [-40|200] "C"  PT
 SG_ moduleTemperature110_BMS14 m110 : 15|8@0+ (1,-40) [-40|200] "C"  PT
 SG_ moduleTemperature111_BMS14 m111 : 15|8@0+ (1,-40) [-40|200] "C"  PT
 SG_ moduleTemperature112_BMS14 m112 : 15|8@0+ (1,-40) [-40|200] "C"  PT
 SG_ moduleTemperature113_BMS14 m113 : 15|8@0+ (1,-40) [-40|200] "C"  PT
 SG_ moduleTemperature114_BMS14 m114 : 15|8@0+ (1,-40) [-40|200] "C"  PT
 SG_ moduleTemperature115_BMS14 m115 : 15|8@0+ (1,-40) [-40|200] "C"  PT
 SG_ moduleTemperature116_BMS14 m116 : 15|8@0+ (1,-40) [-40|200] "C"  PT
 SG_ moduleTemperature117_BMS14 m117 : 15|8@0+ (1,-40) [-40|200] "C"  PT
 SG_ moduleTemperature118_BMS14 m118 : 15|8@0+ (1,-40) [-40|200] "C"  PT
 SG_ moduleTemperature119_BMS14 m119 : 15|8@0+ (1,-40) [-40|200] "C"  PT
 SG_ moduleTemperature120_BMS14 m120 : 15|8@0+ (1,-40) [-40|200] "C"  PT
 SG_ moduleTemperature121_BMS14 m121 : 15|8@0+ (1,-40) [-40|200] "C"  PT
 SG_ moduleTemperature122_BMS14 m122 : 15|8@0+ (1,-40) [-40|200] "C"  PT
 SG_ moduleTemperature123_BMS14 m123 : 15|8@0+ (1,-40) [-40|200] "C"  PT
 SG_ moduleTemperature124_BMS14 m124 : 15|8@0+ (1,-40) [-40|200] "C"  PT
 SG_ moduleTemperature125_BMS14 m125 : 15|8@0+ (1,-40) [-40|200] "C"  PT
 SG_ moduleTemperature126_BMS14 m126 : 15|8@0+ (1,-40) [-40|200] "C"  PT
 SG_ moduleTemperature127_BMS14 m127 : 15|8@0+ (1,-40) [-40|200] "C"  PT
 SG_ moduleTemperature128_BMS14 m128 : 15|8@0+ (1,-40) [-40|200] "C"  PT
 SG_ moduleTemperature129_BMS14 m129 : 15|8@0+ (1,-40) [-40|200] "C"  PT
 SG_ moduleTemperature130_BMS14 m130 : 15|8@0+ (1,-40) [-40|200] "C"  PT
 SG_ moduleTemperature131_BMS14 m131 : 15|8@0+ (1,-40) [-40|200] "C"  PT
 SG_ moduleTemperature132_BMS14 m132 : 15|8@0+ (1,-40) [-40|200] "C"  PT
 SG_ moduleTemperature133_BMS14 m133 : 15|8@0+ (1,-40) [-40|200] "C"  PT
 SG_ moduleTemperature134_BMS14 m134 : 15|8@0+ (1,-40) [-40|200] "C"  PT
 SG_ moduleTemperature135_BMS14 m135 : 15|8@0+ (1,-40) [-40|200] "C"  PT
 SG_ moduleTemperature136_BMS14 m136 : 15|8@0+ (1,-40) [-40|200] "C"  PT
 SG_ moduleTemperature137_BMS14 m137 : 15|8@0+ (1,-40) [-40|200] "C"  PT
 SG_ moduleTemperature138_BMS14 m138 : 15|8@0+ (1,-40) [-40|200] "C"  PT
 SG_ moduleTemperature139_BMS14 m139 : 15|8@0+ (1,-40) [-40|200] "C"  PT
 SG_ moduleTemperature140_BMS14 m140 : 15|8@0+ (1,-40) [-40|200] "C"  PT
 SG_ moduleTemperature141_BMS14 m141 : 15|8@0+ (1,-40) [-40|200] "C"  PT
 SG_ moduleTemperature142_BMS14 m142 : 15|8@0+ (1,-40) [-40|200] "C"  PT
 SG_ moduleTemperature143_BMS14 m143 : 15|8@0+ (1,-40) [-40|200] "C"  PT
 SG_ moduleTemperature144_BMS14 m144 : 15|8@0+ (1,-40) [-40|200] "C"  PT
 SG_ moduleTemperature145_BMS14 m145 : 15|8@0+ (1,-40) [-40|200] "C"  PT
 SG_ moduleTemperature146_BMS14 m146 : 15|8@0+ (1,-40) [-40|200] "C"  PT
 SG_ moduleTemperature147_BMS14 m147 : 15|8@0+ (1,-40) [-40|200] "C"  PT
 SG_ moduleTemperature148_BMS14 m148 : 15|8@0+ (1,-40) [-40|200] "C"  PT
 SG_ moduleTemperature149_BMS14 m149 : 15|8@0+ (1,-40) [-40|200] "C"  PT
 SG_ moduleTemperature150_BMS14 m150 : 15|8@0+ (1,-40) [-40|200] "C"  PT
 SG_ moduleTemperature151_BMS14 m151 : 15|8@0+ (1,-40) [-40|200] "C"  PT
 SG_ moduleTemperature152_BMS14 m152 : 15|8@0+ (1,-40) [-40|200] "C"  PT
 SG_ moduleTemperature153_BMS14 m153 : 15|8@0+ (1,-40) [-40|200] "C"  PT
 SG_ moduleTemperature154_BMS14 m154 : 15|8@0+ (1,-40) [-40|200] "C"  PT
 SG_ moduleTemperature155_BMS14 m155 : 15|8@0+ (1,-40) [-40|200] "C"  PT
 SG_ moduleTemperature156_BMS14 m156 : 15|8@0+ (1,-40) [-40|200] "C"  PT
 SG_ moduleTemperature157_BMS14 m157 : 15|8@0+ (1,-40) [-40|200] "C"  PT
 SG_ moduleTemperature158_BMS14 m158 : 15|8@0+ (1,-40) [-40|200] "C"  PT
 SG_ moduleTemperature159_BMS14 m159 : 15|8@0+ (1,-40) [-40|200] "C"  PT
 SG_ moduleTemperature160_BMS14 m160 : 15|8@0+ (1,-40) [-40|200] "C"  PT
 SG_ moduleTemperature161_BMS14 m161 : 15|8@0+ (1,-40) [-40|200] "C"  PT
 SG_ moduleTemperature162_BMS14 m162 : 15|8@0+ (1,-40) [-40|200] "C"  PT
 SG_ moduleTemperature163_BMS14 m163 : 15|8@0+ (1,-40) [-40|200] "C"  PT
 SG_ moduleTemperature164_BMS14 m164 : 15|8@0+ (1,-40) [-40|200] "C"  PT
 SG_ moduleTemperature165_BMS14 m165 : 15|8@0+ (1,-40) [-40|200] "C"  PT
 SG_ moduleTemperature166_BMS14 m166 : 15|8@0+ (1,-40) [-40|200] "C"  PT
 SG_ moduleTemperature167_BMS14 m167 : 15|8@0+ (1,-40) [-40|200] "C"  PT
 SG_ moduleTemperature168_BMS14 m168 : 15|8@0+ (1,-40) [-40|200] "C"  PT
 SG_ moduleTemperature169_BMS14 m169 : 15|8@0+ (1,-40) [-40|200] "C"  PT
 SG_ moduleTemperature170_BMS14 m170 : 15|8@0+ (1,-40) [-40|200] "C"  PT
 SG_ moduleTemperature171_BMS14 m171 : 15|8@0+ (1,-40) [-40|200] "C"  PT
 SG_ moduleTemperature172_BMS14 m172 : 15|8@0+ (1,-40) [-40|200] "C"  PT
 SG_ moduleTemperature173_BMS14 m173 : 15|8@0+ (1,-40) [-40|200] "C"  PT
 SG_ moduleTemperature174_BMS14 m174 : 15|8@0+ (1,-40) [-40|200] "C"  PT
 SG_ moduleTemperature175_BMS14 m175 : 15|8@0+ (1,-40) [-40|200] "C"  PT
 SG_ moduleTemperature176_BMS14 m176 : 15|8@0+ (1,-40) [-40|200] "C"  PT
 SG_ moduleTemperature177_BMS14 m177 : 15|8@0+ (1,-40) [-40|200] "C"  PT
 SG_ moduleTemperature178_BMS14 m178 : 15|8@0+ (1,-40) [-40|200] "C"  PT
 SG_ moduleTemperature179_BMS14 m179 : 15|8@0+ (1,-40) [-40|200] "C"  PT
 SG_ moduleTemperature180_BMS14 m180 : 15|8@0+ (1,-40) [-40|200] "C"  PT
 SG_ moduleTemperature181_BMS14 m181 : 15|8@0+ (1,-40) [-40|200] "C"  PT
 SG_ moduleTemperature182_BMS14 m182 : 15|8@0+ (1,-40) [-40|200] "C"  PT
 SG_ moduleTemperature183_BMS14 m183 : 15|8@0+ (1,-40) [-40|200] "C"  PT
 SG_ moduleTemperature184_BMS14 m184 : 15|8@0+ (1,-40) [-40|200] "C"  PT
 SG_ moduleTemperature185_BMS14 m185 : 15|8@0+ (1,-40) [-40|200] "C"  PT
 SG_ moduleTemperature186_BMS14 m186 : 15|8@0+ (1,-40) [-40|200] "C"  PT
 SG_ moduleTemperature187_BMS14 m187 : 15|8@0+ (1,-40) [-40|200] "C"  PT
 SG_ moduleTemperature188_BMS14 m188 : 15|8@0+ (1,-40) [-40|200] "C"  PT
 SG_ moduleTemperature189_BMS14 m189 : 15|8@0+ (1,-40) [-40|200] "C"  PT
 SG_ moduleTemperature190_BMS14 m190 : 15|8@0+ (1,-40) [-40|200] "C"  PT
 SG_ moduleTemperature191_BMS14 m191 : 15|8@0+ (1,-40) [-40|200] "C"  PT
 SG_ moduleTemperature192_BMS14 m192 : 15|8@0+ (1,-40) [-40|200] "C"  PT

BA_DEF_ SG_  "GenSigSendType" ENUM  "Cyclic","OnWrite","OnWriteWithRepetition","OnChange","OnChangeWithRepetition","IfActive","IfActiveWithRepetition","NoSigSendType";
BA_DEF_ BO_  "GenMsgCycleTime" INT 0 0;
BA_DEF_ BO_  "GenMsgSendType" ENUM  "Cyclic","not_used","not_used","not_used","not_used","Cyclic","not_used","IfActive","NoMsgSendType";
BA_DEF_DEF_  "GenSigSendType" "Cyclic";
BA_DEF_DEF_  "GenMsgCycleTime" 0;
BA_DEF_DEF_  "GenMsgSendType" "NoMsgSendType";
BA_ "GenMsgCycleTime" BO_ 1037 1000;
BA_ "GenMsgCycleTime" BO_ 1101 1000;
BA_ "GenMsgCycleTime" BO_ 1165 1000;
BA_ "GenMsgCycleTime" BO_ 1229 1000;
BA_ "GenMsgCycleTime" BO_ 1293 1000;
BA_ "GenMsgCycleTime" BO_ 1357 1000;
BA_ "GenMsgCycleTime" BO_ 1421 1000;
BA_ "GenMsgCycleTime" BO_ 1485 1000;
BA_ "GenMsgCycleTime" BO_ 1613 100;
BA_ "GenMsgCycleTime" BO_ 1677 10;
BA_ "GenMsgCycleTime" BO_ 1933 100;
BA_ "GenMsgCycleTime" BO_ 1997 100;
VAL_ 1549 DEMEventMultiplexor_BMS14 319 "DEM319_HV_DISABLE_DURING_S" 318 "DEM318_HV_ENABLE_IMPLAUSIB" 317 "DEM317_STRING_SUSPECT_OPEN" 316 "DEM316_UNEXPCTD_BMS_ON_CAN" 315 "DEM315_HV_WITHSTAND_TESTS_" 314 "DEM314_OBC_PILOT_ERROR" 313 "DEM313_OBC_PILOT_HIGH" 312 "DEM312_OBC_PROXIMITY_ERROR" 311 "DEM311_CTRS_END_OF_LIFE_WA" 310 "DEM310_BMSMIA_STRNGMSTR_AL" 309 "DEM309_VOLTAGE_BRICKOV_WAR" 308 "DEM308_PRESSURE_FLT" 307 "DEM307_PRESSURE_MIA" 306 "DEM306_SW_VERSION_MISMATCH" 305 "DEM305_MODULET_OVERTEMP_WA" 304 "DEM304_PCHG_OPENCIRCUIT_IN" 303 "DEM303_MODULET_UNDERTEMP_W" 302 "DEM302_MODULET_UT" 301 "DEM301_FUSI_LOCK" 300 "DEM300_DEBUG_SM_DISABLED" 299 "DEM299_5V_SENSOR_SUPPLY_OU" 298 "DEM298_IMPL_DRIVE_REQUEST" 297 "DEM297_PCHG2_OPENCIRCUIT" 296 "DEM296_CTRSAUX_IMPLAUSIBLE" 295 "DEM295_CTRSAUX_LINKV_UNSAF" 294 "DEM294_CANRX_PT_EMERGENCY" 293 "DEM293_SBC_LDT_IMPLAUSIBLE" 292 "DEM292_NUM_EXPECTED_STRING" 291 "DEM291_NUM_EXPECTED_STRING" 290 "DEM290_CMB_ONBOARD_DEFECT" 289 "DEM289_TEMP_STATE_LATCHED" 288 "DEM288_CURR_STATE_LATCHED" 1 "DEM001_POWERUP" 2 "DEM002_VOLTAGE_BRICK_OV" 3 "DEM003_VOLTAGE_BRICK_UV" 4 "DEM004_VOLTAGE_BRICK_SNA" 5 "DEM005_VOLTAGE_BRICK_IMBAL" 6 "DEM006_VOLTAGE_CAPCY_IMBAL" 7 "DEM007_MODULET_HIGH_DELTA" 8 "DEM008_VOLTAGE_PACK_UV" 9 "DEM009_VOLTAGE_PACK_OV" 10 "DEM010_VOLTAGE_PACK_PLAUSI" 11 "DEM011_VOLTAGE_PCKLINK_MIS" 12 "DEM012_VOLTAGE_BMS_SUPPLY" 13 "DEM013_ADC_ERROR" 14 "DEM014_MODULET_OT" 15 "DEM015_MODULET_SNA" 16 "DEM016_MODULET_LIMPHOME" 17 "DEM017_COOLING_SYS_LHOME" 18 "DEM018_HVIL_LIMPHOME" 19 "DEM019_HVIL_ESS_INHIBIT" 20 "DEM020_MODULET_CHANGE" 21 "DEM021_LG_MAVD_FAULT" 22 "DEM022_LG_RDV_FAULT" 23 "DEM023_BMS_ONBOARDT_SNA" 24 "DEM024_BMS_ONBOARDRH_OH" 25 "DEM025_BMS_ONBOARDRH_SNA" 26 "DEM026_CURRENT_OVERCHARGE" 27 "DEM027_CURRENT_OVERDISCHGE" 28 "DEM028_CURRENT_INVALID" 29 "DEM029_CURRENT_SHORTCIRCT" 30 "DEM030_CRASH_CAN_LATCH" 31 "DEM031_EEPROM_FAIL" 32 "DEM032_PCHG_PACKS_CONNECT" 33 "DEM033_PCHG_ILLEGAL_PRCHG" 34 "DEM034_PCHG_RELAY_FAIL" 35 "DEM035_PCHG_NEG_WELD" 36 "DEM036_PCHG_NEG_PULLIN" 37 "DEM037_PCHG_SHORTCIRCUIT" 38 "DEM038_PCHG_OPENCIRCUIT" 39 "DEM039_PCHG_TIMEOUT" 40 "DEM040_PCHG_FAILED" 41 "DEM041_HVIL_SHUTDOWN" 42 "DEM042_PCHG_POS_WELD" 43 "DEM043_HV_LOCK_TRANSPORT" 44 "DEM044_CTRS_END_OF_LIFE" 45 "DEM045_CTRS_CTRPWRV_HI" 46 "DEM046_CTRS_COILCURR_LOW" 47 "DEM047_CTRS_COILCURR_HIGH" 48 "DEM048_CTRS_CTRPWRV_LOW" 49 "DEM049_CHGE_ILLEGAL_DISCHG" 50 "DEM050_STARTUP_CONDITIONS" 51 "DEM051_VOLTAGE_BMS_SUPPLYH" 52 "DEM052_SAFETYSPI_FAIL" 53 "DEM053_WATCHDOG_ERRORPIN" 54 "DEM054_SAFESTATE_TRIGGERED" 55 "DEM055_DEBUG_CMND_ACTIVE" 56 "DEM056_CRASH_CAN" 57 "DEM057_ISO_EXT_STRAT_4" 58 "DEM058_ISO_EXT_RES_ERR" 59 "DEM059_ISO_EXT_RES_WARN" 60 "DEM060_ISO_INT_RES_ERR" 61 "DEM061_ISO_INT_RES_WARN" 62 "DEM062_EMERGENCY_OPERATION" 63 "DEM063_ENDOFDRIVE" 64 "DEM064_STRINGV_IMBALANCE" 65 "DEM065_STRING_FAULT" 66 "DEM066_ESS_FAULT" 67 "DEM067_ISO_EXT_STRAT_3" 68 "DEM068_MODULE_COUNT_INVALI" 69 "DEM069_PT_MIA" 70 "DEM070_BMSMIA_STRNGMSTR_01" 71 "DEM071_BMSMIA_STRNGMSTR_05" 72 "DEM072_BMSMIA_STRNGMSTR_09" 73 "DEM073_BMSMIA_STRNGMSTR_13" 74 "DEM074_BMSMIA_STRNGMSTR_17" 75 "DEM075_BMSMIA_STRNGMSTR_21" 76 "DEM076_BMSMIA_STRNGMSTR_25" 77 "DEM077_BMSMIA_STRNGMSTR_29" 78 "DEM078_BMSMIA_STRNGMSTR_33" 79 "DEM079_BMSMIA_STRNGMSTR_37" 80 "DEM080_BMSMIA_STRNGMSTR_41" 81 "DEM081_BMSMIA_STRNGMSTR_45" 82 "DEM082_BMSMIA_STRNGMSTR_49" 83 "DEM083_BMSMIA_STRNGMSTR_53" 84 "DEM084_BMSMIA_STRNGMSTR_57" 85 "DEM085_BMSMIA_STRNGMSTR_61" 86 "DEM086_ESSCURRENT_SHORT" 87 "DEM087_PT_MIA_SHUTDOWN" 88 "DEM088_OUTLET_NTC_HI" 89 "DEM089_OUTLET_NTC_LO" 90 "DEM090_BMSMIA_ESSMASTER" 91 "DEM091_PCHG_RES_OVERHEAT" 92 "DEM092_BMSMIA_STRNGSLAVE_0" 93 "DEM093_BMSMIA_STRNGSLAVE_1" 94 "DEM094_BMSMIA_STRNGSLAVE_2" 95 "DEM095_BMSMIA_STRNGSLAVE_3" 96 "DEM096_SC_STATE_SELFTEST" 97 "DEM097_SC_STATE_TEMP" 98 "DEM098_SC_STATE_VOLTAGE" 99 "DEM099_SC_STATE_HVIL" 100 "DEM100_SC_STATE_CONTACTORS" 101 "DEM101_SC_STATE_CURRENT" 102 "DEM102_SC_STATE_CANRX" 103 "DEM103_SC_STATE_CRASH" 104 "DEM104_SC_STATE_CCTRL" 105 "DEM105_SC_STATE_CANTX" 106 "DEM106_SC_STATE_THERMALEVT" 107 "DEM107_SC_STATE_COOLANT" 108 "DEM108_SC_SELFTEST_SFTY_UC" 109 "DEM109_SC_TEMP_HIGH" 110 "DEM110_SC_TEMP_NTC_OPEN" 111 "DEM111_SC_TEMP_NTC_SHORT" 112 "DEM112_CMB_DISCONNECTED" 113 "DEM113_CMB_DEFECT" 114 "DEM114_CMB_COMMERROR" 115 "DEM115_SC_CURR_HALL_PWR_LO" 116 "DEM116_SC_CURR_HALL_VHIGH" 117 "DEM117_SC_CURR_HALL_ADC" 118 "DEM118_SC_CURR_HALL_VLOW" 119 "DEM119_SC_CURR_ISENSE_PWR" 120 "DEM120_SC_CURR_ISENSE1_MIA" 121 "DEM121_SC_CURR_ISENSE2_MIA" 122 "DEM122_SC_CURR_ISENSE3_MIA" 123 "DEM123_SC_CURR_ISENSE4_MIA" 124 "DEM124_SC_CURR_ISENSE5_MIA" 125 "DEM125_SC_CURR_ISENSE1_FLT" 126 "DEM126_SC_CURR_ISENSE2_FLT" 127 "DEM127_SC_CURR_ISENSE3_FLT" 128 "DEM128_SC_CURR_ISENSE4_FLT" 129 "DEM129_SC_CURR_ISENSE5_FLT" 130 "DEM130_SC_CURR_OFFSET" 131 "DEM131_SC_CURR_PLAUSI" 132 "DEM132_SC_CURR_CHARGE_HIGH" 133 "DEM133_SC_CURR_DSCHAR_HIGH" 134 "DEM134_SC_V_CMB_SUMOFCELL" 135 "DEM135_SC_V_SENSE_OPENWIRE" 136 "DEM136_SC_V_CMB_DRV_FROZEN" 137 "DEM137_SC_V_PACK_PLAUSI" 138 "DEM138_SC_HVIL_HW_FLT" 139 "DEM139_SC_HVIL_OPEN" 140 "DEM140_SC_HVIL_TO_SUP" 141 "DEM141_SC_HVIL_TO_CHAS" 142 "DEM142_SC_HVIL_R_HIGH" 143 "DEM143_SC_HVIL_SHORT" 144 "DEM144_SC_CN_ISO_FAIL" 145 "DEM145_HVIL_SYS" 146 "DEM146_SC_CN_POS1_WELDED" 147 "DEM147_SC_CN_NEG1_WELDED" 148 "DEM148_SC_CN_POS2_WELDED" 149 "DEM149_SC_CN_NEG2_WELDED" 150 "DEM150_SC_CN_POS3_WELDED" 151 "DEM151_SC_CN_NEG3_WELDED" 152 "DEM152_SC_CN_HIGH_CY" 153 "DEM153_SC_CN_ISOANDPOTWELD" 154 "DEM154_SC_TEMP_PLAUSI" 155 "DEM155_SC_CURR_HALL_PWR_HI" 156 "DEM156_SC_PYRO_TRIGGERED" 157 "DEM157_SC_PYRO_OPEN" 158 "DEM158_AUX_CTRS_END_OF_LIF" 159 "DEM159_SC_CANRX_PT_MIA" 160 "DEM160_SC_CANRX_PT_CRCALIV" 161 "DEM161_SC_CANRX_LIN_SHUTDN" 162 "DEM162_SC_CANRX_LIN_MIA" 163 "DEM163_SC_CRASH1" 164 "DEM164_SC_CRASH2" 165 "DEM165_SC_CRASHCAN" 166 "DEM166_SC_CCTRL_SELFTEST" 167 "DEM167_SC_CCTRL_DRIVER_FAU" 168 "DEM168_SC_CCTRL_HISIDESTCL" 169 "DEM169_SC_CCTRL_HISIDESTOP" 170 "DEM170_SC_CCTRL_LOSIDESTCL" 171 "DEM171_SC_CCTRL_HVCNDITION" 172 "DEM172_SC_CCTRL_POS1_OPN" 173 "DEM173_SC_CCTRL_POS2_OPN" 174 "DEM174_SC_CCTRL_POS3_OPN" 175 "DEM175_SC_CCTRL_NEG1_OPN" 176 "DEM176_SC_CCTRL_NEG2_OPN" 177 "DEM177_SC_CCTRL_PRE2_OPN" 178 "DEM178_SC_CCTRL_PRE1_OPN" 179 "DEM179_SC_CCTRL_LOSIDESTOP" 180 "DEM180_SC_CCTRL_UNEXPECTED" 181 "DEM181_SC_V_OUT_OF_RANGE" 182 "DEM182_SC_V_LATCHED_UVOV" 183 "DEM183_ISO_EXT_STRAT_2" 184 "DEM184_SC_CANTX_CTRS" 185 "DEM185_SC_CANTX_HVIL" 186 "DEM186_SC_CANTX_ISOL" 187 "DEM187_SC_SBC_WATCHDOG" 188 "DEM188_SC_SBC_FAULT" 189 "DEM189_SC_WATCHDOG" 190 "DEM190_SC_SELFTEST_RAM" 191 "DEM191_SC_SELFTEST_FLASH" 192 "DEM192_CMB_ONBOARDRH_OH" 193 "DEM193_CMB_ONBOARDRH_SNA" 194 "DEM194_CMB_ONBOARDT_OT" 195 "DEM195_CMB_ONBOARDT_CHANGE" 196 "DEM196_PRESSURE_CHANGE" 197 "DEM197_PRESSURE_OVER" 198 "DEM198_PRESSURE_UNDER" 199 "DEM199_PRESSURE_INVALID" 200 "DEM200_THERMAL_EVENT" 201 "DEM201_CMB_ONBOARDT_SNA" 202 "DEM202_REPLACE_DESICCANT" 203 "DEM203_COOLANT_FLOOD_FAULT" 204 "DEM204_LOW_BRICKCAPACITY" 205 "DEM205_BMS_ONBOARDT_OT" 206 "DEM206_HUMIDITY_CHANGE" 207 "DEM207_ISENSE_SUPPLY_CURR" 208 "DEM208_SOC_LOW" 209 "DEM209_SOC_TOOLOW" 210 "DEM210_SOC_TOOHIGH" 211 "DEM211_BALANCING_REQUIRED" 212 "DEM212_DEEP_DISCHARGE" 213 "DEM213_CAN1_BUS_OFF" 214 "DEM214_CAN2_BUS_OFF" 215 "DEM215_CAN3_BUS_OFF" 216 "DEM216_OUTLET_NTC_RATNAL" 217 "DEM217_FUSE_PACK" 218 "DEM218_FUSE_B_OPEN" 219 "DEM219_FUSE_C_OPEN" 220 "DEM220_FUSE_D_OPEN" 221 "DEM221_FUSE_E_OPEN" 222 "DEM222_PUMP_DRY_RUN" 223 "DEM223_PUMP_PERFORMANCE" 224 "DEM224_PUMP_LIN_FAILURE" 225 "DEM225_PUMP_SUPPLY_VOLTAGE" 226 "DEM226_PUMP_RECOVERY_FAIL" 227 "DEM227_CTR_POS_OPENED" 228 "DEM228_CTR_NEG_OPENED" 229 "DEM229_STRSET_SLAVE1_FAULT" 230 "DEM230_STRSET_SLAVE2_FAULT" 231 "DEM231_CTRSAUX_CLFAIL_HVON" 232 "DEM232_CTRSAUX_CLFAIL_VDIF" 233 "DEM233_CTRSAUX_POS1_OPENED" 234 "DEM234_CTRSAUX_NEG1_OPENED" 235 "DEM235_CTRSAUX_POS1_WELDED" 236 "DEM236_CTRSAUX_NEG1_WELDED" 237 "DEM237_CTRSAUX_POS1_PULLIN" 238 "DEM238_CTRSAUX_NEG1_PULLIN" 239 "DEM239_INLET_NTC_RATNAL" 240 "DEM240_INLET_NTC_HI" 241 "DEM241_INLET_NTC_LO" 242 "DEM242_VOLTAGE_LINK2_RATNA" 243 "DEM243_VOLTAGE_LINK2_HI" 244 "DEM244_VOLTAGE_LINK2_LO" 245 "DEM245_CMB_ONBOARD_IMPOSSI" 246 "DEM246_VOLTAGE_LINK1_HI" 247 "DEM247_VOLTAGE_LINK1_LO" 248 "DEM248_NTC_SUPPLY_LO" 249 "DEM249_NTC_SUPPLY_HI" 250 "DEM250_VOLTAGE_LINK3_RATNA" 251 "DEM251_VOLTAGE_LINK3_HI" 252 "DEM252_VOLTAGE_LINK3_LO" 253 "DEM253_BALANCING_STUCK" 254 "DEM254_ARM_EXCEPTION" 255 "DEM255_ERROR_HOOKS" 256 "DEM256_XCP_CAL_CHANGE" 257 "DEM257_XCP_CAL_PERM_CHANGE" 258 "DEM258_TASK_TIME_OVERFLOW" 259 "DEM259_ISO_CIRCUIT" 260 "DEM260_COOLANT_MOIST_FAULT" 261 "DEM261_COOLANT_FLOOD_WARN" 262 "DEM262_COOLANT_MOIST_WARN" 263 "DEM263_MODULET_IMPLAUSIBLE" 264 "DEM264_REQUEST_ON_WITH_HV_" 265 "DEM265_CSERS_PCODE" 266 "DEM266_PRELIM_CNTR_CL_FAIL" 267 "DEM267_FLUIDLVL_LOW" 268 "DEM268_FLUIDLVL_FAILURE" 269 "DEM269_SC_COOLANT_CONTAM" 270 "DEM270_SC_COOLANT_MIA" 271 "DEM271_PRESSURE_VHI" 272 "DEM272_PRESSURE_VLO" 273 "DEM273_SC_COOLANT_FAIL" 274 "DEM274_CTRSAUX_POS2_OPENED" 275 "DEM275_CTRSAUX_POS3_OPENED" 276 "DEM276_CTRSAUX_POS2_WELDED" 277 "DEM277_CTRSAUX_POS3_WELDED" 278 "DEM278_CTRSAUX_POS2_PULLIN" 279 "DEM279_CTRSAUX_POS3_PULLIN" 280 "DEM280_CMB_HUMIDITY_TEMP_C" 281 "DEM281_THERMAL_EVENT_CMB_R" 282 "DEM282_CUS_BRICKOV" 283 "DEM283_CUS_BRICKUV" 284 "DEM284_CUS_OVERCHRG" 285 "DEM285_CUS_OVERDCHRG" 286 "DEM286_CUS_CURRENT_CHG" 287 "DEM287_CUS_CURRENT_DCHG" ;
VAL_ 1037 DEM001_POWERUP_BMS14 3 "DEM_INVALID" 2 "DEM_FAILED" 1 "DEM_PASSED" 0 "DEM_NOTTESTED" ;
VAL_ 1037 DEM002_VOLTAGE_BRICK_OV_BMS14 3 "DEM_INVALID" 2 "DEM_FAILED" 1 "DEM_PASSED" 0 "DEM_NOTTESTED" ;
VAL_ 1037 DEM003_VOLTAGE_BRICK_UV_BMS14 3 "DEM_INVALID" 2 "DEM_FAILED" 1 "DEM_PASSED" 0 "DEM_NOTTESTED" ;
VAL_ 1037 DEM004_VOLTAGE_BRICK_SNA_BMS14 3 "DEM_INVALID" 2 "DEM_FAILED" 1 "DEM_PASSED" 0 "DEM_NOTTESTED" ;
VAL_ 1037 DEM005_VOLTAGE_BRICK_IMBAL_BMS14 3 "DEM_INVALID" 2 "DEM_FAILED" 1 "DEM_PASSED" 0 "DEM_NOTTESTED" ;
VAL_ 1037 DEM006_VOLTAGE_CAPCY_IMBAL_BMS14 3 "DEM_INVALID" 2 "DEM_FAILED" 1 "DEM_PASSED" 0 "DEM_NOTTESTED" ;
VAL_ 1037 DEM007_MODULET_HIGH_DELTA_BMS14 3 "DEM_INVALID" 2 "DEM_FAILED" 1 "DEM_PASSED" 0 "DEM_NOTTESTED" ;
VAL_ 1037 DEM008_VOLTAGE_PACK_UV_BMS14 3 "DEM_INVALID" 2 "DEM_FAILED" 1 "DEM_PASSED" 0 "DEM_NOTTESTED" ;
VAL_ 1037 DEM009_VOLTAGE_PACK_OV_BMS14 3 "DEM_INVALID" 2 "DEM_FAILED" 1 "DEM_PASSED" 0 "DEM_NOTTESTED" ;
VAL_ 1037 DEM010_VOLTAGE_PACK_PLAUSI_BMS14 3 "DEM_INVALID" 2 "DEM_FAILED" 1 "DEM_PASSED" 0 "DEM_NOTTESTED" ;
VAL_ 1037 DEM011_VOLTAGE_PCKLINK_MIS_BMS14 3 "DEM_INVALID" 2 "DEM_FAILED" 1 "DEM_PASSED" 0 "DEM_NOTTESTED" ;
VAL_ 1037 DEM012_VOLTAGE_BMS_SUPPLY_BMS14 3 "DEM_INVALID" 2 "DEM_FAILED" 1 "DEM_PASSED" 0 "DEM_NOTTESTED" ;
VAL_ 1037 DEM013_ADC_ERROR_BMS14 3 "DEM_INVALID" 2 "DEM_FAILED" 1 "DEM_PASSED" 0 "DEM_NOTTESTED" ;
VAL_ 1037 DEM014_MODULET_OT_BMS14 3 "DEM_INVALID" 2 "DEM_FAILED" 1 "DEM_PASSED" 0 "DEM_NOTTESTED" ;
VAL_ 1037 DEM015_MODULET_SNA_BMS14 3 "DEM_INVALID" 2 "DEM_FAILED" 1 "DEM_PASSED" 0 "DEM_NOTTESTED" ;
VAL_ 1037 DEM016_MODULET_LIMPHOME_BMS14 3 "DEM_INVALID" 2 "DEM_FAILED" 1 "DEM_PASSED" 0 "DEM_NOTTESTED" ;
VAL_ 1037 DEM017_COOLING_SYS_LHOME_BMS14 3 "DEM_INVALID" 2 "DEM_FAILED" 1 "DEM_PASSED" 0 "DEM_NOTTESTED" ;
VAL_ 1037 DEM018_HVIL_LIMPHOME_BMS14 3 "DEM_INVALID" 2 "DEM_FAILED" 1 "DEM_PASSED" 0 "DEM_NOTTESTED" ;
VAL_ 1037 DEM019_HVIL_ESS_INHIBIT_BMS14 3 "DEM_INVALID" 2 "DEM_FAILED" 1 "DEM_PASSED" 0 "DEM_NOTTESTED" ;
VAL_ 1037 DEM020_MODULET_CHANGE_BMS14 3 "DEM_INVALID" 2 "DEM_FAILED" 1 "DEM_PASSED" 0 "DEM_NOTTESTED" ;
VAL_ 1037 DEM021_LG_MAVD_FAULT_BMS14 3 "DEM_INVALID" 2 "DEM_FAILED" 1 "DEM_PASSED" 0 "DEM_NOTTESTED" ;
VAL_ 1037 DEM022_LG_RDV_FAULT_BMS14 3 "DEM_INVALID" 2 "DEM_FAILED" 1 "DEM_PASSED" 0 "DEM_NOTTESTED" ;
VAL_ 1037 DEM023_BMS_ONBOARDT_SNA_BMS14 3 "DEM_INVALID" 2 "DEM_FAILED" 1 "DEM_PASSED" 0 "DEM_NOTTESTED" ;
VAL_ 1037 DEM024_BMS_ONBOARDRH_OH_BMS14 3 "DEM_INVALID" 2 "DEM_FAILED" 1 "DEM_PASSED" 0 "DEM_NOTTESTED" ;
VAL_ 1037 DEM025_BMS_ONBOARDRH_SNA_BMS14 3 "DEM_INVALID" 2 "DEM_FAILED" 1 "DEM_PASSED" 0 "DEM_NOTTESTED" ;
VAL_ 1037 DEM026_CURRENT_OVERCHARGE_BMS14 3 "DEM_INVALID" 2 "DEM_FAILED" 1 "DEM_PASSED" 0 "DEM_NOTTESTED" ;
VAL_ 1037 DEM027_CURRENT_OVERDISCHGE_BMS14 3 "DEM_INVALID" 2 "DEM_FAILED" 1 "DEM_PASSED" 0 "DEM_NOTTESTED" ;
VAL_ 1037 DEM028_CURRENT_INVALID_BMS14 3 "DEM_INVALID" 2 "DEM_FAILED" 1 "DEM_PASSED" 0 "DEM_NOTTESTED" ;
VAL_ 1037 DEM029_CURRENT_SHORTCIRCT_BMS14 3 "DEM_INVALID" 2 "DEM_FAILED" 1 "DEM_PASSED" 0 "DEM_NOTTESTED" ;
VAL_ 1037 DEM030_CRASH_CAN_LATCH_BMS14 3 "DEM_INVALID" 2 "DEM_FAILED" 1 "DEM_PASSED" 0 "DEM_NOTTESTED" ;
VAL_ 1037 DEM031_EEPROM_FAIL_BMS14 3 "DEM_INVALID" 2 "DEM_FAILED" 1 "DEM_PASSED" 0 "DEM_NOTTESTED" ;
VAL_ 1101 DEM032_PCHG_PACKS_CONNECT_BMS14 3 "DEM_INVALID" 2 "DEM_FAILED" 1 "DEM_PASSED" 0 "DEM_NOTTESTED" ;
VAL_ 1101 DEM033_PCHG_ILLEGAL_PRCHG_BMS14 3 "DEM_INVALID" 2 "DEM_FAILED" 1 "DEM_PASSED" 0 "DEM_NOTTESTED" ;
VAL_ 1101 DEM034_PCHG_RELAY_FAIL_BMS14 3 "DEM_INVALID" 2 "DEM_FAILED" 1 "DEM_PASSED" 0 "DEM_NOTTESTED" ;
VAL_ 1101 DEM035_PCHG_NEG_WELD_BMS14 3 "DEM_INVALID" 2 "DEM_FAILED" 1 "DEM_PASSED" 0 "DEM_NOTTESTED" ;
VAL_ 1101 DEM036_PCHG_NEG_PULLIN_BMS14 3 "DEM_INVALID" 2 "DEM_FAILED" 1 "DEM_PASSED" 0 "DEM_NOTTESTED" ;
VAL_ 1101 DEM037_PCHG_SHORTCIRCUIT_BMS14 3 "DEM_INVALID" 2 "DEM_FAILED" 1 "DEM_PASSED" 0 "DEM_NOTTESTED" ;
VAL_ 1101 DEM038_PCHG_OPENCIRCUIT_BMS14 3 "DEM_INVALID" 2 "DEM_FAILED" 1 "DEM_PASSED" 0 "DEM_NOTTESTED" ;
VAL_ 1101 DEM039_PCHG_TIMEOUT_BMS14 3 "DEM_INVALID" 2 "DEM_FAILED" 1 "DEM_PASSED" 0 "DEM_NOTTESTED" ;
VAL_ 1101 DEM040_PCHG_FAILED_BMS14 3 "DEM_INVALID" 2 "DEM_FAILED" 1 "DEM_PASSED" 0 "DEM_NOTTESTED" ;
VAL_ 1101 DEM041_HVIL_SHUTDOWN_BMS14 3 "DEM_INVALID" 2 "DEM_FAILED" 1 "DEM_PASSED" 0 "DEM_NOTTESTED" ;
VAL_ 1101 DEM042_PCHG_POS_WELD_BMS14 3 "DEM_INVALID" 2 "DEM_FAILED" 1 "DEM_PASSED" 0 "DEM_NOTTESTED" ;
VAL_ 1101 DEM043_HV_LOCK_TRANSPORT_BMS14 3 "DEM_INVALID" 2 "DEM_FAILED" 1 "DEM_PASSED" 0 "DEM_NOTTESTED" ;
VAL_ 1101 DEM044_CTRS_END_OF_LIFE_BMS14 3 "DEM_INVALID" 2 "DEM_FAILED" 1 "DEM_PASSED" 0 "DEM_NOTTESTED" ;
VAL_ 1101 DEM045_CTRS_CTRPWRV_HI_BMS14 3 "DEM_INVALID" 2 "DEM_FAILED" 1 "DEM_PASSED" 0 "DEM_NOTTESTED" ;
VAL_ 1101 DEM046_CTRS_COILCURR_LOW_BMS14 3 "DEM_INVALID" 2 "DEM_FAILED" 1 "DEM_PASSED" 0 "DEM_NOTTESTED" ;
VAL_ 1101 DEM047_CTRS_COILCURR_HIGH_BMS14 3 "DEM_INVALID" 2 "DEM_FAILED" 1 "DEM_PASSED" 0 "DEM_NOTTESTED" ;
VAL_ 1101 DEM048_CTRS_CTRPWRV_LOW_BMS14 3 "DEM_INVALID" 2 "DEM_FAILED" 1 "DEM_PASSED" 0 "DEM_NOTTESTED" ;
VAL_ 1101 DEM049_CHGE_ILLEGAL_DISCHG_BMS14 3 "DEM_INVALID" 2 "DEM_FAILED" 1 "DEM_PASSED" 0 "DEM_NOTTESTED" ;
VAL_ 1101 DEM050_STARTUP_CONDITIONS_BMS14 3 "DEM_INVALID" 2 "DEM_FAILED" 1 "DEM_PASSED" 0 "DEM_NOTTESTED" ;
VAL_ 1101 DEM051_VOLTAGE_BMS_SUPPLYH_BMS14 3 "DEM_INVALID" 2 "DEM_FAILED" 1 "DEM_PASSED" 0 "DEM_NOTTESTED" ;
VAL_ 1101 DEM052_SAFETYSPI_FAIL_BMS14 3 "DEM_INVALID" 2 "DEM_FAILED" 1 "DEM_PASSED" 0 "DEM_NOTTESTED" ;
VAL_ 1101 DEM053_WATCHDOG_ERRORPIN_BMS14 3 "DEM_INVALID" 2 "DEM_FAILED" 1 "DEM_PASSED" 0 "DEM_NOTTESTED" ;
VAL_ 1101 DEM054_SAFESTATE_TRIGGERED_BMS14 3 "DEM_INVALID" 2 "DEM_FAILED" 1 "DEM_PASSED" 0 "DEM_NOTTESTED" ;
VAL_ 1101 DEM055_DEBUG_CMND_ACTIVE_BMS14 3 "DEM_INVALID" 2 "DEM_FAILED" 1 "DEM_PASSED" 0 "DEM_NOTTESTED" ;
VAL_ 1101 DEM056_CRASH_CAN_BMS14 3 "DEM_INVALID" 2 "DEM_FAILED" 1 "DEM_PASSED" 0 "DEM_NOTTESTED" ;
VAL_ 1101 DEM057_ISO_EXT_STRAT_4_BMS14 3 "DEM_INVALID" 2 "DEM_FAILED" 1 "DEM_PASSED" 0 "DEM_NOTTESTED" ;
VAL_ 1101 DEM058_ISO_EXT_RES_ERR_BMS14 3 "DEM_INVALID" 2 "DEM_FAILED" 1 "DEM_PASSED" 0 "DEM_NOTTESTED" ;
VAL_ 1101 DEM059_ISO_EXT_RES_WARN_BMS14 3 "DEM_INVALID" 2 "DEM_FAILED" 1 "DEM_PASSED" 0 "DEM_NOTTESTED" ;
VAL_ 1101 DEM060_ISO_INT_RES_ERR_BMS14 3 "DEM_INVALID" 2 "DEM_FAILED" 1 "DEM_PASSED" 0 "DEM_NOTTESTED" ;
VAL_ 1101 DEM061_ISO_INT_RES_WARN_BMS14 3 "DEM_INVALID" 2 "DEM_FAILED" 1 "DEM_PASSED" 0 "DEM_NOTTESTED" ;
VAL_ 1101 DEM062_EMERGENCY_OPERATION_BMS14 3 "DEM_INVALID" 2 "DEM_FAILED" 1 "DEM_PASSED" 0 "DEM_NOTTESTED" ;
VAL_ 1101 DEM063_ENDOFDRIVE_BMS14 3 "DEM_INVALID" 2 "DEM_FAILED" 1 "DEM_PASSED" 0 "DEM_NOTTESTED" ;
VAL_ 1165 DEM064_STRINGV_IMBALANCE_BMS14 3 "DEM_INVALID" 2 "DEM_FAILED" 1 "DEM_PASSED" 0 "DEM_NOTTESTED" ;
VAL_ 1165 DEM065_STRING_FAULT_BMS14 3 "DEM_INVALID" 2 "DEM_FAILED" 1 "DEM_PASSED" 0 "DEM_NOTTESTED" ;
VAL_ 1165 DEM066_ESS_FAULT_BMS14 3 "DEM_INVALID" 2 "DEM_FAILED" 1 "DEM_PASSED" 0 "DEM_NOTTESTED" ;
VAL_ 1165 DEM067_ISO_EXT_STRAT_3_BMS14 3 "DEM_INVALID" 2 "DEM_FAILED" 1 "DEM_PASSED" 0 "DEM_NOTTESTED" ;
VAL_ 1165 DEM068_MODULE_COUNT_INVALI_BMS14 3 "DEM_INVALID" 2 "DEM_FAILED" 1 "DEM_PASSED" 0 "DEM_NOTTESTED" ;
VAL_ 1165 DEM069_PT_MIA_BMS14 3 "DEM_INVALID" 2 "DEM_FAILED" 1 "DEM_PASSED" 0 "DEM_NOTTESTED" ;
VAL_ 1165 DEM070_BMSMIA_STRNGMSTR_01_BMS14 3 "DEM_INVALID" 2 "DEM_FAILED" 1 "DEM_PASSED" 0 "DEM_NOTTESTED" ;
VAL_ 1165 DEM071_BMSMIA_STRNGMSTR_05_BMS14 3 "DEM_INVALID" 2 "DEM_FAILED" 1 "DEM_PASSED" 0 "DEM_NOTTESTED" ;
VAL_ 1165 DEM072_BMSMIA_STRNGMSTR_09_BMS14 3 "DEM_INVALID" 2 "DEM_FAILED" 1 "DEM_PASSED" 0 "DEM_NOTTESTED" ;
VAL_ 1165 DEM073_BMSMIA_STRNGMSTR_13_BMS14 3 "DEM_INVALID" 2 "DEM_FAILED" 1 "DEM_PASSED" 0 "DEM_NOTTESTED" ;
VAL_ 1165 DEM074_BMSMIA_STRNGMSTR_17_BMS14 3 "DEM_INVALID" 2 "DEM_FAILED" 1 "DEM_PASSED" 0 "DEM_NOTTESTED" ;
VAL_ 1165 DEM075_BMSMIA_STRNGMSTR_21_BMS14 3 "DEM_INVALID" 2 "DEM_FAILED" 1 "DEM_PASSED" 0 "DEM_NOTTESTED" ;
VAL_ 1165 DEM076_BMSMIA_STRNGMSTR_25_BMS14 3 "DEM_INVALID" 2 "DEM_FAILED" 1 "DEM_PASSED" 0 "DEM_NOTTESTED" ;
VAL_ 1165 DEM077_BMSMIA_STRNGMSTR_29_BMS14 3 "DEM_INVALID" 2 "DEM_FAILED" 1 "DEM_PASSED" 0 "DEM_NOTTESTED" ;
VAL_ 1165 DEM078_BMSMIA_STRNGMSTR_33_BMS14 3 "DEM_INVALID" 2 "DEM_FAILED" 1 "DEM_PASSED" 0 "DEM_NOTTESTED" ;
VAL_ 1165 DEM079_BMSMIA_STRNGMSTR_37_BMS14 3 "DEM_INVALID" 2 "DEM_FAILED" 1 "DEM_PASSED" 0 "DEM_NOTTESTED" ;
VAL_ 1165 DEM080_BMSMIA_STRNGMSTR_41_BMS14 3 "DEM_INVALID" 2 "DEM_FAILED" 1 "DEM_PASSED" 0 "DEM_NOTTESTED" ;
VAL_ 1165 DEM081_BMSMIA_STRNGMSTR_45_BMS14 3 "DEM_INVALID" 2 "DEM_FAILED" 1 "DEM_PASSED" 0 "DEM_NOTTESTED" ;
VAL_ 1165 DEM082_BMSMIA_STRNGMSTR_49_BMS14 3 "DEM_INVALID" 2 "DEM_FAILED" 1 "DEM_PASSED" 0 "DEM_NOTTESTED" ;
VAL_ 1165 DEM083_BMSMIA_STRNGMSTR_53_BMS14 3 "DEM_INVALID" 2 "DEM_FAILED" 1 "DEM_PASSED" 0 "DEM_NOTTESTED" ;
VAL_ 1165 DEM084_BMSMIA_STRNGMSTR_57_BMS14 3 "DEM_INVALID" 2 "DEM_FAILED" 1 "DEM_PASSED" 0 "DEM_NOTTESTED" ;
VAL_ 1165 DEM085_BMSMIA_STRNGMSTR_61_BMS14 3 "DEM_INVALID" 2 "DEM_FAILED" 1 "DEM_PASSED" 0 "DEM_NOTTESTED" ;
VAL_ 1165 DEM086_ESSCURRENT_SHORT_BMS14 3 "DEM_INVALID" 2 "DEM_FAILED" 1 "DEM_PASSED" 0 "DEM_NOTTESTED" ;
VAL_ 1165 DEM087_PT_MIA_SHUTDOWN_BMS14 3 "DEM_INVALID" 2 "DEM_FAILED" 1 "DEM_PASSED" 0 "DEM_NOTTESTED" ;
VAL_ 1165 DEM088_OUTLET_NTC_HI_BMS14 3 "DEM_INVALID" 2 "DEM_FAILED" 1 "DEM_PASSED" 0 "DEM_NOTTESTED" ;
VAL_ 1165 DEM089_OUTLET_NTC_LO_BMS14 3 "DEM_INVALID" 2 "DEM_FAILED" 1 "DEM_PASSED" 0 "DEM_NOTTESTED" ;
VAL_ 1165 DEM090_BMSMIA_ESSMASTER_BMS14 3 "DEM_INVALID" 2 "DEM_FAILED" 1 "DEM_PASSED" 0 "DEM_NOTTESTED" ;
VAL_ 1165 DEM091_PCHG_RES_OVERHEAT_BMS14 3 "DEM_INVALID" 2 "DEM_FAILED" 1 "DEM_PASSED" 0 "DEM_NOTTESTED" ;
VAL_ 1165 DEM092_BMSMIA_STRNGSLAVE_0_BMS14 3 "DEM_INVALID" 2 "DEM_FAILED" 1 "DEM_PASSED" 0 "DEM_NOTTESTED" ;
VAL_ 1165 DEM093_BMSMIA_STRNGSLAVE_1_BMS14 3 "DEM_INVALID" 2 "DEM_FAILED" 1 "DEM_PASSED" 0 "DEM_NOTTESTED" ;
VAL_ 1165 DEM094_BMSMIA_STRNGSLAVE_2_BMS14 3 "DEM_INVALID" 2 "DEM_FAILED" 1 "DEM_PASSED" 0 "DEM_NOTTESTED" ;
VAL_ 1165 DEM095_BMSMIA_STRNGSLAVE_3_BMS14 3 "DEM_INVALID" 2 "DEM_FAILED" 1 "DEM_PASSED" 0 "DEM_NOTTESTED" ;
VAL_ 1229 DEM096_SC_STATE_SELFTEST_BMS14 3 "DEM_INVALID" 2 "DEM_FAILED" 1 "DEM_PASSED" 0 "DEM_NOTTESTED" ;
VAL_ 1229 DEM097_SC_STATE_TEMP_BMS14 3 "DEM_INVALID" 2 "DEM_FAILED" 1 "DEM_PASSED" 0 "DEM_NOTTESTED" ;
VAL_ 1229 DEM098_SC_STATE_VOLTAGE_BMS14 3 "DEM_INVALID" 2 "DEM_FAILED" 1 "DEM_PASSED" 0 "DEM_NOTTESTED" ;
VAL_ 1229 DEM099_SC_STATE_HVIL_BMS14 3 "DEM_INVALID" 2 "DEM_FAILED" 1 "DEM_PASSED" 0 "DEM_NOTTESTED" ;
VAL_ 1229 DEM100_SC_STATE_CONTACTORS_BMS14 3 "DEM_INVALID" 2 "DEM_FAILED" 1 "DEM_PASSED" 0 "DEM_NOTTESTED" ;
VAL_ 1229 DEM101_SC_STATE_CURRENT_BMS14 3 "DEM_INVALID" 2 "DEM_FAILED" 1 "DEM_PASSED" 0 "DEM_NOTTESTED" ;
VAL_ 1229 DEM102_SC_STATE_CANRX_BMS14 3 "DEM_INVALID" 2 "DEM_FAILED" 1 "DEM_PASSED" 0 "DEM_NOTTESTED" ;
VAL_ 1229 DEM103_SC_STATE_CRASH_BMS14 3 "DEM_INVALID" 2 "DEM_FAILED" 1 "DEM_PASSED" 0 "DEM_NOTTESTED" ;
VAL_ 1229 DEM104_SC_STATE_CCTRL_BMS14 3 "DEM_INVALID" 2 "DEM_FAILED" 1 "DEM_PASSED" 0 "DEM_NOTTESTED" ;
VAL_ 1229 DEM105_SC_STATE_CANTX_BMS14 3 "DEM_INVALID" 2 "DEM_FAILED" 1 "DEM_PASSED" 0 "DEM_NOTTESTED" ;
VAL_ 1229 DEM106_SC_STATE_THERMALEVT_BMS14 3 "DEM_INVALID" 2 "DEM_FAILED" 1 "DEM_PASSED" 0 "DEM_NOTTESTED" ;
VAL_ 1229 DEM107_SC_STATE_COOLANT_BMS14 3 "DEM_INVALID" 2 "DEM_FAILED" 1 "DEM_PASSED" 0 "DEM_NOTTESTED" ;
VAL_ 1229 DEM108_SC_SELFTEST_SFTY_UC_BMS14 3 "DEM_INVALID" 2 "DEM_FAILED" 1 "DEM_PASSED" 0 "DEM_NOTTESTED" ;
VAL_ 1229 DEM109_SC_TEMP_HIGH_BMS14 3 "DEM_INVALID" 2 "DEM_FAILED" 1 "DEM_PASSED" 0 "DEM_NOTTESTED" ;
VAL_ 1229 DEM110_SC_TEMP_NTC_OPEN_BMS14 3 "DEM_INVALID" 2 "DEM_FAILED" 1 "DEM_PASSED" 0 "DEM_NOTTESTED" ;
VAL_ 1229 DEM111_SC_TEMP_NTC_SHORT_BMS14 3 "DEM_INVALID" 2 "DEM_FAILED" 1 "DEM_PASSED" 0 "DEM_NOTTESTED" ;
VAL_ 1229 DEM112_CMB_DISCONNECTED_BMS14 3 "DEM_INVALID" 2 "DEM_FAILED" 1 "DEM_PASSED" 0 "DEM_NOTTESTED" ;
VAL_ 1229 DEM113_CMB_DEFECT_BMS14 3 "DEM_INVALID" 2 "DEM_FAILED" 1 "DEM_PASSED" 0 "DEM_NOTTESTED" ;
VAL_ 1229 DEM114_CMB_COMMERROR_BMS14 3 "DEM_INVALID" 2 "DEM_FAILED" 1 "DEM_PASSED" 0 "DEM_NOTTESTED" ;
VAL_ 1229 DEM115_SC_CURR_HALL_PWR_LO_BMS14 3 "DEM_INVALID" 2 "DEM_FAILED" 1 "DEM_PASSED" 0 "DEM_NOTTESTED" ;
VAL_ 1229 DEM116_SC_CURR_HALL_VHIGH_BMS14 3 "DEM_INVALID" 2 "DEM_FAILED" 1 "DEM_PASSED" 0 "DEM_NOTTESTED" ;
VAL_ 1229 DEM117_SC_CURR_HALL_ADC_BMS14 3 "DEM_INVALID" 2 "DEM_FAILED" 1 "DEM_PASSED" 0 "DEM_NOTTESTED" ;
VAL_ 1229 DEM118_SC_CURR_HALL_VLOW_BMS14 3 "DEM_INVALID" 2 "DEM_FAILED" 1 "DEM_PASSED" 0 "DEM_NOTTESTED" ;
VAL_ 1229 DEM119_SC_CURR_ISENSE_PWR_BMS14 3 "DEM_INVALID" 2 "DEM_FAILED" 1 "DEM_PASSED" 0 "DEM_NOTTESTED" ;
VAL_ 1229 DEM120_SC_CURR_ISENSE1_MIA_BMS14 3 "DEM_INVALID" 2 "DEM_FAILED" 1 "DEM_PASSED" 0 "DEM_NOTTESTED" ;
VAL_ 1229 DEM121_SC_CURR_ISENSE2_MIA_BMS14 3 "DEM_INVALID" 2 "DEM_FAILED" 1 "DEM_PASSED" 0 "DEM_NOTTESTED" ;
VAL_ 1229 DEM122_SC_CURR_ISENSE3_MIA_BMS14 3 "DEM_INVALID" 2 "DEM_FAILED" 1 "DEM_PASSED" 0 "DEM_NOTTESTED" ;
VAL_ 1229 DEM123_SC_CURR_ISENSE4_MIA_BMS14 3 "DEM_INVALID" 2 "DEM_FAILED" 1 "DEM_PASSED" 0 "DEM_NOTTESTED" ;
VAL_ 1229 DEM124_SC_CURR_ISENSE5_MIA_BMS14 3 "DEM_INVALID" 2 "DEM_FAILED" 1 "DEM_PASSED" 0 "DEM_NOTTESTED" ;
VAL_ 1229 DEM125_SC_CURR_ISENSE1_FLT_BMS14 3 "DEM_INVALID" 2 "DEM_FAILED" 1 "DEM_PASSED" 0 "DEM_NOTTESTED" ;
VAL_ 1229 DEM126_SC_CURR_ISENSE2_FLT_BMS14 3 "DEM_INVALID" 2 "DEM_FAILED" 1 "DEM_PASSED" 0 "DEM_NOTTESTED" ;
VAL_ 1229 DEM127_SC_CURR_ISENSE3_FLT_BMS14 3 "DEM_INVALID" 2 "DEM_FAILED" 1 "DEM_PASSED" 0 "DEM_NOTTESTED" ;
VAL_ 1293 DEM128_SC_CURR_ISENSE4_FLT_BMS14 3 "DEM_INVALID" 2 "DEM_FAILED" 1 "DEM_PASSED" 0 "DEM_NOTTESTED" ;
VAL_ 1293 DEM129_SC_CURR_ISENSE5_FLT_BMS14 3 "DEM_INVALID" 2 "DEM_FAILED" 1 "DEM_PASSED" 0 "DEM_NOTTESTED" ;
VAL_ 1293 DEM130_SC_CURR_OFFSET_BMS14 3 "DEM_INVALID" 2 "DEM_FAILED" 1 "DEM_PASSED" 0 "DEM_NOTTESTED" ;
VAL_ 1293 DEM131_SC_CURR_PLAUSI_BMS14 3 "DEM_INVALID" 2 "DEM_FAILED" 1 "DEM_PASSED" 0 "DEM_NOTTESTED" ;
VAL_ 1293 DEM132_SC_CURR_CHARGE_HIGH_BMS14 3 "DEM_INVALID" 2 "DEM_FAILED" 1 "DEM_PASSED" 0 "DEM_NOTTESTED" ;
VAL_ 1293 DEM133_SC_CURR_DSCHAR_HIGH_BMS14 3 "DEM_INVALID" 2 "DEM_FAILED" 1 "DEM_PASSED" 0 "DEM_NOTTESTED" ;
VAL_ 1293 DEM134_SC_V_CMB_SUMOFCELL_BMS14 3 "DEM_INVALID" 2 "DEM_FAILED" 1 "DEM_PASSED" 0 "DEM_NOTTESTED" ;
VAL_ 1293 DEM135_SC_V_SENSE_OPENWIRE_BMS14 3 "DEM_INVALID" 2 "DEM_FAILED" 1 "DEM_PASSED" 0 "DEM_NOTTESTED" ;
VAL_ 1293 DEM136_SC_V_CMB_DRV_FROZEN_BMS14 3 "DEM_INVALID" 2 "DEM_FAILED" 1 "DEM_PASSED" 0 "DEM_NOTTESTED" ;
VAL_ 1293 DEM137_SC_V_PACK_PLAUSI_BMS14 3 "DEM_INVALID" 2 "DEM_FAILED" 1 "DEM_PASSED" 0 "DEM_NOTTESTED" ;
VAL_ 1293 DEM138_SC_HVIL_HW_FLT_BMS14 3 "DEM_INVALID" 2 "DEM_FAILED" 1 "DEM_PASSED" 0 "DEM_NOTTESTED" ;
VAL_ 1293 DEM139_SC_HVIL_OPEN_BMS14 3 "DEM_INVALID" 2 "DEM_FAILED" 1 "DEM_PASSED" 0 "DEM_NOTTESTED" ;
VAL_ 1293 DEM140_SC_HVIL_TO_SUP_BMS14 3 "DEM_INVALID" 2 "DEM_FAILED" 1 "DEM_PASSED" 0 "DEM_NOTTESTED" ;
VAL_ 1293 DEM141_SC_HVIL_TO_CHAS_BMS14 3 "DEM_INVALID" 2 "DEM_FAILED" 1 "DEM_PASSED" 0 "DEM_NOTTESTED" ;
VAL_ 1293 DEM142_SC_HVIL_R_HIGH_BMS14 3 "DEM_INVALID" 2 "DEM_FAILED" 1 "DEM_PASSED" 0 "DEM_NOTTESTED" ;
VAL_ 1293 DEM143_SC_HVIL_SHORT_BMS14 3 "DEM_INVALID" 2 "DEM_FAILED" 1 "DEM_PASSED" 0 "DEM_NOTTESTED" ;
VAL_ 1293 DEM144_SC_CN_ISO_FAIL_BMS14 3 "DEM_INVALID" 2 "DEM_FAILED" 1 "DEM_PASSED" 0 "DEM_NOTTESTED" ;
VAL_ 1293 DEM145_HVIL_SYS_BMS14 3 "DEM_INVALID" 2 "DEM_FAILED" 1 "DEM_PASSED" 0 "DEM_NOTTESTED" ;
VAL_ 1293 DEM146_SC_CN_POS1_WELDED_BMS14 3 "DEM_INVALID" 2 "DEM_FAILED" 1 "DEM_PASSED" 0 "DEM_NOTTESTED" ;
VAL_ 1293 DEM147_SC_CN_NEG1_WELDED_BMS14 3 "DEM_INVALID" 2 "DEM_FAILED" 1 "DEM_PASSED" 0 "DEM_NOTTESTED" ;
VAL_ 1293 DEM148_SC_CN_POS2_WELDED_BMS14 3 "DEM_INVALID" 2 "DEM_FAILED" 1 "DEM_PASSED" 0 "DEM_NOTTESTED" ;
VAL_ 1293 DEM149_SC_CN_NEG2_WELDED_BMS14 3 "DEM_INVALID" 2 "DEM_FAILED" 1 "DEM_PASSED" 0 "DEM_NOTTESTED" ;
VAL_ 1293 DEM150_SC_CN_POS3_WELDED_BMS14 3 "DEM_INVALID" 2 "DEM_FAILED" 1 "DEM_PASSED" 0 "DEM_NOTTESTED" ;
VAL_ 1293 DEM151_SC_CN_NEG3_WELDED_BMS14 3 "DEM_INVALID" 2 "DEM_FAILED" 1 "DEM_PASSED" 0 "DEM_NOTTESTED" ;
VAL_ 1293 DEM152_SC_CN_HIGH_CY_BMS14 3 "DEM_INVALID" 2 "DEM_FAILED" 1 "DEM_PASSED" 0 "DEM_NOTTESTED" ;
VAL_ 1293 DEM153_SC_CN_ISOANDPOTWELD_BMS14 3 "DEM_INVALID" 2 "DEM_FAILED" 1 "DEM_PASSED" 0 "DEM_NOTTESTED" ;
VAL_ 1293 DEM154_SC_TEMP_PLAUSI_BMS14 3 "DEM_INVALID" 2 "DEM_FAILED" 1 "DEM_PASSED" 0 "DEM_NOTTESTED" ;
VAL_ 1293 DEM155_SC_CURR_HALL_PWR_HI_BMS14 3 "DEM_INVALID" 2 "DEM_FAILED" 1 "DEM_PASSED" 0 "DEM_NOTTESTED" ;
VAL_ 1293 DEM156_SC_PYRO_TRIGGERED_BMS14 3 "DEM_INVALID" 2 "DEM_FAILED" 1 "DEM_PASSED" 0 "DEM_NOTTESTED" ;
VAL_ 1293 DEM157_SC_PYRO_OPEN_BMS14 3 "DEM_INVALID" 2 "DEM_FAILED" 1 "DEM_PASSED" 0 "DEM_NOTTESTED" ;
VAL_ 1293 DEM158_AUX_CTRS_END_OF_LIF_BMS14 3 "DEM_INVALID" 2 "DEM_FAILED" 1 "DEM_PASSED" 0 "DEM_NOTTESTED" ;
VAL_ 1293 DEM159_SC_CANRX_PT_MIA_BMS14 3 "DEM_INVALID" 2 "DEM_FAILED" 1 "DEM_PASSED" 0 "DEM_NOTTESTED" ;
VAL_ 1357 DEM160_SC_CANRX_PT_CRCALIV_BMS14 3 "DEM_INVALID" 2 "DEM_FAILED" 1 "DEM_PASSED" 0 "DEM_NOTTESTED" ;
VAL_ 1357 DEM161_SC_CANRX_LIN_SHUTDN_BMS14 3 "DEM_INVALID" 2 "DEM_FAILED" 1 "DEM_PASSED" 0 "DEM_NOTTESTED" ;
VAL_ 1357 DEM162_SC_CANRX_LIN_MIA_BMS14 3 "DEM_INVALID" 2 "DEM_FAILED" 1 "DEM_PASSED" 0 "DEM_NOTTESTED" ;
VAL_ 1357 DEM163_SC_CRASH1_BMS14 3 "DEM_INVALID" 2 "DEM_FAILED" 1 "DEM_PASSED" 0 "DEM_NOTTESTED" ;
VAL_ 1357 DEM164_SC_CRASH2_BMS14 3 "DEM_INVALID" 2 "DEM_FAILED" 1 "DEM_PASSED" 0 "DEM_NOTTESTED" ;
VAL_ 1357 DEM165_SC_CRASHCAN_BMS14 3 "DEM_INVALID" 2 "DEM_FAILED" 1 "DEM_PASSED" 0 "DEM_NOTTESTED" ;
VAL_ 1357 DEM166_SC_CCTRL_SELFTEST_BMS14 3 "DEM_INVALID" 2 "DEM_FAILED" 1 "DEM_PASSED" 0 "DEM_NOTTESTED" ;
VAL_ 1357 DEM167_SC_CCTRL_DRIVER_FAU_BMS14 3 "DEM_INVALID" 2 "DEM_FAILED" 1 "DEM_PASSED" 0 "DEM_NOTTESTED" ;
VAL_ 1357 DEM168_SC_CCTRL_HISIDESTCL_BMS14 3 "DEM_INVALID" 2 "DEM_FAILED" 1 "DEM_PASSED" 0 "DEM_NOTTESTED" ;
VAL_ 1357 DEM169_SC_CCTRL_HISIDESTOP_BMS14 3 "DEM_INVALID" 2 "DEM_FAILED" 1 "DEM_PASSED" 0 "DEM_NOTTESTED" ;
VAL_ 1357 DEM170_SC_CCTRL_LOSIDESTCL_BMS14 3 "DEM_INVALID" 2 "DEM_FAILED" 1 "DEM_PASSED" 0 "DEM_NOTTESTED" ;
VAL_ 1357 DEM171_SC_CCTRL_HVCNDITION_BMS14 3 "DEM_INVALID" 2 "DEM_FAILED" 1 "DEM_PASSED" 0 "DEM_NOTTESTED" ;
VAL_ 1357 DEM172_SC_CCTRL_POS1_OPN_BMS14 3 "DEM_INVALID" 2 "DEM_FAILED" 1 "DEM_PASSED" 0 "DEM_NOTTESTED" ;
VAL_ 1357 DEM173_SC_CCTRL_POS2_OPN_BMS14 3 "DEM_INVALID" 2 "DEM_FAILED" 1 "DEM_PASSED" 0 "DEM_NOTTESTED" ;
VAL_ 1357 DEM174_SC_CCTRL_POS3_OPN_BMS14 3 "DEM_INVALID" 2 "DEM_FAILED" 1 "DEM_PASSED" 0 "DEM_NOTTESTED" ;
VAL_ 1357 DEM175_SC_CCTRL_NEG1_OPN_BMS14 3 "DEM_INVALID" 2 "DEM_FAILED" 1 "DEM_PASSED" 0 "DEM_NOTTESTED" ;
VAL_ 1357 DEM176_SC_CCTRL_NEG2_OPN_BMS14 3 "DEM_INVALID" 2 "DEM_FAILED" 1 "DEM_PASSED" 0 "DEM_NOTTESTED" ;
VAL_ 1357 DEM177_SC_CCTRL_PRE2_OPN_BMS14 3 "DEM_INVALID" 2 "DEM_FAILED" 1 "DEM_PASSED" 0 "DEM_NOTTESTED" ;
VAL_ 1357 DEM178_SC_CCTRL_PRE1_OPN_BMS14 3 "DEM_INVALID" 2 "DEM_FAILED" 1 "DEM_PASSED" 0 "DEM_NOTTESTED" ;
VAL_ 1357 DEM179_SC_CCTRL_LOSIDESTOP_BMS14 3 "DEM_INVALID" 2 "DEM_FAILED" 1 "DEM_PASSED" 0 "DEM_NOTTESTED" ;
VAL_ 1357 DEM180_SC_CCTRL_UNEXPECTED_BMS14 3 "DEM_INVALID" 2 "DEM_FAILED" 1 "DEM_PASSED" 0 "DEM_NOTTESTED" ;
VAL_ 1357 DEM181_SC_V_OUT_OF_RANGE_BMS14 3 "DEM_INVALID" 2 "DEM_FAILED" 1 "DEM_PASSED" 0 "DEM_NOTTESTED" ;
VAL_ 1357 DEM182_SC_V_LATCHED_UVOV_BMS14 3 "DEM_INVALID" 2 "DEM_FAILED" 1 "DEM_PASSED" 0 "DEM_NOTTESTED" ;
VAL_ 1357 DEM183_ISO_EXT_STRAT_2_BMS14 3 "DEM_INVALID" 2 "DEM_FAILED" 1 "DEM_PASSED" 0 "DEM_NOTTESTED" ;
VAL_ 1357 DEM184_SC_CANTX_CTRS_BMS14 3 "DEM_INVALID" 2 "DEM_FAILED" 1 "DEM_PASSED" 0 "DEM_NOTTESTED" ;
VAL_ 1357 DEM185_SC_CANTX_HVIL_BMS14 3 "DEM_INVALID" 2 "DEM_FAILED" 1 "DEM_PASSED" 0 "DEM_NOTTESTED" ;
VAL_ 1357 DEM186_SC_CANTX_ISOL_BMS14 3 "DEM_INVALID" 2 "DEM_FAILED" 1 "DEM_PASSED" 0 "DEM_NOTTESTED" ;
VAL_ 1357 DEM187_SC_SBC_WATCHDOG_BMS14 3 "DEM_INVALID" 2 "DEM_FAILED" 1 "DEM_PASSED" 0 "DEM_NOTTESTED" ;
VAL_ 1357 DEM188_SC_SBC_FAULT_BMS14 3 "DEM_INVALID" 2 "DEM_FAILED" 1 "DEM_PASSED" 0 "DEM_NOTTESTED" ;
VAL_ 1357 DEM189_SC_WATCHDOG_BMS14 3 "DEM_INVALID" 2 "DEM_FAILED" 1 "DEM_PASSED" 0 "DEM_NOTTESTED" ;
VAL_ 1357 DEM190_SC_SELFTEST_RAM_BMS14 3 "DEM_INVALID" 2 "DEM_FAILED" 1 "DEM_PASSED" 0 "DEM_NOTTESTED" ;
VAL_ 1357 DEM191_SC_SELFTEST_FLASH_BMS14 3 "DEM_INVALID" 2 "DEM_FAILED" 1 "DEM_PASSED" 0 "DEM_NOTTESTED" ;
VAL_ 1421 DEM192_CMB_ONBOARDRH_OH_BMS14 3 "DEM_INVALID" 2 "DEM_FAILED" 1 "DEM_PASSED" 0 "DEM_NOTTESTED" ;
VAL_ 1421 DEM193_CMB_ONBOARDRH_SNA_BMS14 3 "DEM_INVALID" 2 "DEM_FAILED" 1 "DEM_PASSED" 0 "DEM_NOTTESTED" ;
VAL_ 1421 DEM194_CMB_ONBOARDT_OT_BMS14 3 "DEM_INVALID" 2 "DEM_FAILED" 1 "DEM_PASSED" 0 "DEM_NOTTESTED" ;
VAL_ 1421 DEM195_CMB_ONBOARDT_CHANGE_BMS14 3 "DEM_INVALID" 2 "DEM_FAILED" 1 "DEM_PASSED" 0 "DEM_NOTTESTED" ;
VAL_ 1421 DEM196_PRESSURE_CHANGE_BMS14 3 "DEM_INVALID" 2 "DEM_FAILED" 1 "DEM_PASSED" 0 "DEM_NOTTESTED" ;
VAL_ 1421 DEM197_PRESSURE_OVER_BMS14 3 "DEM_INVALID" 2 "DEM_FAILED" 1 "DEM_PASSED" 0 "DEM_NOTTESTED" ;
VAL_ 1421 DEM198_PRESSURE_UNDER_BMS14 3 "DEM_INVALID" 2 "DEM_FAILED" 1 "DEM_PASSED" 0 "DEM_NOTTESTED" ;
VAL_ 1421 DEM199_PRESSURE_INVALID_BMS14 3 "DEM_INVALID" 2 "DEM_FAILED" 1 "DEM_PASSED" 0 "DEM_NOTTESTED" ;
VAL_ 1421 DEM200_THERMAL_EVENT_BMS14 3 "DEM_INVALID" 2 "DEM_FAILED" 1 "DEM_PASSED" 0 "DEM_NOTTESTED" ;
VAL_ 1421 DEM201_CMB_ONBOARDT_SNA_BMS14 3 "DEM_INVALID" 2 "DEM_FAILED" 1 "DEM_PASSED" 0 "DEM_NOTTESTED" ;
VAL_ 1421 DEM202_REPLACE_DESICCANT_BMS14 3 "DEM_INVALID" 2 "DEM_FAILED" 1 "DEM_PASSED" 0 "DEM_NOTTESTED" ;
VAL_ 1421 DEM203_COOLANT_FLOOD_FAULT_BMS14 3 "DEM_INVALID" 2 "DEM_FAILED" 1 "DEM_PASSED" 0 "DEM_NOTTESTED" ;
VAL_ 1421 DEM204_LOW_BRICKCAPACITY_BMS14 3 "DEM_INVALID" 2 "DEM_FAILED" 1 "DEM_PASSED" 0 "DEM_NOTTESTED" ;
VAL_ 1421 DEM205_BMS_ONBOARDT_OT_BMS14 3 "DEM_INVALID" 2 "DEM_FAILED" 1 "DEM_PASSED" 0 "DEM_NOTTESTED" ;
VAL_ 1421 DEM206_HUMIDITY_CHANGE_BMS14 3 "DEM_INVALID" 2 "DEM_FAILED" 1 "DEM_PASSED" 0 "DEM_NOTTESTED" ;
VAL_ 1421 DEM207_ISENSE_SUPPLY_CURR_BMS14 3 "DEM_INVALID" 2 "DEM_FAILED" 1 "DEM_PASSED" 0 "DEM_NOTTESTED" ;
VAL_ 1421 DEM208_SOC_LOW_BMS14 3 "DEM_INVALID" 2 "DEM_FAILED" 1 "DEM_PASSED" 0 "DEM_NOTTESTED" ;
VAL_ 1421 DEM209_SOC_TOOLOW_BMS14 3 "DEM_INVALID" 2 "DEM_FAILED" 1 "DEM_PASSED" 0 "DEM_NOTTESTED" ;
VAL_ 1421 DEM210_SOC_TOOHIGH_BMS14 3 "DEM_INVALID" 2 "DEM_FAILED" 1 "DEM_PASSED" 0 "DEM_NOTTESTED" ;
VAL_ 1421 DEM211_BALANCING_REQUIRED_BMS14 3 "DEM_INVALID" 2 "DEM_FAILED" 1 "DEM_PASSED" 0 "DEM_NOTTESTED" ;
VAL_ 1421 DEM212_DEEP_DISCHARGE_BMS14 3 "DEM_INVALID" 2 "DEM_FAILED" 1 "DEM_PASSED" 0 "DEM_NOTTESTED" ;
VAL_ 1421 DEM213_CAN1_BUS_OFF_BMS14 3 "DEM_INVALID" 2 "DEM_FAILED" 1 "DEM_PASSED" 0 "DEM_NOTTESTED" ;
VAL_ 1421 DEM214_CAN2_BUS_OFF_BMS14 3 "DEM_INVALID" 2 "DEM_FAILED" 1 "DEM_PASSED" 0 "DEM_NOTTESTED" ;
VAL_ 1421 DEM215_CAN3_BUS_OFF_BMS14 3 "DEM_INVALID" 2 "DEM_FAILED" 1 "DEM_PASSED" 0 "DEM_NOTTESTED" ;
VAL_ 1421 DEM216_OUTLET_NTC_RATNAL_BMS14 3 "DEM_INVALID" 2 "DEM_FAILED" 1 "DEM_PASSED" 0 "DEM_NOTTESTED" ;
VAL_ 1421 DEM217_FUSE_PACK_BMS14 3 "DEM_INVALID" 2 "DEM_FAILED" 1 "DEM_PASSED" 0 "DEM_NOTTESTED" ;
VAL_ 1421 DEM218_FUSE_B_OPEN_BMS14 3 "DEM_INVALID" 2 "DEM_FAILED" 1 "DEM_PASSED" 0 "DEM_NOTTESTED" ;
VAL_ 1421 DEM219_FUSE_C_OPEN_BMS14 3 "DEM_INVALID" 2 "DEM_FAILED" 1 "DEM_PASSED" 0 "DEM_NOTTESTED" ;
VAL_ 1421 DEM220_FUSE_D_OPEN_BMS14 3 "DEM_INVALID" 2 "DEM_FAILED" 1 "DEM_PASSED" 0 "DEM_NOTTESTED" ;
VAL_ 1421 DEM221_FUSE_E_OPEN_BMS14 3 "DEM_INVALID" 2 "DEM_FAILED" 1 "DEM_PASSED" 0 "DEM_NOTTESTED" ;
VAL_ 1421 DEM222_PUMP_DRY_RUN_BMS14 3 "DEM_INVALID" 2 "DEM_FAILED" 1 "DEM_PASSED" 0 "DEM_NOTTESTED" ;
VAL_ 1421 DEM223_PUMP_PERFORMANCE_BMS14 3 "DEM_INVALID" 2 "DEM_FAILED" 1 "DEM_PASSED" 0 "DEM_NOTTESTED" ;
VAL_ 1485 DEM224_PUMP_LIN_FAILURE_BMS14 3 "DEM_INVALID" 2 "DEM_FAILED" 1 "DEM_PASSED" 0 "DEM_NOTTESTED" ;
VAL_ 1485 DEM225_PUMP_SUPPLY_VOLTAGE_BMS14 3 "DEM_INVALID" 2 "DEM_FAILED" 1 "DEM_PASSED" 0 "DEM_NOTTESTED" ;
VAL_ 1485 DEM226_PUMP_RECOVERY_FAIL_BMS14 3 "DEM_INVALID" 2 "DEM_FAILED" 1 "DEM_PASSED" 0 "DEM_NOTTESTED" ;
VAL_ 1485 DEM227_CTR_POS_OPENED_BMS14 3 "DEM_INVALID" 2 "DEM_FAILED" 1 "DEM_PASSED" 0 "DEM_NOTTESTED" ;
VAL_ 1485 DEM228_CTR_NEG_OPENED_BMS14 3 "DEM_INVALID" 2 "DEM_FAILED" 1 "DEM_PASSED" 0 "DEM_NOTTESTED" ;
VAL_ 1485 DEM229_STRSET_SLAVE1_FAULT_BMS14 3 "DEM_INVALID" 2 "DEM_FAILED" 1 "DEM_PASSED" 0 "DEM_NOTTESTED" ;
VAL_ 1485 DEM230_STRSET_SLAVE2_FAULT_BMS14 3 "DEM_INVALID" 2 "DEM_FAILED" 1 "DEM_PASSED" 0 "DEM_NOTTESTED" ;
VAL_ 1485 DEM231_CTRSAUX_CLFAIL_HVON_BMS14 3 "DEM_INVALID" 2 "DEM_FAILED" 1 "DEM_PASSED" 0 "DEM_NOTTESTED" ;
VAL_ 1485 DEM232_CTRSAUX_CLFAIL_VDIF_BMS14 3 "DEM_INVALID" 2 "DEM_FAILED" 1 "DEM_PASSED" 0 "DEM_NOTTESTED" ;
VAL_ 1485 DEM233_CTRSAUX_POS1_OPENED_BMS14 3 "DEM_INVALID" 2 "DEM_FAILED" 1 "DEM_PASSED" 0 "DEM_NOTTESTED" ;
VAL_ 1485 DEM234_CTRSAUX_NEG1_OPENED_BMS14 3 "DEM_INVALID" 2 "DEM_FAILED" 1 "DEM_PASSED" 0 "DEM_NOTTESTED" ;
VAL_ 1485 DEM235_CTRSAUX_POS1_WELDED_BMS14 3 "DEM_INVALID" 2 "DEM_FAILED" 1 "DEM_PASSED" 0 "DEM_NOTTESTED" ;
VAL_ 1485 DEM236_CTRSAUX_NEG1_WELDED_BMS14 3 "DEM_INVALID" 2 "DEM_FAILED" 1 "DEM_PASSED" 0 "DEM_NOTTESTED" ;
VAL_ 1485 DEM237_CTRSAUX_POS1_PULLIN_BMS14 3 "DEM_INVALID" 2 "DEM_FAILED" 1 "DEM_PASSED" 0 "DEM_NOTTESTED" ;
VAL_ 1485 DEM238_CTRSAUX_NEG1_PULLIN_BMS14 3 "DEM_INVALID" 2 "DEM_FAILED" 1 "DEM_PASSED" 0 "DEM_NOTTESTED" ;
VAL_ 1485 DEM239_INLET_NTC_RATNAL_BMS14 3 "DEM_INVALID" 2 "DEM_FAILED" 1 "DEM_PASSED" 0 "DEM_NOTTESTED" ;
VAL_ 1485 DEM240_INLET_NTC_HI_BMS14 3 "DEM_INVALID" 2 "DEM_FAILED" 1 "DEM_PASSED" 0 "DEM_NOTTESTED" ;
VAL_ 1485 DEM241_INLET_NTC_LO_BMS14 3 "DEM_INVALID" 2 "DEM_FAILED" 1 "DEM_PASSED" 0 "DEM_NOTTESTED" ;
VAL_ 1485 DEM242_VOLTAGE_LINK2_RATNA_BMS14 3 "DEM_INVALID" 2 "DEM_FAILED" 1 "DEM_PASSED" 0 "DEM_NOTTESTED" ;
VAL_ 1485 DEM243_VOLTAGE_LINK2_HI_BMS14 3 "DEM_INVALID" 2 "DEM_FAILED" 1 "DEM_PASSED" 0 "DEM_NOTTESTED" ;
VAL_ 1485 DEM244_VOLTAGE_LINK2_LO_BMS14 3 "DEM_INVALID" 2 "DEM_FAILED" 1 "DEM_PASSED" 0 "DEM_NOTTESTED" ;
VAL_ 1485 DEM245_CMB_ONBOARD_IMPOSSI_BMS14 3 "DEM_INVALID" 2 "DEM_FAILED" 1 "DEM_PASSED" 0 "DEM_NOTTESTED" ;
VAL_ 1485 DEM246_VOLTAGE_LINK1_HI_BMS14 3 "DEM_INVALID" 2 "DEM_FAILED" 1 "DEM_PASSED" 0 "DEM_NOTTESTED" ;
VAL_ 1485 DEM247_VOLTAGE_LINK1_LO_BMS14 3 "DEM_INVALID" 2 "DEM_FAILED" 1 "DEM_PASSED" 0 "DEM_NOTTESTED" ;
VAL_ 1485 DEM248_NTC_SUPPLY_LO_BMS14 3 "DEM_INVALID" 2 "DEM_FAILED" 1 "DEM_PASSED" 0 "DEM_NOTTESTED" ;
VAL_ 1485 DEM249_NTC_SUPPLY_HI_BMS14 3 "DEM_INVALID" 2 "DEM_FAILED" 1 "DEM_PASSED" 0 "DEM_NOTTESTED" ;
VAL_ 1485 DEM250_VOLTAGE_LINK3_RATNA_BMS14 3 "DEM_INVALID" 2 "DEM_FAILED" 1 "DEM_PASSED" 0 "DEM_NOTTESTED" ;
VAL_ 1485 DEM251_VOLTAGE_LINK3_HI_BMS14 3 "DEM_INVALID" 2 "DEM_FAILED" 1 "DEM_PASSED" 0 "DEM_NOTTESTED" ;
VAL_ 1485 DEM252_VOLTAGE_LINK3_LO_BMS14 3 "DEM_INVALID" 2 "DEM_FAILED" 1 "DEM_PASSED" 0 "DEM_NOTTESTED" ;
VAL_ 1485 DEM253_BALANCING_STUCK_BMS14 3 "DEM_INVALID" 2 "DEM_FAILED" 1 "DEM_PASSED" 0 "DEM_NOTTESTED" ;
VAL_ 1485 DEM254_ARM_EXCEPTION_BMS14 3 "DEM_INVALID" 2 "DEM_FAILED" 1 "DEM_PASSED" 0 "DEM_NOTTESTED" ;
VAL_ 1485 DEM255_ERROR_HOOKS_BMS14 3 "DEM_INVALID" 2 "DEM_FAILED" 1 "DEM_PASSED" 0 "DEM_NOTTESTED" ;
VAL_ 845 DEM256_XCP_CAL_CHANGE_BMS14 3 "DEM_INVALID" 2 "DEM_FAILED" 1 "DEM_PASSED" 0 "DEM_NOTTESTED" ;
VAL_ 845 DEM257_XCP_CAL_PERM_CHANGE_BMS14 3 "DEM_INVALID" 2 "DEM_FAILED" 1 "DEM_PASSED" 0 "DEM_NOTTESTED" ;
VAL_ 845 DEM258_TASK_TIME_OVERFLOW_BMS14 3 "DEM_INVALID" 2 "DEM_FAILED" 1 "DEM_PASSED" 0 "DEM_NOTTESTED" ;
VAL_ 845 DEM259_ISO_CIRCUIT_BMS14 3 "DEM_INVALID" 2 "DEM_FAILED" 1 "DEM_PASSED" 0 "DEM_NOTTESTED" ;
VAL_ 845 DEM260_COOLANT_MOIST_FAULT_BMS14 3 "DEM_INVALID" 2 "DEM_FAILED" 1 "DEM_PASSED" 0 "DEM_NOTTESTED" ;
VAL_ 845 DEM261_COOLANT_FLOOD_WARN_BMS14 3 "DEM_INVALID" 2 "DEM_FAILED" 1 "DEM_PASSED" 0 "DEM_NOTTESTED" ;
VAL_ 845 DEM262_COOLANT_MOIST_WARN_BMS14 3 "DEM_INVALID" 2 "DEM_FAILED" 1 "DEM_PASSED" 0 "DEM_NOTTESTED" ;
VAL_ 845 DEM263_MODULET_IMPLAUSIBLE_BMS14 3 "DEM_INVALID" 2 "DEM_FAILED" 1 "DEM_PASSED" 0 "DEM_NOTTESTED" ;
VAL_ 845 DEM264_REQUEST_ON_WITH_HV__BMS14 3 "DEM_INVALID" 2 "DEM_FAILED" 1 "DEM_PASSED" 0 "DEM_NOTTESTED" ;
VAL_ 845 DEM265_CSERS_PCODE_BMS14 3 "DEM_INVALID" 2 "DEM_FAILED" 1 "DEM_PASSED" 0 "DEM_NOTTESTED" ;
VAL_ 845 DEM266_PRELIM_CNTR_CL_FAIL_BMS14 3 "DEM_INVALID" 2 "DEM_FAILED" 1 "DEM_PASSED" 0 "DEM_NOTTESTED" ;
VAL_ 845 DEM267_FLUIDLVL_LOW_BMS14 3 "DEM_INVALID" 2 "DEM_FAILED" 1 "DEM_PASSED" 0 "DEM_NOTTESTED" ;
VAL_ 845 DEM268_FLUIDLVL_FAILURE_BMS14 3 "DEM_INVALID" 2 "DEM_FAILED" 1 "DEM_PASSED" 0 "DEM_NOTTESTED" ;
VAL_ 845 DEM269_SC_COOLANT_CONTAM_BMS14 3 "DEM_INVALID" 2 "DEM_FAILED" 1 "DEM_PASSED" 0 "DEM_NOTTESTED" ;
VAL_ 845 DEM270_SC_COOLANT_MIA_BMS14 3 "DEM_INVALID" 2 "DEM_FAILED" 1 "DEM_PASSED" 0 "DEM_NOTTESTED" ;
VAL_ 845 DEM271_PRESSURE_VHI_BMS14 3 "DEM_INVALID" 2 "DEM_FAILED" 1 "DEM_PASSED" 0 "DEM_NOTTESTED" ;
VAL_ 845 DEM272_PRESSURE_VLO_BMS14 3 "DEM_INVALID" 2 "DEM_FAILED" 1 "DEM_PASSED" 0 "DEM_NOTTESTED" ;
VAL_ 845 DEM273_SC_COOLANT_FAIL_BMS14 3 "DEM_INVALID" 2 "DEM_FAILED" 1 "DEM_PASSED" 0 "DEM_NOTTESTED" ;
VAL_ 845 DEM274_CTRSAUX_POS2_OPENED_BMS14 3 "DEM_INVALID" 2 "DEM_FAILED" 1 "DEM_PASSED" 0 "DEM_NOTTESTED" ;
VAL_ 845 DEM275_CTRSAUX_POS3_OPENED_BMS14 3 "DEM_INVALID" 2 "DEM_FAILED" 1 "DEM_PASSED" 0 "DEM_NOTTESTED" ;
VAL_ 845 DEM276_CTRSAUX_POS2_WELDED_BMS14 3 "DEM_INVALID" 2 "DEM_FAILED" 1 "DEM_PASSED" 0 "DEM_NOTTESTED" ;
VAL_ 845 DEM277_CTRSAUX_POS3_WELDED_BMS14 3 "DEM_INVALID" 2 "DEM_FAILED" 1 "DEM_PASSED" 0 "DEM_NOTTESTED" ;
VAL_ 845 DEM278_CTRSAUX_POS2_PULLIN_BMS14 3 "DEM_INVALID" 2 "DEM_FAILED" 1 "DEM_PASSED" 0 "DEM_NOTTESTED" ;
VAL_ 845 DEM279_CTRSAUX_POS3_PULLIN_BMS14 3 "DEM_INVALID" 2 "DEM_FAILED" 1 "DEM_PASSED" 0 "DEM_NOTTESTED" ;
VAL_ 845 DEM280_CMB_HUMIDITY_TEMP_C_BMS14 3 "DEM_INVALID" 2 "DEM_FAILED" 1 "DEM_PASSED" 0 "DEM_NOTTESTED" ;
VAL_ 845 DEM281_THERMAL_EVENT_CMB_R_BMS14 3 "DEM_INVALID" 2 "DEM_FAILED" 1 "DEM_PASSED" 0 "DEM_NOTTESTED" ;
VAL_ 845 DEM282_CUS_BRICKOV_BMS14 3 "DEM_INVALID" 2 "DEM_FAILED" 1 "DEM_PASSED" 0 "DEM_NOTTESTED" ;
VAL_ 845 DEM283_CUS_BRICKUV_BMS14 3 "DEM_INVALID" 2 "DEM_FAILED" 1 "DEM_PASSED" 0 "DEM_NOTTESTED" ;
VAL_ 845 DEM284_CUS_OVERCHRG_BMS14 3 "DEM_INVALID" 2 "DEM_FAILED" 1 "DEM_PASSED" 0 "DEM_NOTTESTED" ;
VAL_ 845 DEM285_CUS_OVERDCHRG_BMS14 3 "DEM_INVALID" 2 "DEM_FAILED" 1 "DEM_PASSED" 0 "DEM_NOTTESTED" ;
VAL_ 845 DEM286_CUS_CURRENT_CHG_BMS14 3 "DEM_INVALID" 2 "DEM_FAILED" 1 "DEM_PASSED" 0 "DEM_NOTTESTED" ;
VAL_ 845 DEM287_CUS_CURRENT_DCHG_BMS14 3 "DEM_INVALID" 2 "DEM_FAILED" 1 "DEM_PASSED" 0 "DEM_NOTTESTED" ;
VAL_ 1613 selfTestStartupFault_SC14 6 "SELFTEST_PBIST_OTHER_RAM_FAULT" 5 "SELFTEST_PBIST_CPU_RAM_FAULT" 4 "SELFTEST_PBIST_ROM_FAULT" 3 "SELFTEST_PBIST_STC_ROM_FAULT" 2 "SELFTEST_STC_FAULT" 1 "SELFTEST_CPU_FAULT" 0 "SELFTEST_STARTUP_OK" ;
VAL_ 1613 sbcARTimerStatus_SC14 15 "SNA" 6 "SBC_AR_COMPLETE" 5 "SBC_AR_INTERRUPTED" 4 "SBC_AR_READ_SUCCESS" 3 "SBC_AR_STOPPED" 2 "SBC_AR_RUNTOSTOP" 0 "SBC_AR_INIT" 1 "SBC_AR_RUNNING" ;
VAL_ 1613 sbcARTimerValue_SC14 255 "SNA" ;
VAL_ 1613 cmbVAIndex_SC14 255 "CMB_NONE" ;
VAL_ 1613 minVACMB_SC14 65535 "SNA" ;
VAL_ 1613 maxVACMB_SC14 65535 "SNA" ;
VAL_ 1613 pumpInternalFaultError_SC14 1 "ERROR" 0 "NO_ERROR" ;
VAL_ 1613 pumpShortCircuitError_SC14 1 "ERROR" 0 "NO_ERROR" ;
VAL_ 1613 pumpElectricError_SC14 1 "ERROR" 0 "NO_ERROR" 3 "SNA" ;
VAL_ 1613 pumpPostRunMode_SC14 7 "SNA" 4 "SPEED_4" 3 "SPEED_3" 2 "SPEED_2" 1 "SPEED_1" 0 "NO_POST_RUN" ;
VAL_ 1613 pumpRsError_SC14 1 "ERROR" 0 "NO_ERROR" ;
VAL_ 1613 pumpWakeUpStatus_SC14 2 "NDEF2" 1 "ACTIVE_WUP" 0 "NO_WUP" 3 "SNA" ;
VAL_ 1613 pumpRpmMonStat_SC14 1 "NO_MON" 0 "MON_ACTIVE" 3 "SNA" ;
VAL_ 1613 pumpPwmInStat_SC14 1 "HIGH" 0 "LOW" 3 "SNA" ;
VAL_ 1613 pumpDiagTriggered_SC14 1 "TRUE" 0 "FALSE" ;
VAL_ 1613 pumpHwFault_SC14 1 "ERROR" 0 "NO_ERROR" ;
VAL_ 1613 pumpPumpState_SC14 6 "ERROR" 5 "HARDWARE_ERROR" 1 "RUN" 0 "IDLE" 7 "SNA" ;
VAL_ 1613 pumpBlockError_SC14 0 "NO_ERROR" 1 "ERROR" 3 "SNA" ;
VAL_ 1613 pumpLinError_SC14 1 "ERROR" 0 "NO_ERROR" ;
VAL_ 1613 pumpDryRun_SC14 1 "ERROR" 0 "NO_ERROR" 3 "SNA" ;
VAL_ 1613 pumpOverCurrent_SC14 1 "ERROR" 0 "NO_ERROR" 3 "SNA" ;
VAL_ 1613 pumpVoltageDeratingError_SC14 1 "ERROR" 0 "NO_ERROR" ;
VAL_ 1613 pumpSupVoltageError_SC14 1 "ERROR" 0 "NO_ERROR" 3 "SNA" ;
VAL_ 1613 pumpUnderVoltage_SC14 1 "ERROR" 0 "NO_ERROR" ;
VAL_ 1613 pumpOverVoltage_SC14 1 "ERROR" 0 "NO_ERROR" ;
VAL_ 1613 pumpTempProtect_SC14 1 "ERROR" 0 "NO_ERROR" ;
VAL_ 1613 pumpOverTempDeratingErr_SC14 1 "ERROR" 0 "NO_ERROR" ;
VAL_ 1613 pumpOverTemperature_SC14 1 "ERROR" 0 "NO_ERROR" 3 "SNA" ;
VAL_ 1613 pressure2_SC14 255 "SNA" ;
VAL_ 1613 cmbSM29ScoutTempIndex_SC14 255 "SNA" ;
VAL_ 1613 cmbSM19ScoutPDO_SC14 65535 "SNA" ;
VAL_ 1613 isolationResInternRelaxed_SC14 65535 "SNA" ;
VAL_ 1613 appTask500HzMaxAvg_SC14 255 "SNA" ;
VAL_ 1613 safetyHangLastLinkReg_SC14 -1 "SNA" ;
VAL_ 1613 safetyHangPresentLinkReg_SC14 -1 "SNA" ;
VAL_ 1613 safetyHangDataFaultStatus_SC14 -1 "SNA" ;
VAL_ 1613 safetyHangDataFaultAddr_SC14 -1 "SNA" ;
VAL_ 1613 safetyHangLastARMMode_SC14 255 "MODE_UNKNOWN" 6 "MODE_SYS" 5 "MODE_UND" 4 "MODE_ABT" 3 "MODE_SVC" 2 "MODE_IRQ" 1 "MODE_FIQ" 0 "MODE_USER" ;
VAL_ 1613 safetyHangPresARMMode_SC14 255 "MODE_UNKNOWN" 6 "MODE_SYS" 5 "MODE_UND" 4 "MODE_ABT" 3 "MODE_SVC" 2 "MODE_IRQ" 1 "MODE_FIQ" 0 "MODE_USER" ;
VAL_ 1613 safetyHangESMGrp3Reg_SC14 -1 "SNA" ;
VAL_ 1613 safetyHangInstrFaultStatus_SC14 -1 "SNA" ;
VAL_ 1613 safetyHangInstrFaultAddr_SC14 -1 "SNA" ;
VAL_ 1613 pressure_SC14 255 "SNA" ;
VAL_ 1613 cmbMaxSM33Diff_SC14 255 "SNA" ;
VAL_ 1613 cmbMinSM29Diff_SC14 255 "SNA" ;
VAL_ 1613 cmbMinSM4Diff_SC14 65535 "SNA" ;
VAL_ 1613 cmbMaxSM4Diff_SC14 65535 "SNA" ;
VAL_ 1613 cmbMinSM27Diff_SC14 65535 "SNA" ;
VAL_ 1613 cmbMaxSM27Diff_SC14 65535 "SNA" ;
VAL_ 1613 adcDriverFail_SC14 12 "ADCDRIVER_SBCSUPPLY_FF" 11 "ADCDRIVER_MUX960_FF" 10 "ADCDRIVER_MUX910_FF" 9 "ADCDRIVER_UNDEF" 8 "ADCDRIVER_ADCVAR" 7 "ADCDRIVER_SLEEP_FF" 6 "ADCDRIVER_PYRO_FF" 5 "ADCDRIVER_MUX710_FF" 4 "ADCDRIVER_MUX440_FF" 3 "ADCDRIVER_MUX302A_FF" 2 "ADCDRIVER_MUX301B_FF" 1 "ADCDRIVER_MUX301A_FF" 0 "ADCDRIVER_NO_ISSUE" ;
VAL_ 1613 mainUcHvilState_SC14 2 "CANTX_HVIL_CLOSE" 3 "CANTX_HVIL_SNA" 1 "CANTX_HVIL_OPEN" 0 "CANTX_HVIL_NOT_AVAIL" ;
VAL_ 1613 mainUcIntIsoErr_SC14 3 "ISOLATION_SNA" 2 "ISOLATION_ERR_OFF" 1 "ISOLATION_ERROR" 0 "ISOLATION_OK" ;
VAL_ 1613 mainUcExtIsoErr_SC14 3 "ISOLATION_SNA" 2 "ISOLATION_ERR_OFF" 1 "ISOLATION_ERROR" 0 "ISOLATION_OK" ;
VAL_ 1613 safetyUcThermalStatus_SC14 3 "THERMALEVENT_SNA" 2 "THERMALEVENT_WARN_2" 1 "THERMALEVENT_WARN_1" 0 "THERMALEVENT_NO_WARN" ;
VAL_ 1613 mainUcThermalStatus_SC14 3 "THERMALEVENT_SNA" 2 "THERMALEVENT_WARN_2" 1 "THERMALEVENT_WARN_1" 0 "THERMALEVENT_NO_WARN" ;
VAL_ 1613 selfTestDataFaultStatus_SC14 -1 "SNA" ;
VAL_ 1613 selfTestInstrFaultAddr_SC14 -1 "SNA" ;
VAL_ 1613 selfTestDataFaultAddr_SC14 -1 "SNA" ;
VAL_ 1613 selfTestInstrFaultStatus_SC14 -1 "SNA" ;
VAL_ 1613 internalIsolationError_SC14 3 "ISOLATION_SNA" 2 "ISOLATION_ERR_OFF" 1 "ISOLATION_ERROR" 0 "ISOLATION_OK" ;
VAL_ 1613 externalIsolationError_SC14 3 "ISOLATION_SNA" 2 "ISOLATION_ERR_OFF" 1 "ISOLATION_ERROR" 0 "ISOLATION_OK" ;
VAL_ 1613 isolationTestState_SC14 3 "ISOLATION_TEST_POSNEG" 2 "ISOLATION_TEST_NEG" 1 "ISOLATION_TEST_POS" 0 "ISOLATION_OFF" ;
VAL_ 1613 isolationResistanceIntern_SC14 65535 "SNA" ;
VAL_ 1613 isolationResistanceExtern_SC14 65535 "SNA" ;
VAL_ 1613 maxAdolV13Diff_SC14 65535 "SNA" ;
VAL_ 1613 pumpType_SC14 0 "PUMP_NONE" 1 "PUMP_MAL" 2 "PUMP_BOSCH" 3 "PUMP_JOMA" 4 "PUMP_MAHLE" 255 "SNA" ;
VAL_ 1613 pumpPhaseCurrent_SC14 255 "SNA" ;
VAL_ 1613 hvWithstandTestQual_SC14 1 "QUAL_ERROR" 0 "QUAL_VALID" ;
VAL_ 1613 currentModuleMax_SC14 65535 "SNA" ;
VAL_ 1613 currentModuleMin_SC14 65535 "SNA" ;
VAL_ 1613 maxCMBDieTemp_SC14 255 "SNA" ;
VAL_ 1613 minCMBDieTemp_SC14 255 "SNA" ;
VAL_ 1613 appTaskSpiRxTx_SC14 255 "SNA" ;
VAL_ 1613 variantCodingCounts_SC14 255 "SNA" ;
VAL_ 1613 cmbMaxUpdateTime_SC14 255 "SNA" ;
VAL_ 1613 pumpSetSpeed_SC14 255 "SNA" ;
VAL_ 1613 hvilResistance_SC14 255 "SNA" ;
VAL_ 1613 cmbAvgUpdateTime_SC14 255 "SNA" ;
VAL_ 1613 pumpTemperature_SC14 255 "SNA" ;
VAL_ 1613 pumpSpeed_SC14 255 "SNA" ;
VAL_ 1613 pumpVoltage_SC14 255 "SNA" ;
VAL_ 1613 pumpCurrent_SC14 255 "SNA" ;
VAL_ 1613 posLink3_SC14 65535 "SNA" ;
VAL_ 1613 negLink3_SC14 65535 "SNA" ;
VAL_ 1613 posLink2_SC14 65535 "SNA" ;
VAL_ 1613 negLink2_SC14 65535 "SNA" ;
VAL_ 1613 cmbNrOfSamples_SC14 65535 "SNA" ;
VAL_ 1613 cmbTaskTime_SC14 65535 "SNA" ;
VAL_ 1613 appTask500HzMax_SC14 255 "SNA" ;
VAL_ 1613 analogHallSense_SC14 65535 "SNA" ;
VAL_ 1613 cmbMaxDiagStepPeriodicity_SC14 255 "SNA" ;
VAL_ 1613 minBrickVoltageLimit_SC14 65535 "SNA" ;
VAL_ 1613 appTask100Hz_SC14 255 "SNA" ;
VAL_ 1613 appTask10Hz_SC14 255 "SNA" ;
VAL_ 1613 appTaskAnalog_SC14 255 "SNA" ;
VAL_ 1613 appTaskADC_SC14 255 "SNA" ;
VAL_ 1613 appTask500HzAvg_SC14 255 "SNA" ;
VAL_ 1613 appTaskSBC_SC14 255 "SNA" ;
VAL_ 1613 appTaskCMBDriver_SC14 255 "SNA" ;
VAL_ 1613 safetyInitTime_SC14 255 "SNA" ;
VAL_ 1613 debugSlowMpex_SC14 45 "S45" 44 "S44" 43 "S43" 42 "S42" 41 "S41" 0 "S00" 1 "S01" 2 "S02" 3 "S03" 4 "S04" 5 "S05" 6 "S06" 7 "S07" 8 "S08" 9 "S09" 10 "S10" 11 "S11" 12 "S12" 13 "S13" 14 "S14" 15 "S15" 16 "S16" 17 "S17" 18 "S18" 19 "S19" 20 "S20" 21 "S21" 22 "S22" 23 "S23" 24 "S24" 25 "S25" 26 "S26" 27 "S27" 28 "S28" 29 "S29" 30 "S30" 31 "S31" 32 "S32" 33 "S33" 34 "S34" 35 "S35" 36 "S36" 37 "S37" 38 "S38" 39 "S39" 40 "S40" ;
VAL_ 1613 mux440Gnd_SC14 255 "SNA" ;
VAL_ 1613 analogHallGain_SC14 65535 "SNA" ;
VAL_ 1613 analogHallOffset_SC14 255 "SNA" ;
VAL_ 1613 negPackPrime_SC14 65535 "SNA" ;
VAL_ 1613 posPackPrime_SC14 65535 "SNA" ;
VAL_ 1613 packVoltage_SC14 65535 "SNA" ;
VAL_ 1613 sleepTime_SC14 65535 "SNA" ;
VAL_ 1613 analogNegHVOffset_SC14 255 "SNA" ;
VAL_ 1613 analogPosHVOffset_SC14 255 "SNA" ;
VAL_ 1613 analogNegHVGain_SC14 65535 "SNA" ;
VAL_ 1613 analogPosHVGain_SC14 65535 "SNA" ;
VAL_ 1613 mux910Gnd_SC14 255 "SNA" ;
VAL_ 1613 mux960Gnd_SC14 255 "SNA" ;
VAL_ 1613 analogAddr5_SC14 65535 "SNA" ;
VAL_ 1613 analogAddr4_SC14 65535 "SNA" ;
VAL_ 1613 analogAddr3_SC14 65535 "SNA" ;
VAL_ 1613 analogAddr2_SC14 65535 "SNA" ;
VAL_ 1613 analogAddr1_SC14 65535 "SNA" ;
VAL_ 1613 analogAddr0_SC14 65535 "SNA" ;
VAL_ 1613 sbcVREF2P5_SC14 255 "SNA" ;
VAL_ 1613 mux910N3VRef_SC14 65535 "SNA" ;
VAL_ 1613 mux910P2P5VRef_SC14 65535 "SNA" ;
VAL_ 1613 analogHvilCurrentPWM_SC14 255 "SNA" ;
VAL_ 1613 analogSBCSupply_SC14 255 "SNA" ;
VAL_ 1613 analogHvilCurrent_SC14 255 "SNA" ;
VAL_ 1613 analogPressureSense_SC14 255 "SNA" ;
VAL_ 1613 analog5VSensorSupply_SC14 255 "SNA" ;
VAL_ 1613 analogPrechgRel2CoilMinus_SC14 255 "SNA" ;
VAL_ 1613 analogPrechgRel1CoilMinus_SC14 255 "SNA" ;
VAL_ 1613 analogNegCntr3CoilMinus_SC14 255 "SNA" ;
VAL_ 1613 analogNegCntr2CoilMinus_SC14 255 "SNA" ;
VAL_ 1613 analogNegCntr1CoilMinus_SC14 255 "SNA" ;
VAL_ 1613 analogPosCntr3CoilMinus_SC14 255 "SNA" ;
VAL_ 1613 analogPosCntr2CoilMinus_SC14 255 "SNA" ;
VAL_ 1613 analogPosCntr1CoilMinus_SC14 255 "SNA" ;
VAL_ 1613 minModuleTemperature_SC14 255 "SNA" ;
VAL_ 1613 maxModuleTemperature_SC14 255 "SNA" ;
VAL_ 1613 analogHvilReturn_SC14 255 "SNA" ;
VAL_ 1613 analog5VDSupply_SC14 255 "SNA" ;
VAL_ 1613 analogHvilOut_SC14 255 "SNA" ;
VAL_ 1613 analogCurrentSensor12V_SC14 255 "SNA" ;
VAL_ 1613 maxVREF2_SC14 65535 "SNA" ;
VAL_ 1613 minVREF2_SC14 65535 "SNA" ;
VAL_ 1613 hallCurrentOffset_SC14 65535 "SNA" ;
VAL_ 1613 sumOfCurrentsFiltered_SC14 65535 "SNA" ;
VAL_ 1613 hallCurrentAveraged_SC14 65535 "SNA" ;
VAL_ 1613 analogHallSupply_SC14 65535 "SNA" ;
VAL_ 1613 contactorControlPos1_SC14 4 "CTRCTRL_CTRFAIL" 3 "CTRCTRL_CTRON" 2 "CTRCTRL_CTRCHECK" 1 "CTRCTRL_ADDITIONAL_CTRCHECK" 0 "CTRCTRL_CTROFF" ;
VAL_ 1613 contactorControlNeg1_SC14 4 "CTRCTRL_CTRFAIL" 3 "CTRCTRL_CTRON" 2 "CTRCTRL_CTRCHECK" 1 "CTRCTRL_ADDITIONAL_CTRCHECK" 0 "CTRCTRL_CTROFF" ;
VAL_ 1613 contactorControlPre1_SC14 4 "CTRCTRL_CTRFAIL" 3 "CTRCTRL_CTRON" 2 "CTRCTRL_CTRCHECK" 1 "CTRCTRL_ADDITIONAL_CTRCHECK" 0 "CTRCTRL_CTROFF" ;
VAL_ 1613 contactorControlPos2_SC14 4 "CTRCTRL_CTRFAIL" 3 "CTRCTRL_CTRON" 2 "CTRCTRL_CTRCHECK" 1 "CTRCTRL_ADDITIONAL_CTRCHECK" 0 "CTRCTRL_CTROFF" ;
VAL_ 1613 contactorControlNeg2_SC14 4 "CTRCTRL_CTRFAIL" 3 "CTRCTRL_CTRON" 2 "CTRCTRL_CTRCHECK" 1 "CTRCTRL_ADDITIONAL_CTRCHECK" 0 "CTRCTRL_CTROFF" ;
VAL_ 1613 contactorControlPre2_SC14 4 "CTRCTRL_CTRFAIL" 3 "CTRCTRL_CTRON" 2 "CTRCTRL_CTRCHECK" 1 "CTRCTRL_ADDITIONAL_CTRCHECK" 0 "CTRCTRL_CTROFF" ;
VAL_ 1613 contactorControlPos3_SC14 4 "CTRCTRL_CTRFAIL" 3 "CTRCTRL_CTRON" 2 "CTRCTRL_CTRCHECK" 1 "CTRCTRL_ADDITIONAL_CTRCHECK" 0 "CTRCTRL_CTROFF" ;
VAL_ 1613 contactorControlNeg3_SC14 4 "CTRCTRL_CTRFAIL" 3 "CTRCTRL_CTRON" 2 "CTRCTRL_CTRCHECK" 1 "CTRCTRL_ADDITIONAL_CTRCHECK" 0 "CTRCTRL_CTROFF" ;
VAL_ 1677 selfTestFaultCntrCtrl_SC14 4 "CTRCTRL_SELFTEST_NONE" 3 "CTRCTRL_SELFTEST_4" 2 "CTRCTRL_SELFTEST_3" 1 "CTRCTRL_SELFTEST_2" 0 "CTRCTRL_SELFTEST_1" ;
VAL_ 1677 cmbASICFault_SC14 20 "CMBDRIVER_ASIC_UNEXPECTED_MODULE" 19 "CMBDRIVER_ASIC_PEC_DIAGN_READ" 18 "CMBDRIVER_ASIC_PEC_DIAGN_DATA" 17 "CMBDRIVER_ASIC_PEC_DIAGN_CMD" 16 "CMBDRIVER_ASIC_REDUNDANT_FILTER" 15 "CMBDRIVER_ASIC_REDUNDANT_ADC" 14 "CMB_ASIC_CLOCK_LF" 13 "CMB_ASIC_CHARGE_PUMP_LF" 12 "CMB_ASIC_MUX_CHECK_LF" 11 "CMB_ASIC_INTERNAL_SUP_LF" 10 "CMB_ASIC_MUX_COMP_FAIL" 9 "CMB_ASIC_CHARGE_PUMP_FAIL" 8 "CMB_ASIC_OPEN_WIRE_CURR_FAIL" 255 "CMB_ASIC_FAULT_NONE" 7 "CMB_ASIC_VREF3_FAIL" 6 "CMB_ASIC_VREF2_FAIL" 5 "CMB_ASIC_ITEMP_FAIL" 4 "CMB_ASIC_VD_FAIL" 3 "CMB_ASIC_VA_FAIL" 2 "CMB_ASIC_TESTMODE" 1 "CMB_ASIC_CLOCK_FAIL" 0 "CMB_ASIC_MUX_FAIL" ;
VAL_ 1677 mainUcExtIsoResistance_SC14 65535 "SNA" ;
VAL_ 1677 BMS_C38_AR2MsgFault_SC14 3 "MSG_MISSING" 2 "MSG_SEQ_CNT_FAULT" 1 "MSG_CRC_FAULT" 0 "MSG_VALID" ;
VAL_ 1677 stateCoolant_SC14 1 "SAFESTATE_UNSAFE" 0 "SAFESTATE_SAFE" ;
VAL_ 1677 stateThermalEvent_SC14 1 "SAFESTATE_UNSAFE" 0 "SAFESTATE_SAFE" ;
VAL_ 1677 stateCANTx_SC14 1 "SAFESTATE_UNSAFE" 0 "SAFESTATE_SAFE" ;
VAL_ 1677 mainUcCntrCtrlReq_SC14 3 "SAFETYCAN_CNTR_CTRL_SNA" 1 "SAFETYCAN_CNTR_CTRL_CLS" 0 "SAFETYCAN_CNTR_CTRL_OPEN" ;
VAL_ 1677 mainUcCntrWeldState_SC14 7 "SAFETYCAN_WELD_HV_ALL_ERR" 6 "SAFETYCAN_WELD_HV_PLUS_MINUS_ERR" 15 "SAFETYCAN_WELD_SNA" 5 "SAFETYCAN_WELD_PRE_HV_MINUS_ERR" 4 "SAFETYCAN_WELD_HV_MINUS_ERR" 3 "SAFETYCAN_WELD_PRE_HV_PLUS_ERR" 2 "SAFETYCAN_WELD_HV_PLUS_ERR" 1 "SAFETYCAN_WELD_PRE_ERR" 0 "SAFETYCAN_WELD_NO_ERR" ;
VAL_ 1677 safetyUcCntrState_SC14 2 "SAFETYCAN_CNTR_CLS" 3 "SAFETYCAN_CNTR_SNA" 1 "SAFETYCAN_CNTR_PRECHRG" 0 "SAFETYCAN_CNTR_OPEN" ;
VAL_ 1677 mainUcCntrState_SC14 2 "SAFETYCAN_CNTR_CLS" 3 "SAFETYCAN_CNTR_SNA" 1 "SAFETYCAN_CNTR_PRECHRG" 0 "SAFETYCAN_CNTR_OPEN" ;
VAL_ 1677 safetyCANMsg4Fault_SC14 6 "SAFETYCAN_E2E_CRC" 15 "SAFETYCAN_SNA" 5 "SAFETYCAN_SPI_FAIL" 4 "SAFETYCAN_MSG_MISSING" 3 "SAFETYCAN_MSG_CNT_MISMATCH" 2 "SAFETYCAN_ALIVE_CNT" 1 "SAFETYCAN_SPI_CRC" 0 "SAFETYCAN_GOOD" ;
VAL_ 1677 safetyCANMsg3Fault_SC14 6 "SAFETYCAN_E2E_CRC" 15 "SAFETYCAN_SNA" 5 "SAFETYCAN_SPI_FAIL" 4 "SAFETYCAN_MSG_MISSING" 3 "SAFETYCAN_MSG_CNT_MISMATCH" 2 "SAFETYCAN_ALIVE_CNT" 1 "SAFETYCAN_SPI_CRC" 0 "SAFETYCAN_GOOD" ;
VAL_ 1677 safetyCANMsg2Fault_SC14 6 "SAFETYCAN_E2E_CRC" 15 "SAFETYCAN_SNA" 5 "SAFETYCAN_SPI_FAIL" 4 "SAFETYCAN_MSG_MISSING" 3 "SAFETYCAN_MSG_CNT_MISMATCH" 2 "SAFETYCAN_ALIVE_CNT" 1 "SAFETYCAN_SPI_CRC" 0 "SAFETYCAN_GOOD" ;
VAL_ 1677 safetyCANMsg1Fault_SC14 6 "SAFETYCAN_E2E_CRC" 15 "SAFETYCAN_SNA" 5 "SAFETYCAN_SPI_FAIL" 4 "SAFETYCAN_MSG_MISSING" 3 "SAFETYCAN_MSG_CNT_MISMATCH" 2 "SAFETYCAN_ALIVE_CNT" 1 "SAFETYCAN_SPI_CRC" 0 "SAFETYCAN_GOOD" ;
VAL_ 1677 contactorCntrSelfTest_SC14 9 "CTRCTRL_CHKLOSIDE_OPEN_CIRC" 8 "CTRCTRL_FAILED" 7 "CTRCTRL_PASSED" 6 "CTRCTRL_CHKHISIDE_STUCK_OPEN" 5 "CTRCTRL_CHK_CLOSE_OK_CIRCUIT" 4 "CTRCTRL_CHKLOSIDE_CTRL_OK" 3 "CTRCTRL_CHKLOSIDE_STUCK_CLOSED" 2 "CTRCTRL_CHKHISIDE_STUCK_CLOSED" 1 "CTRCTRL_PENDING" 0 "CTRCTRL_INIT" ;
VAL_ 1677 maxBrickVoltage_SC14 65535 "SNA" ;
VAL_ 1677 minBrickVoltage_SC14 65535 "SNA" ;
VAL_ 1677 cmbLastUpdateTime_SC14 255 "SNA" ;
VAL_ 1677 weldCheckState_SC14 4 "WELDCHECK_IDLE" 3 "WELDCHECK" 2 "WELDCHECK_ISO_2" 1 "WELDCHECK_ISO_1" 0 "WELDCHECK_INIT" ;
VAL_ 1677 debugFastMpex_SC14 0 "F00" 1 "F01" 2 "F02" 3 "F03" 4 "F04" 5 "F05" 6 "F06" 7 "F07" 8 "F08" 9 "F09" 10 "F10" 11 "F11" 12 "F12" 13 "F13" 14 "F14" 15 "F15" ;
VAL_ 1677 SPIRxTxTimeAllPckts_SC14 255 "SNA" ;
VAL_ 1677 stateContactorControl_SC14 1 "SAFESTATE_UNSAFE" 0 "SAFESTATE_SAFE" ;
VAL_ 1677 analogCntrPwrPlus_SC14 255 "SNA" ;
VAL_ 1677 weldedState_SC14 2 "CTR_WELD_SNA" 0 "CTR_NOTWELDED" 1 "CTR_ATLEASTONE_WELDED" ;
VAL_ 1677 stateVoltage_SC14 1 "SAFESTATE_UNSAFE" 0 "SAFESTATE_SAFE" ;
VAL_ 1677 stateTemperature_SC14 1 "SAFESTATE_UNSAFE" 0 "SAFESTATE_SAFE" ;
VAL_ 1677 stateSelfTest_SC14 1 "SAFESTATE_UNSAFE" 0 "SAFESTATE_SAFE" ;
VAL_ 1677 stateHVIL_SC14 1 "SAFESTATE_UNSAFE" 0 "SAFESTATE_SAFE" ;
VAL_ 1677 stateCurrent_SC14 1 "SAFESTATE_UNSAFE" 0 "SAFESTATE_SAFE" ;
VAL_ 1677 stateCrash2_SC14 1 "SAFESTATE_UNSAFE" 0 "SAFESTATE_SAFE" ;
VAL_ 1677 stateCrash1_SC14 1 "SAFESTATE_UNSAFE" 0 "SAFESTATE_SAFE" ;
VAL_ 1677 stateContactors_SC14 1 "SAFESTATE_UNSAFE" 0 "SAFESTATE_SAFE" ;
VAL_ 1677 stateCANRx_SC14 1 "SAFESTATE_UNSAFE" 0 "SAFESTATE_SAFE" ;
VAL_ 1677 itemState_SC14 15 "ITEM_INVALID" 2 "ITEM_EMERGENCY" 1 "ITEM_OFF" 0 "ITEM_ON" ;
VAL_ 1677 posPack_SC14 65535 "SNA" ;
VAL_ 1677 posLink_SC14 65535 "SNA" ;
VAL_ 1677 negPack_SC14 65535 "SNA" ;
VAL_ 1677 negLink_SC14 65535 "SNA" ;
VAL_ 1677 hallCurrent_SC14 4095 "SNA" ;
VAL_ 1677 analogCntrPwrPlusISense_SC14 255 "SNA" ;
VAL_ 1677 analogCntrPwrPlusSwitched_SC14 255 "SNA" ;
VAL_ 1933 cmbCoolantTemp08_BMS14 255 "SNA" ;
VAL_ 1933 cmbCoolantTemp07_BMS14 255 "SNA" ;
VAL_ 1933 cmbCoolantTemp06_BMS14 255 "SNA" ;
VAL_ 1933 cmbCoolantTemp05_BMS14 255 "SNA" ;
VAL_ 1933 cmbCoolantTemp04_BMS14 255 "SNA" ;
VAL_ 1933 cmbCoolantTemp03_BMS14 255 "SNA" ;
VAL_ 1933 cmbCoolantTemp02_BMS14 255 "SNA" ;
VAL_ 1933 cmbCoolantTemp01_BMS14 255 "SNA" ;
VAL_ 1933 cmbOnboardPressure32_BMS14 65535 "SNA" ;
VAL_ 1933 cmbOnboardPressure31_BMS14 65535 "SNA" ;
VAL_ 1933 cmbOnboardPressure30_BMS14 65535 "SNA" ;
VAL_ 1933 cmbOnboardPressure29_BMS14 65535 "SNA" ;
VAL_ 1933 cmbOnboardPressure28_BMS14 65535 "SNA" ;
VAL_ 1933 cmbOnboardPressure27_BMS14 65535 "SNA" ;
VAL_ 1933 cmbOnboardPressure26_BMS14 65535 "SNA" ;
VAL_ 1933 cmbOnboardPressure25_BMS14 65535 "SNA" ;
VAL_ 1933 cmbOnboardPressure24_BMS14 65535 "SNA" ;
VAL_ 1933 cmbOnboardPressure23_BMS14 65535 "SNA" ;
VAL_ 1933 cmbOnboardPressure22_BMS14 65535 "SNA" ;
VAL_ 1933 cmbOnboardPressure21_BMS14 65535 "SNA" ;
VAL_ 1933 cmbOnboardPressure20_BMS14 65535 "SNA" ;
VAL_ 1933 cmbOnboardPressure19_BMS14 65535 "SNA" ;
VAL_ 1933 cmbOnboardPressure18_BMS14 65535 "SNA" ;
VAL_ 1933 cmbOnboardPressure17_BMS14 65535 "SNA" ;
VAL_ 1933 cmbOnboardPressure16_BMS14 65535 "SNA" ;
VAL_ 1933 cmbOnboardPressure15_BMS14 65535 "SNA" ;
VAL_ 1933 cmbOnboardPressure14_BMS14 65535 "SNA" ;
VAL_ 1933 cmbOnboardPressure13_BMS14 65535 "SNA" ;
VAL_ 1933 cmbOnboardPressure12_BMS14 65535 "SNA" ;
VAL_ 1933 cmbOnboardPressure11_BMS14 65535 "SNA" ;
VAL_ 1933 cmbOnboardPressure10_BMS14 65535 "SNA" ;
VAL_ 1933 cmbOnboardPressure09_BMS14 65535 "SNA" ;
VAL_ 1933 cmbOnboardPressure08_BMS14 65535 "SNA" ;
VAL_ 1933 cmbOnboardPressure07_BMS14 65535 "SNA" ;
VAL_ 1933 cmbOnboardPressure06_BMS14 65535 "SNA" ;
VAL_ 1933 cmbOnboardPressure05_BMS14 65535 "SNA" ;
VAL_ 1933 cmbOnboardPressure04_BMS14 65535 "SNA" ;
VAL_ 1933 cmbOnboardPressure03_BMS14 65535 "SNA" ;
VAL_ 1933 cmbOnboardPressure02_BMS14 65535 "SNA" ;
VAL_ 1933 cmbOnboardPressure01_BMS14 65535 "SNA" ;
VAL_ 1933 onboardMultiplexor_BMS14 32 "O32" 31 "O31" 30 "O30" 29 "O29" 28 "O28" 27 "O27" 26 "O26" 25 "O25" 24 "O24" 23 "O23" 22 "O22" 21 "O21" 20 "O20" 19 "O19" 18 "O18" 17 "O17" 16 "O16" 15 "O15" 14 "O14" 13 "O13" 0 "O00" 1 "O01" 2 "O02" 3 "O03" 4 "O04" 5 "O05" 6 "O06" 7 "O07" 8 "O08" 9 "O09" 10 "O10" 11 "O11" 12 "O12" ;
VAL_ 1933 minCmbOnboardTemperature_BMS14 255 "SNA" ;
VAL_ 1933 minCmbOnboardHumidity_BMS14 255 "SNA" ;
VAL_ 1933 maxCmbOnboardTemperature_BMS14 255 "SNA" ;
VAL_ 1933 maxCmbOnboardHumidity_BMS14 255 "SNA" ;
VAL_ 1933 bmsOnboardTemperature_BMS14 255 "SNA" ;
VAL_ 1933 bmsOnboardHumidity_BMS14 255 "SNA" ;
VAL_ 1933 cmbOnboardTemperature01_BMS14 255 "SNA" ;
VAL_ 1933 cmbOnboardHumidity01_BMS14 255 "SNA" ;
VAL_ 1933 moduleHeaterCurrent01_BMS14 255 "SNA" ;
VAL_ 1933 cmbOnboardTemperature02_BMS14 255 "SNA" ;
VAL_ 1933 cmbOnboardHumidity02_BMS14 255 "SNA" ;
VAL_ 1933 moduleHeaterCurrent02_BMS14 255 "SNA" ;
VAL_ 1933 cmbOnboardTemperature03_BMS14 255 "SNA" ;
VAL_ 1933 cmbOnboardHumidity03_BMS14 255 "SNA" ;
VAL_ 1933 moduleHeaterCurrent03_BMS14 255 "SNA" ;
VAL_ 1933 cmbOnboardTemperature04_BMS14 255 "SNA" ;
VAL_ 1933 cmbOnboardHumidity04_BMS14 255 "SNA" ;
VAL_ 1933 moduleHeaterCurrent04_BMS14 255 "SNA" ;
VAL_ 1933 cmbOnboardTemperature05_BMS14 255 "SNA" ;
VAL_ 1933 cmbOnboardHumidity05_BMS14 255 "SNA" ;
VAL_ 1933 moduleHeaterCurrent05_BMS14 255 "SNA" ;
VAL_ 1933 cmbOnboardTemperature06_BMS14 255 "SNA" ;
VAL_ 1933 cmbOnboardHumidity06_BMS14 255 "SNA" ;
VAL_ 1933 moduleHeaterCurrent06_BMS14 255 "SNA" ;
VAL_ 1933 cmbOnboardTemperature07_BMS14 255 "SNA" ;
VAL_ 1933 cmbOnboardHumidity07_BMS14 255 "SNA" ;
VAL_ 1933 moduleHeaterCurrent07_BMS14 255 "SNA" ;
VAL_ 1933 cmbOnboardTemperature08_BMS14 255 "SNA" ;
VAL_ 1933 cmbOnboardHumidity08_BMS14 255 "SNA" ;
VAL_ 1933 moduleHeaterCurrent08_BMS14 255 "SNA" ;
VAL_ 1933 cmbOnboardTemperature09_BMS14 255 "SNA" ;
VAL_ 1933 cmbOnboardHumidity09_BMS14 255 "SNA" ;
VAL_ 1933 moduleHeaterCurrent09_BMS14 255 "SNA" ;
VAL_ 1933 cmbOnboardTemperature10_BMS14 255 "SNA" ;
VAL_ 1933 cmbOnboardHumidity10_BMS14 255 "SNA" ;
VAL_ 1933 moduleHeaterCurrent10_BMS14 255 "SNA" ;
VAL_ 1933 cmbOnboardTemperature11_BMS14 255 "SNA" ;
VAL_ 1933 cmbOnboardHumidity11_BMS14 255 "SNA" ;
VAL_ 1933 moduleHeaterCurrent11_BMS14 255 "SNA" ;
VAL_ 1933 cmbOnboardTemperature12_BMS14 255 "SNA" ;
VAL_ 1933 cmbOnboardHumidity12_BMS14 255 "SNA" ;
VAL_ 1933 moduleHeaterCurrent12_BMS14 255 "SNA" ;
VAL_ 1933 cmbOnboardTemperature13_BMS14 255 "SNA" ;
VAL_ 1933 cmbOnboardHumidity13_BMS14 255 "SNA" ;
VAL_ 1933 moduleHeaterCurrent13_BMS14 255 "SNA" ;
VAL_ 1933 cmbOnboardTemperature14_BMS14 255 "SNA" ;
VAL_ 1933 cmbOnboardHumidity14_BMS14 255 "SNA" ;
VAL_ 1933 moduleHeaterCurrent14_BMS14 255 "SNA" ;
VAL_ 1933 cmbOnboardTemperature15_BMS14 255 "SNA" ;
VAL_ 1933 cmbOnboardHumidity15_BMS14 255 "SNA" ;
VAL_ 1933 moduleHeaterCurrent15_BMS14 255 "SNA" ;
VAL_ 1933 cmbOnboardTemperature16_BMS14 255 "SNA" ;
VAL_ 1933 cmbOnboardHumidity16_BMS14 255 "SNA" ;
VAL_ 1933 moduleHeaterCurrent16_BMS14 255 "SNA" ;
VAL_ 1933 cmbOnboardTemperature17_BMS14 255 "SNA" ;
VAL_ 1933 cmbOnboardHumidity17_BMS14 255 "SNA" ;
VAL_ 1933 moduleHeaterCurrent17_BMS14 255 "SNA" ;
VAL_ 1933 cmbOnboardTemperature18_BMS14 255 "SNA" ;
VAL_ 1933 cmbOnboardHumidity18_BMS14 255 "SNA" ;
VAL_ 1933 moduleHeaterCurrent18_BMS14 255 "SNA" ;
VAL_ 1933 cmbOnboardTemperature19_BMS14 255 "SNA" ;
VAL_ 1933 cmbOnboardHumidity19_BMS14 255 "SNA" ;
VAL_ 1933 moduleHeaterCurrent19_BMS14 255 "SNA" ;
VAL_ 1933 cmbOnboardTemperature20_BMS14 255 "SNA" ;
VAL_ 1933 cmbOnboardHumidity20_BMS14 255 "SNA" ;
VAL_ 1933 moduleHeaterCurrent20_BMS14 255 "SNA" ;
VAL_ 1933 cmbOnboardTemperature21_BMS14 255 "SNA" ;
VAL_ 1933 cmbOnboardHumidity21_BMS14 255 "SNA" ;
VAL_ 1933 moduleHeaterCurrent21_BMS14 255 "SNA" ;
VAL_ 1933 cmbOnboardTemperature22_BMS14 255 "SNA" ;
VAL_ 1933 cmbOnboardHumidity22_BMS14 255 "SNA" ;
VAL_ 1933 moduleHeaterCurrent22_BMS14 255 "SNA" ;
VAL_ 1933 cmbOnboardTemperature23_BMS14 255 "SNA" ;
VAL_ 1933 cmbOnboardHumidity23_BMS14 255 "SNA" ;
VAL_ 1933 moduleHeaterCurrent23_BMS14 255 "SNA" ;
VAL_ 1933 cmbOnboardTemperature24_BMS14 255 "SNA" ;
VAL_ 1933 cmbOnboardHumidity24_BMS14 255 "SNA" ;
VAL_ 1933 moduleHeaterCurrent24_BMS14 255 "SNA" ;
VAL_ 1933 cmbOnboardTemperature25_BMS14 255 "SNA" ;
VAL_ 1933 cmbOnboardHumidity25_BMS14 255 "SNA" ;
VAL_ 1933 moduleHeaterCurrent25_BMS14 255 "SNA" ;
VAL_ 1933 cmbOnboardTemperature26_BMS14 255 "SNA" ;
VAL_ 1933 cmbOnboardHumidity26_BMS14 255 "SNA" ;
VAL_ 1933 moduleHeaterCurrent26_BMS14 255 "SNA" ;
VAL_ 1933 cmbOnboardTemperature27_BMS14 255 "SNA" ;
VAL_ 1933 cmbOnboardHumidity27_BMS14 255 "SNA" ;
VAL_ 1933 moduleHeaterCurrent27_BMS14 255 "SNA" ;
VAL_ 1933 cmbOnboardTemperature28_BMS14 255 "SNA" ;
VAL_ 1933 cmbOnboardHumidity28_BMS14 255 "SNA" ;
VAL_ 1933 moduleHeaterCurrent28_BMS14 255 "SNA" ;
VAL_ 1933 cmbOnboardTemperature29_BMS14 255 "SNA" ;
VAL_ 1933 cmbOnboardHumidity29_BMS14 255 "SNA" ;
VAL_ 1933 moduleHeaterCurrent29_BMS14 255 "SNA" ;
VAL_ 1933 cmbOnboardTemperature30_BMS14 255 "SNA" ;
VAL_ 1933 cmbOnboardHumidity30_BMS14 255 "SNA" ;
VAL_ 1933 moduleHeaterCurrent30_BMS14 255 "SNA" ;
VAL_ 1933 cmbOnboardTemperature31_BMS14 255 "SNA" ;
VAL_ 1933 cmbOnboardHumidity31_BMS14 255 "SNA" ;
VAL_ 1933 moduleHeaterCurrent31_BMS14 255 "SNA" ;
VAL_ 1933 cmbOnboardTemperature32_BMS14 255 "SNA" ;
VAL_ 1933 cmbOnboardHumidity32_BMS14 255 "SNA" ;
VAL_ 1933 moduleHeaterCurrent32_BMS14 255 "SNA" ;
VAL_ 1997 cmbMultiplexor_BMS14 0 "C000" 1 "C001" 2 "C002" 3 "C003" 4 "C004" 5 "C005" 6 "C006" 7 "C007" 8 "C008" 9 "C009" 10 "C010" 11 "C011" 12 "C012" 13 "C013" 14 "C014" 15 "C015" 16 "C016" 17 "C017" 18 "C018" 19 "C019" 20 "C020" 21 "C021" 22 "C022" 23 "C023" 24 "C024" 25 "C025" 26 "C026" 27 "C027" 28 "C028" 29 "C029" 30 "C030" 31 "C031" 32 "C032" 33 "C033" 34 "C034" 35 "C035" 36 "C036" 37 "C037" 38 "C038" 39 "C039" 40 "C040" 41 "C041" 42 "C042" 43 "C043" 44 "C044" 45 "C045" 46 "C046" 47 "C047" 48 "C048" 49 "C049" 50 "C050" 51 "C051" 52 "C052" 53 "C053" 54 "C054" 55 "C055" 56 "C056" 57 "C057" 58 "C058" 59 "C059" 60 "C060" 61 "C061" 62 "C062" 63 "C063" 64 "C064" 65 "C065" 66 "C066" 67 "C067" 68 "C068" 69 "C069" 70 "C070" 71 "C071" 72 "C072" 73 "C073" 74 "C074" 75 "C075" 76 "C076" 77 "C077" 78 "C078" 79 "C079" 80 "C080" 81 "C081" 82 "C082" 83 "C083" 84 "C084" 85 "C085" 86 "C086" 87 "C087" 88 "C088" 89 "C089" 90 "C090" 91 "C091" 92 "C092" 93 "C093" 94 "C094" 95 "C095" 96 "C096" 97 "C097" 98 "C098" 99 "C099" 100 "C100" 101 "C101" 102 "C102" 103 "C103" 104 "C104" 105 "C105" 106 "C106" 107 "C107" 108 "C108" 109 "C109" 110 "C110" 111 "C111" 112 "C112" 113 "C113" 114 "C114" 115 "C115" 116 "C116" 117 "C117" 118 "C118" 119 "C119" 120 "C120" 121 "C121" 122 "C122" 123 "C123" 124 "C124" 125 "C125" 126 "C126" 127 "C127" 128 "C128" 129 "C129" 130 "C130" 131 "C131" 132 "C132" 133 "C133" 134 "C134" 135 "C135" 136 "C136" 137 "C137" 138 "C138" 139 "C139" 140 "C140" 141 "C141" 142 "C142" 143 "C143" 144 "C144" 145 "C145" 146 "C146" 147 "C147" 148 "C148" 149 "C149" 150 "C150" 151 "C151" 152 "C152" 153 "C153" 154 "C154" 155 "C155" 156 "C156" 157 "C157" 158 "C158" 159 "C159" 160 "C160" 161 "C161" 162 "C162" 163 "C163" 164 "C164" 165 "C165" 166 "C166" 167 "C167" 168 "C168" 169 "C169" 170 "C170" 171 "C171" 172 "C172" 173 "C173" 174 "C174" 175 "C175" 176 "C176" 177 "C177" 178 "C178" 179 "C179" 180 "C180" 181 "C181" 182 "C182" 183 "C183" 184 "C184" 185 "C185" 186 "C186" 187 "C187" 188 "C188" 189 "C189" 190 "C190" 191 "C191" 192 "C192" ;
VAL_ 1997 moduleTemperature01_BMS14 255 "SNA" ;
VAL_ 1997 brickVoltage001_BMS14 65535 "SNA" ;
VAL_ 1997 brickVoltage002_BMS14 65535 "SNA" ;
VAL_ 1997 brickVoltage003_BMS14 65535 "SNA" ;
VAL_ 1997 moduleTemperature02_BMS14 255 "SNA" ;
VAL_ 1997 brickVoltage004_BMS14 65535 "SNA" ;
VAL_ 1997 brickVoltage005_BMS14 65535 "SNA" ;
VAL_ 1997 brickVoltage006_BMS14 65535 "SNA" ;
VAL_ 1997 moduleTemperature03_BMS14 255 "SNA" ;
VAL_ 1997 brickVoltage007_BMS14 65535 "SNA" ;
VAL_ 1997 brickVoltage008_BMS14 65535 "SNA" ;
VAL_ 1997 brickVoltage009_BMS14 65535 "SNA" ;
VAL_ 1997 moduleTemperature04_BMS14 255 "SNA" ;
VAL_ 1997 brickVoltage010_BMS14 65535 "SNA" ;
VAL_ 1997 brickVoltage011_BMS14 65535 "SNA" ;
VAL_ 1997 brickVoltage012_BMS14 65535 "SNA" ;
VAL_ 1997 moduleTemperature05_BMS14 255 "SNA" ;
VAL_ 1997 brickVoltage013_BMS14 65535 "SNA" ;
VAL_ 1997 brickVoltage014_BMS14 65535 "SNA" ;
VAL_ 1997 brickVoltage015_BMS14 65535 "SNA" ;
VAL_ 1997 moduleTemperature06_BMS14 255 "SNA" ;
VAL_ 1997 brickVoltage016_BMS14 65535 "SNA" ;
VAL_ 1997 brickVoltage017_BMS14 65535 "SNA" ;
VAL_ 1997 brickVoltage018_BMS14 65535 "SNA" ;
VAL_ 1997 moduleTemperature07_BMS14 255 "SNA" ;
VAL_ 1997 brickVoltage019_BMS14 65535 "SNA" ;
VAL_ 1997 brickVoltage020_BMS14 65535 "SNA" ;
VAL_ 1997 brickVoltage021_BMS14 65535 "SNA" ;
VAL_ 1997 moduleTemperature08_BMS14 255 "SNA" ;
VAL_ 1997 brickVoltage022_BMS14 65535 "SNA" ;
VAL_ 1997 brickVoltage023_BMS14 65535 "SNA" ;
VAL_ 1997 brickVoltage024_BMS14 65535 "SNA" ;
VAL_ 1997 moduleTemperature09_BMS14 255 "SNA" ;
VAL_ 1997 brickVoltage025_BMS14 65535 "SNA" ;
VAL_ 1997 brickVoltage026_BMS14 65535 "SNA" ;
VAL_ 1997 brickVoltage027_BMS14 65535 "SNA" ;
VAL_ 1997 moduleTemperature10_BMS14 255 "SNA" ;
VAL_ 1997 brickVoltage028_BMS14 65535 "SNA" ;
VAL_ 1997 brickVoltage029_BMS14 65535 "SNA" ;
VAL_ 1997 brickVoltage030_BMS14 65535 "SNA" ;
VAL_ 1997 moduleTemperature11_BMS14 255 "SNA" ;
VAL_ 1997 brickVoltage031_BMS14 65535 "SNA" ;
VAL_ 1997 brickVoltage032_BMS14 65535 "SNA" ;
VAL_ 1997 brickVoltage033_BMS14 65535 "SNA" ;
VAL_ 1997 moduleTemperature12_BMS14 255 "SNA" ;
VAL_ 1997 brickVoltage034_BMS14 65535 "SNA" ;
VAL_ 1997 brickVoltage035_BMS14 65535 "SNA" ;
VAL_ 1997 brickVoltage036_BMS14 65535 "SNA" ;
VAL_ 1997 moduleTemperature13_BMS14 255 "SNA" ;
VAL_ 1997 brickVoltage037_BMS14 65535 "SNA" ;
VAL_ 1997 brickVoltage038_BMS14 65535 "SNA" ;
VAL_ 1997 brickVoltage039_BMS14 65535 "SNA" ;
VAL_ 1997 moduleTemperature14_BMS14 255 "SNA" ;
VAL_ 1997 brickVoltage040_BMS14 65535 "SNA" ;
VAL_ 1997 brickVoltage041_BMS14 65535 "SNA" ;
VAL_ 1997 brickVoltage042_BMS14 65535 "SNA" ;
VAL_ 1997 moduleTemperature15_BMS14 255 "SNA" ;
VAL_ 1997 brickVoltage043_BMS14 65535 "SNA" ;
VAL_ 1997 brickVoltage044_BMS14 65535 "SNA" ;
VAL_ 1997 brickVoltage045_BMS14 65535 "SNA" ;
VAL_ 1997 moduleTemperature16_BMS14 255 "SNA" ;
VAL_ 1997 brickVoltage046_BMS14 65535 "SNA" ;
VAL_ 1997 brickVoltage047_BMS14 65535 "SNA" ;
VAL_ 1997 brickVoltage048_BMS14 65535 "SNA" ;
VAL_ 1997 moduleTemperature17_BMS14 255 "SNA" ;
VAL_ 1997 brickVoltage049_BMS14 65535 "SNA" ;
VAL_ 1997 brickVoltage050_BMS14 65535 "SNA" ;
VAL_ 1997 brickVoltage051_BMS14 65535 "SNA" ;
VAL_ 1997 moduleTemperature18_BMS14 255 "SNA" ;
VAL_ 1997 brickVoltage052_BMS14 65535 "SNA" ;
VAL_ 1997 brickVoltage053_BMS14 65535 "SNA" ;
VAL_ 1997 brickVoltage054_BMS14 65535 "SNA" ;
VAL_ 1997 moduleTemperature19_BMS14 255 "SNA" ;
VAL_ 1997 brickVoltage055_BMS14 65535 "SNA" ;
VAL_ 1997 brickVoltage056_BMS14 65535 "SNA" ;
VAL_ 1997 brickVoltage057_BMS14 65535 "SNA" ;
VAL_ 1997 moduleTemperature20_BMS14 255 "SNA" ;
VAL_ 1997 brickVoltage058_BMS14 65535 "SNA" ;
VAL_ 1997 brickVoltage059_BMS14 65535 "SNA" ;
VAL_ 1997 brickVoltage060_BMS14 65535 "SNA" ;
VAL_ 1997 moduleTemperature21_BMS14 255 "SNA" ;
VAL_ 1997 brickVoltage061_BMS14 65535 "SNA" ;
VAL_ 1997 brickVoltage062_BMS14 65535 "SNA" ;
VAL_ 1997 brickVoltage063_BMS14 65535 "SNA" ;
VAL_ 1997 moduleTemperature22_BMS14 255 "SNA" ;
VAL_ 1997 brickVoltage064_BMS14 65535 "SNA" ;
VAL_ 1997 brickVoltage065_BMS14 65535 "SNA" ;
VAL_ 1997 brickVoltage066_BMS14 65535 "SNA" ;
VAL_ 1997 moduleTemperature23_BMS14 255 "SNA" ;
VAL_ 1997 brickVoltage067_BMS14 65535 "SNA" ;
VAL_ 1997 brickVoltage068_BMS14 65535 "SNA" ;
VAL_ 1997 brickVoltage069_BMS14 65535 "SNA" ;
VAL_ 1997 moduleTemperature24_BMS14 255 "SNA" ;
VAL_ 1997 brickVoltage070_BMS14 65535 "SNA" ;
VAL_ 1997 brickVoltage071_BMS14 65535 "SNA" ;
VAL_ 1997 brickVoltage072_BMS14 65535 "SNA" ;
VAL_ 1997 moduleTemperature25_BMS14 255 "SNA" ;
VAL_ 1997 brickVoltage073_BMS14 65535 "SNA" ;
VAL_ 1997 brickVoltage074_BMS14 65535 "SNA" ;
VAL_ 1997 brickVoltage075_BMS14 65535 "SNA" ;
VAL_ 1997 moduleTemperature26_BMS14 255 "SNA" ;
VAL_ 1997 brickVoltage076_BMS14 65535 "SNA" ;
VAL_ 1997 brickVoltage077_BMS14 65535 "SNA" ;
VAL_ 1997 brickVoltage078_BMS14 65535 "SNA" ;
VAL_ 1997 moduleTemperature27_BMS14 255 "SNA" ;
VAL_ 1997 brickVoltage079_BMS14 65535 "SNA" ;
VAL_ 1997 brickVoltage080_BMS14 65535 "SNA" ;
VAL_ 1997 brickVoltage081_BMS14 65535 "SNA" ;
VAL_ 1997 moduleTemperature28_BMS14 255 "SNA" ;
VAL_ 1997 brickVoltage082_BMS14 65535 "SNA" ;
VAL_ 1997 brickVoltage083_BMS14 65535 "SNA" ;
VAL_ 1997 brickVoltage084_BMS14 65535 "SNA" ;
VAL_ 1997 moduleTemperature29_BMS14 255 "SNA" ;
VAL_ 1997 brickVoltage085_BMS14 65535 "SNA" ;
VAL_ 1997 brickVoltage086_BMS14 65535 "SNA" ;
VAL_ 1997 brickVoltage087_BMS14 65535 "SNA" ;
VAL_ 1997 moduleTemperature30_BMS14 255 "SNA" ;
VAL_ 1997 brickVoltage088_BMS14 65535 "SNA" ;
VAL_ 1997 brickVoltage089_BMS14 65535 "SNA" ;
VAL_ 1997 brickVoltage090_BMS14 65535 "SNA" ;
VAL_ 1997 moduleTemperature31_BMS14 255 "SNA" ;
VAL_ 1997 brickVoltage091_BMS14 65535 "SNA" ;
VAL_ 1997 brickVoltage092_BMS14 65535 "SNA" ;
VAL_ 1997 brickVoltage093_BMS14 65535 "SNA" ;
VAL_ 1997 moduleTemperature32_BMS14 255 "SNA" ;
VAL_ 1997 brickVoltage094_BMS14 65535 "SNA" ;
VAL_ 1997 brickVoltage095_BMS14 65535 "SNA" ;
VAL_ 1997 brickVoltage096_BMS14 65535 "SNA" ;
VAL_ 1997 brickVoltage097_BMS14 65535 "SNA" ;
VAL_ 1997 brickVoltage098_BMS14 65535 "SNA" ;
VAL_ 1997 brickVoltage099_BMS14 65535 "SNA" ;
VAL_ 1997 brickVoltage100_BMS14 65535 "SNA" ;
VAL_ 1997 brickVoltage101_BMS14 65535 "SNA" ;
VAL_ 1997 brickVoltage102_BMS14 65535 "SNA" ;
VAL_ 1997 brickVoltage103_BMS14 65535 "SNA" ;
VAL_ 1997 brickVoltage104_BMS14 65535 "SNA" ;
VAL_ 1997 brickVoltage105_BMS14 65535 "SNA" ;
VAL_ 1997 brickVoltage106_BMS14 65535 "SNA" ;
VAL_ 1997 brickVoltage107_BMS14 65535 "SNA" ;
VAL_ 1997 brickVoltage108_BMS14 65535 "SNA" ;
VAL_ 1997 brickVoltage109_BMS14 65535 "SNA" ;
VAL_ 1997 brickVoltage110_BMS14 65535 "SNA" ;
VAL_ 1997 brickVoltage111_BMS14 65535 "SNA" ;
VAL_ 1997 brickVoltage112_BMS14 65535 "SNA" ;
VAL_ 1997 brickVoltage113_BMS14 65535 "SNA" ;
VAL_ 1997 brickVoltage114_BMS14 65535 "SNA" ;
VAL_ 1997 brickVoltage115_BMS14 65535 "SNA" ;
VAL_ 1997 brickVoltage116_BMS14 65535 "SNA" ;
VAL_ 1997 brickVoltage117_BMS14 65535 "SNA" ;
VAL_ 1997 brickVoltage118_BMS14 65535 "SNA" ;
VAL_ 1997 brickVoltage119_BMS14 65535 "SNA" ;
VAL_ 1997 brickVoltage120_BMS14 65535 "SNA" ;
VAL_ 1997 brickVoltage121_BMS14 65535 "SNA" ;
VAL_ 1997 brickVoltage122_BMS14 65535 "SNA" ;
VAL_ 1997 brickVoltage123_BMS14 65535 "SNA" ;
VAL_ 1997 brickVoltage124_BMS14 65535 "SNA" ;
VAL_ 1997 brickVoltage125_BMS14 65535 "SNA" ;
VAL_ 1997 brickVoltage126_BMS14 65535 "SNA" ;
VAL_ 1997 brickVoltage127_BMS14 65535 "SNA" ;
VAL_ 1997 brickVoltage128_BMS14 65535 "SNA" ;
VAL_ 1997 brickVoltage129_BMS14 65535 "SNA" ;
VAL_ 1997 brickVoltage130_BMS14 65535 "SNA" ;
VAL_ 1997 brickVoltage131_BMS14 65535 "SNA" ;
VAL_ 1997 brickVoltage132_BMS14 65535 "SNA" ;
VAL_ 1997 brickVoltage133_BMS14 65535 "SNA" ;
VAL_ 1997 brickVoltage134_BMS14 65535 "SNA" ;
VAL_ 1997 brickVoltage135_BMS14 65535 "SNA" ;
VAL_ 1997 brickVoltage136_BMS14 65535 "SNA" ;
VAL_ 1997 brickVoltage137_BMS14 65535 "SNA" ;
VAL_ 1997 brickVoltage138_BMS14 65535 "SNA" ;
VAL_ 1997 brickVoltage139_BMS14 65535 "SNA" ;
VAL_ 1997 brickVoltage140_BMS14 65535 "SNA" ;
VAL_ 1997 brickVoltage141_BMS14 65535 "SNA" ;
VAL_ 1997 brickVoltage142_BMS14 65535 "SNA" ;
VAL_ 1997 brickVoltage143_BMS14 65535 "SNA" ;
VAL_ 1997 brickVoltage144_BMS14 65535 "SNA" ;
VAL_ 1997 brickVoltage145_BMS14 65535 "SNA" ;
VAL_ 1997 brickVoltage146_BMS14 65535 "SNA" ;
VAL_ 1997 brickVoltage147_BMS14 65535 "SNA" ;
VAL_ 1997 brickVoltage148_BMS14 65535 "SNA" ;
VAL_ 1997 brickVoltage149_BMS14 65535 "SNA" ;
VAL_ 1997 brickVoltage150_BMS14 65535 "SNA" ;
VAL_ 1997 brickVoltage151_BMS14 65535 "SNA" ;
VAL_ 1997 brickVoltage152_BMS14 65535 "SNA" ;
VAL_ 1997 brickVoltage153_BMS14 65535 "SNA" ;
VAL_ 1997 brickVoltage154_BMS14 65535 "SNA" ;
VAL_ 1997 brickVoltage155_BMS14 65535 "SNA" ;
VAL_ 1997 brickVoltage156_BMS14 65535 "SNA" ;
VAL_ 1997 brickVoltage157_BMS14 65535 "SNA" ;
VAL_ 1997 brickVoltage158_BMS14 65535 "SNA" ;
VAL_ 1997 brickVoltage159_BMS14 65535 "SNA" ;
VAL_ 1997 brickVoltage160_BMS14 65535 "SNA" ;
VAL_ 1997 brickVoltage161_BMS14 65535 "SNA" ;
VAL_ 1997 brickVoltage162_BMS14 65535 "SNA" ;
VAL_ 1997 brickVoltage163_BMS14 65535 "SNA" ;
VAL_ 1997 brickVoltage164_BMS14 65535 "SNA" ;
VAL_ 1997 brickVoltage165_BMS14 65535 "SNA" ;
VAL_ 1997 brickVoltage166_BMS14 65535 "SNA" ;
VAL_ 1997 brickVoltage167_BMS14 65535 "SNA" ;
VAL_ 1997 brickVoltage168_BMS14 65535 "SNA" ;
VAL_ 1997 brickVoltage169_BMS14 65535 "SNA" ;
VAL_ 1997 brickVoltage170_BMS14 65535 "SNA" ;
VAL_ 1997 brickVoltage171_BMS14 65535 "SNA" ;
VAL_ 1997 brickVoltage172_BMS14 65535 "SNA" ;
VAL_ 1997 brickVoltage173_BMS14 65535 "SNA" ;
VAL_ 1997 brickVoltage174_BMS14 65535 "SNA" ;
VAL_ 1997 brickVoltage175_BMS14 65535 "SNA" ;
VAL_ 1997 brickVoltage176_BMS14 65535 "SNA" ;
VAL_ 1997 brickVoltage177_BMS14 65535 "SNA" ;
VAL_ 1997 brickVoltage178_BMS14 65535 "SNA" ;
VAL_ 1997 brickVoltage179_BMS14 65535 "SNA" ;
VAL_ 1997 brickVoltage180_BMS14 65535 "SNA" ;
VAL_ 1997 brickVoltage181_BMS14 65535 "SNA" ;
VAL_ 1997 brickVoltage182_BMS14 65535 "SNA" ;
VAL_ 1997 brickVoltage183_BMS14 65535 "SNA" ;
VAL_ 1997 brickVoltage184_BMS14 65535 "SNA" ;
VAL_ 1997 brickVoltage185_BMS14 65535 "SNA" ;
VAL_ 1997 brickVoltage186_BMS14 65535 "SNA" ;
VAL_ 1997 brickVoltage187_BMS14 65535 "SNA" ;
VAL_ 1997 brickVoltage188_BMS14 65535 "SNA" ;
VAL_ 1997 brickVoltage189_BMS14 65535 "SNA" ;
VAL_ 1997 brickVoltage190_BMS14 65535 "SNA" ;
VAL_ 1997 brickVoltage191_BMS14 65535 "SNA" ;
VAL_ 1997 brickVoltage192_BMS14 65535 "SNA" ;
VAL_ 1997 brickVoltage193_BMS14 65535 "SNA" ;
VAL_ 1997 brickVoltage194_BMS14 65535 "SNA" ;
VAL_ 1997 brickVoltage195_BMS14 65535 "SNA" ;
VAL_ 1997 brickVoltage196_BMS14 65535 "SNA" ;
VAL_ 1997 brickVoltage197_BMS14 65535 "SNA" ;
VAL_ 1997 brickVoltage198_BMS14 65535 "SNA" ;
VAL_ 1997 brickVoltage199_BMS14 65535 "SNA" ;
VAL_ 1997 brickVoltage200_BMS14 65535 "SNA" ;
VAL_ 1997 brickVoltage201_BMS14 65535 "SNA" ;
VAL_ 1997 brickVoltage202_BMS14 65535 "SNA" ;
VAL_ 1997 brickVoltage203_BMS14 65535 "SNA" ;
VAL_ 1997 brickVoltage204_BMS14 65535 "SNA" ;
VAL_ 1997 brickVoltage205_BMS14 65535 "SNA" ;
VAL_ 1997 brickVoltage206_BMS14 65535 "SNA" ;
VAL_ 1997 brickVoltage207_BMS14 65535 "SNA" ;
VAL_ 1997 brickVoltage208_BMS14 65535 "SNA" ;
VAL_ 1997 brickVoltage209_BMS14 65535 "SNA" ;
VAL_ 1997 brickVoltage210_BMS14 65535 "SNA" ;
VAL_ 1997 brickVoltage211_BMS14 65535 "SNA" ;
VAL_ 1997 brickVoltage212_BMS14 65535 "SNA" ;
VAL_ 1997 brickVoltage213_BMS14 65535 "SNA" ;
VAL_ 1997 brickVoltage214_BMS14 65535 "SNA" ;
VAL_ 1997 brickVoltage215_BMS14 65535 "SNA" ;
VAL_ 1997 brickVoltage216_BMS14 65535 "SNA" ;
VAL_ 1997 brickVoltage217_BMS14 65535 "SNA" ;
VAL_ 1997 brickVoltage218_BMS14 65535 "SNA" ;
VAL_ 1997 brickVoltage219_BMS14 65535 "SNA" ;
VAL_ 1997 brickVoltage220_BMS14 65535 "SNA" ;
VAL_ 1997 brickVoltage221_BMS14 65535 "SNA" ;
VAL_ 1997 brickVoltage222_BMS14 65535 "SNA" ;
VAL_ 1997 brickVoltage223_BMS14 65535 "SNA" ;
VAL_ 1997 brickVoltage224_BMS14 65535 "SNA" ;
VAL_ 1997 brickVoltage225_BMS14 65535 "SNA" ;
VAL_ 1997 brickVoltage226_BMS14 65535 "SNA" ;
VAL_ 1997 brickVoltage227_BMS14 65535 "SNA" ;
VAL_ 1997 brickVoltage228_BMS14 65535 "SNA" ;
VAL_ 1997 brickVoltage229_BMS14 65535 "SNA" ;
VAL_ 1997 brickVoltage230_BMS14 65535 "SNA" ;
VAL_ 1997 brickVoltage231_BMS14 65535 "SNA" ;
VAL_ 1997 brickVoltage232_BMS14 65535 "SNA" ;
VAL_ 1997 brickVoltage233_BMS14 65535 "SNA" ;
VAL_ 1997 brickVoltage234_BMS14 65535 "SNA" ;
VAL_ 1997 brickVoltage235_BMS14 65535 "SNA" ;
VAL_ 1997 brickVoltage236_BMS14 65535 "SNA" ;
VAL_ 1997 brickVoltage237_BMS14 65535 "SNA" ;
VAL_ 1997 brickVoltage238_BMS14 65535 "SNA" ;
VAL_ 1997 brickVoltage239_BMS14 65535 "SNA" ;
VAL_ 1997 brickVoltage240_BMS14 65535 "SNA" ;
VAL_ 1997 brickVoltage241_BMS14 65535 "SNA" ;
VAL_ 1997 brickVoltage242_BMS14 65535 "SNA" ;
VAL_ 1997 brickVoltage243_BMS14 65535 "SNA" ;
VAL_ 1997 brickVoltage244_BMS14 65535 "SNA" ;
VAL_ 1997 brickVoltage245_BMS14 65535 "SNA" ;
VAL_ 1997 brickVoltage246_BMS14 65535 "SNA" ;
VAL_ 1997 brickVoltage247_BMS14 65535 "SNA" ;
VAL_ 1997 brickVoltage248_BMS14 65535 "SNA" ;
VAL_ 1997 brickVoltage249_BMS14 65535 "SNA" ;
VAL_ 1997 brickVoltage250_BMS14 65535 "SNA" ;
VAL_ 1997 brickVoltage251_BMS14 65535 "SNA" ;
VAL_ 1997 brickVoltage252_BMS14 65535 "SNA" ;
VAL_ 1997 brickVoltage253_BMS14 65535 "SNA" ;
VAL_ 1997 brickVoltage254_BMS14 65535 "SNA" ;
VAL_ 1997 brickVoltage255_BMS14 65535 "SNA" ;
VAL_ 1997 brickVoltage256_BMS14 65535 "SNA" ;
VAL_ 1997 brickVoltage257_BMS14 65535 "SNA" ;
VAL_ 1997 brickVoltage258_BMS14 65535 "SNA" ;
VAL_ 1997 brickVoltage259_BMS14 65535 "SNA" ;
VAL_ 1997 brickVoltage260_BMS14 65535 "SNA" ;
VAL_ 1997 brickVoltage261_BMS14 65535 "SNA" ;
VAL_ 1997 brickVoltage262_BMS14 65535 "SNA" ;
VAL_ 1997 brickVoltage263_BMS14 65535 "SNA" ;
VAL_ 1997 brickVoltage264_BMS14 65535 "SNA" ;
VAL_ 1997 brickVoltage265_BMS14 65535 "SNA" ;
VAL_ 1997 brickVoltage266_BMS14 65535 "SNA" ;
VAL_ 1997 brickVoltage267_BMS14 65535 "SNA" ;
VAL_ 1997 brickVoltage268_BMS14 65535 "SNA" ;
VAL_ 1997 brickVoltage269_BMS14 65535 "SNA" ;
VAL_ 1997 brickVoltage270_BMS14 65535 "SNA" ;
VAL_ 1997 brickVoltage271_BMS14 65535 "SNA" ;
VAL_ 1997 brickVoltage272_BMS14 65535 "SNA" ;
VAL_ 1997 brickVoltage273_BMS14 65535 "SNA" ;
VAL_ 1997 brickVoltage274_BMS14 65535 "SNA" ;
VAL_ 1997 brickVoltage275_BMS14 65535 "SNA" ;
VAL_ 1997 brickVoltage276_BMS14 65535 "SNA" ;
VAL_ 1997 brickVoltage277_BMS14 65535 "SNA" ;
VAL_ 1997 brickVoltage278_BMS14 65535 "SNA" ;
VAL_ 1997 brickVoltage279_BMS14 65535 "SNA" ;
VAL_ 1997 brickVoltage280_BMS14 65535 "SNA" ;
VAL_ 1997 brickVoltage281_BMS14 65535 "SNA" ;
VAL_ 1997 brickVoltage282_BMS14 65535 "SNA" ;
VAL_ 1997 brickVoltage283_BMS14 65535 "SNA" ;
VAL_ 1997 brickVoltage284_BMS14 65535 "SNA" ;
VAL_ 1997 brickVoltage285_BMS14 65535 "SNA" ;
VAL_ 1997 brickVoltage286_BMS14 65535 "SNA" ;
VAL_ 1997 brickVoltage287_BMS14 65535 "SNA" ;
VAL_ 1997 brickVoltage288_BMS14 65535 "SNA" ;
VAL_ 1997 brickVoltage289_BMS14 65535 "SNA" ;
VAL_ 1997 brickVoltage290_BMS14 65535 "SNA" ;
VAL_ 1997 brickVoltage291_BMS14 65535 "SNA" ;
VAL_ 1997 brickVoltage292_BMS14 65535 "SNA" ;
VAL_ 1997 brickVoltage293_BMS14 65535 "SNA" ;
VAL_ 1997 brickVoltage294_BMS14 65535 "SNA" ;
VAL_ 1997 brickVoltage295_BMS14 65535 "SNA" ;
VAL_ 1997 brickVoltage296_BMS14 65535 "SNA" ;
VAL_ 1997 brickVoltage297_BMS14 65535 "SNA" ;
VAL_ 1997 brickVoltage298_BMS14 65535 "SNA" ;
VAL_ 1997 brickVoltage299_BMS14 65535 "SNA" ;
VAL_ 1997 brickVoltage300_BMS14 65535 "SNA" ;
VAL_ 1997 moduleTemperature33_BMS14 255 "SNA" ;
VAL_ 1997 moduleTemperature34_BMS14 255 "SNA" ;
VAL_ 1997 moduleTemperature35_BMS14 255 "SNA" ;
VAL_ 1997 moduleTemperature36_BMS14 255 "SNA" ;
VAL_ 1997 moduleTemperature37_BMS14 255 "SNA" ;
VAL_ 1997 moduleTemperature38_BMS14 255 "SNA" ;
VAL_ 1997 moduleTemperature39_BMS14 255 "SNA" ;
VAL_ 1997 moduleTemperature40_BMS14 255 "SNA" ;
VAL_ 1997 moduleTemperature41_BMS14 255 "SNA" ;
VAL_ 1997 moduleTemperature42_BMS14 255 "SNA" ;
VAL_ 1997 moduleTemperature43_BMS14 255 "SNA" ;
VAL_ 1997 moduleTemperature44_BMS14 255 "SNA" ;
VAL_ 1997 moduleTemperature45_BMS14 255 "SNA" ;
VAL_ 1997 moduleTemperature46_BMS14 255 "SNA" ;
VAL_ 1997 moduleTemperature47_BMS14 255 "SNA" ;
VAL_ 1997 moduleTemperature48_BMS14 255 "SNA" ;
VAL_ 1997 moduleTemperature49_BMS14 255 "SNA" ;
VAL_ 1997 moduleTemperature50_BMS14 255 "SNA" ;
VAL_ 1997 moduleTemperature51_BMS14 255 "SNA" ;
VAL_ 1997 moduleTemperature52_BMS14 255 "SNA" ;
VAL_ 1997 moduleTemperature53_BMS14 255 "SNA" ;
VAL_ 1997 moduleTemperature54_BMS14 255 "SNA" ;
VAL_ 1997 moduleTemperature55_BMS14 255 "SNA" ;
VAL_ 1997 moduleTemperature56_BMS14 255 "SNA" ;
VAL_ 1997 moduleTemperature57_BMS14 255 "SNA" ;
VAL_ 1997 moduleTemperature58_BMS14 255 "SNA" ;
VAL_ 1997 moduleTemperature59_BMS14 255 "SNA" ;
VAL_ 1997 moduleTemperature60_BMS14 255 "SNA" ;
VAL_ 1997 moduleTemperature61_BMS14 255 "SNA" ;
VAL_ 1997 moduleTemperature62_BMS14 255 "SNA" ;
VAL_ 1997 moduleTemperature63_BMS14 255 "SNA" ;
VAL_ 1997 moduleTemperature64_BMS14 255 "SNA" ;
VAL_ 1997 moduleTemperature65_BMS14 255 "SNA" ;
VAL_ 1997 moduleTemperature66_BMS14 255 "SNA" ;
VAL_ 1997 moduleTemperature67_BMS14 255 "SNA" ;
VAL_ 1997 moduleTemperature68_BMS14 255 "SNA" ;
VAL_ 1997 moduleTemperature69_BMS14 255 "SNA" ;
VAL_ 1997 moduleTemperature70_BMS14 255 "SNA" ;
VAL_ 1997 moduleTemperature71_BMS14 255 "SNA" ;
VAL_ 1997 moduleTemperature72_BMS14 255 "SNA" ;
VAL_ 1997 moduleTemperature73_BMS14 255 "SNA" ;
VAL_ 1997 moduleTemperature74_BMS14 255 "SNA" ;
VAL_ 1997 moduleTemperature75_BMS14 255 "SNA" ;
VAL_ 1997 moduleTemperature76_BMS14 255 "SNA" ;
VAL_ 1997 moduleTemperature77_BMS14 255 "SNA" ;
VAL_ 1997 moduleTemperature78_BMS14 255 "SNA" ;
VAL_ 1997 moduleTemperature79_BMS14 255 "SNA" ;
VAL_ 1997 moduleTemperature80_BMS14 255 "SNA" ;
VAL_ 1997 moduleTemperature81_BMS14 255 "SNA" ;
VAL_ 1997 moduleTemperature82_BMS14 255 "SNA" ;
VAL_ 1997 moduleTemperature83_BMS14 255 "SNA" ;
VAL_ 1997 moduleTemperature84_BMS14 255 "SNA" ;
VAL_ 1997 moduleTemperature85_BMS14 255 "SNA" ;
VAL_ 1997 moduleTemperature86_BMS14 255 "SNA" ;
VAL_ 1997 moduleTemperature87_BMS14 255 "SNA" ;
VAL_ 1997 moduleTemperature88_BMS14 255 "SNA" ;
VAL_ 1997 moduleTemperature89_BMS14 255 "SNA" ;
VAL_ 1997 moduleTemperature90_BMS14 255 "SNA" ;
VAL_ 1997 moduleTemperature91_BMS14 255 "SNA" ;
VAL_ 1997 moduleTemperature92_BMS14 255 "SNA" ;
VAL_ 1997 moduleTemperature93_BMS14 255 "SNA" ;
VAL_ 1997 moduleTemperature94_BMS14 255 "SNA" ;
VAL_ 1997 moduleTemperature95_BMS14 255 "SNA" ;
VAL_ 1997 moduleTemperature96_BMS14 255 "SNA" ;
VAL_ 1997 moduleTemperature97_BMS14 255 "SNA" ;
VAL_ 1997 moduleTemperature98_BMS14 255 "SNA" ;
VAL_ 1997 moduleTemperature99_BMS14 255 "SNA" ;
VAL_ 1997 moduleTemperature100_BMS14 255 "SNA" ;
